VERSION ""

NS_ :

BS_:

BU_: TCM_Diesel ECM_Diesel BECMB_EPM TCM ECM Generic_BCM GWM _delete APIM BCM DCDC_VQM PAM TSTR PCM

BO_ 90 Gear_Shift_by_Wire_HS1: 8 Generic_BCM
 SG_ BrkSwtchPos_B_ActlGsm : 7|1@0+ (1,0) [0|1] "SED"  TCM_Diesel,TCM
 SG_ TrnValidGearRq_D_Stat : 25|2@0+ (1,0) [0|3] "SED"  TCM_Diesel,TCM
 SG_ TrnGearRqCnt_B_Actl : 26|1@0+ (1,0) [0|1] "unitless"  TCM_Diesel,TCM
 SG_ TrnGearButtn_U_Actl : 23|8@0+ (0.05,0) [0|12.7] "VOLT"  TCM_Diesel,TCM
 SG_ TrnGearButtn_B_ActlR2 : 8|1@0+ (1,0) [0|1] "SED"  TCM_Diesel,TCM
 SG_ TrnGearButtn_B_ActlR1 : 9|1@0+ (1,0) [0|1] "SED"  TCM_Diesel,TCM
 SG_ TrnGearButtn_B_ActlR0 : 10|1@0+ (1,0) [0|1] "SED"  TCM_Diesel,TCM
 SG_ TrnGearButtn_B_ActlP2 : 11|1@0+ (1,0) [0|1] "SED"  TCM_Diesel,TCM
 SG_ TrnGearButtn_B_ActlP1 : 12|1@0+ (1,0) [0|1] "SED"  TCM_Diesel,TCM
 SG_ TrnGearButtn_B_ActlP0 : 13|1@0+ (1,0) [0|1] "SED"  TCM_Diesel,TCM
 SG_ TrnGearButtn_B_ActlN2 : 14|1@0+ (1,0) [0|1] "SED"  TCM_Diesel,TCM
 SG_ TrnGearButtn_B_ActlN1 : 15|1@0+ (1,0) [0|1] "SED"  TCM_Diesel,TCM
 SG_ TrnGearButtn_B_ActlN0 : 0|1@0+ (1,0) [0|1] "SED"  TCM_Diesel,TCM
 SG_ TrnGearButtn_B_ActlM2 : 1|1@0+ (1,0) [0|1] "SED"  TCM_Diesel,TCM
 SG_ TrnGearButtn_B_ActlM1 : 2|1@0+ (1,0) [0|1] "SED"  TCM_Diesel,TCM
 SG_ TrnGearButtn_B_ActlM0 : 3|1@0+ (1,0) [0|1] "SED"  TCM_Diesel,TCM
 SG_ TrnGearButtn_B_ActlD2 : 4|1@0+ (1,0) [0|1] "SED"  TCM_Diesel,TCM
 SG_ TrnGearButtn_B_ActlD1 : 5|1@0+ (1,0) [0|1] "SED"  TCM_Diesel,TCM
 SG_ TrnGearButtn_B_ActlD0 : 6|1@0+ (1,0) [0|1] "SED"  TCM_Diesel,TCM
 SG_ TrnGear_No_Cs : 39|8@0+ (1,0) [0|255] "Unitless"  TCM_Diesel,TCM
 SG_ TrnGear_No_Cnt : 47|4@0+ (1,0) [0|15] "Unitless"  TCM_Diesel,TCM
 SG_ TrnBtsiOvrrd_B_Stat : 43|1@0+ (1,0) [0|1] "SED"  TCM_Diesel,TCM
 SG_ DrQltyDrv_D_StatGsm : 42|3@0+ (1,0) [0|7] "SED"  TCM_Diesel,TCM
 SG_ TrnGsmNtmState_D_Actl : 55|2@0+ (1,0) [0|3] "SED"  TCM_Diesel,TCM
 SG_ TrnGear_D_RqDrv : 31|5@0+ (1,0) [0|31] "SED"  TCM_Diesel,TCM,BCM

BO_ 902 BodyGatewayData_HS1: 8 GWM
 SG_ PrmtrAlrmWarnRq_No_Actl_UB : 40|1@0+ (1,0) [0|1] "SED"  BCM
 SG_ PrmtrAlrmTrgRq_No_Actl_UB : 41|1@0+ (1,0) [0|1] "SED"  BCM
 SG_ PrmtrAlrmWarnRq_No_Actl : 63|8@0+ (1,0) [0|255] "unitless"  BCM
 SG_ PrmtrAlrmTrgRq_No_Actl : 55|8@0+ (1,0) [0|255] "unitless"  BCM
 SG_ PrmtrAlrmWarn_B_Rq_UB : 42|1@0+ (1,0) [0|1] "SED"  BCM
 SG_ RollCode_No_ActlRsm_UB : 43|1@0+ (1,0) [0|1] "SED"  BCM
 SG_ PrmtrAlrmTrg_B_Rq_UB : 46|1@0+ (1,0) [0|1] "SED"  BCM
 SG_ PanicRq_No_ActlRsm_UB : 44|1@0+ (1,0) [0|1] "SED"  BCM
 SG_ Panic_D_RqRsm_UB : 0|1@0+ (1,0) [0|1] "SED"  BCM
 SG_ CellLockRq_No_ActlRsm_UB : 45|1@0+ (1,0) [0|1] "SED"  BCM
 SG_ RollCode_No_ActlRsm : 31|16@0+ (1,0) [0|65535] "unitless"  BCM
 SG_ PrmtrAlrmWarn_B_Rq : 47|1@0+ (1,0) [0|1] "SED"  BCM
 SG_ PrmtrAlrmTrg_B_Rq : 2|1@0+ (1,0) [0|1] "SED"  BCM
 SG_ PanicRq_No_ActlRsm : 23|8@0+ (1,0) [0|255] "unitless"  BCM
 SG_ Panic_D_RqRsm : 4|2@0+ (1,0) [0|3] "SED"  BCM
 SG_ CellLockRq_No_ActlRsm : 15|8@0+ (1,0) [0|255] "unitless"  BCM
 SG_ CellLock_D_RqRsm : 7|3@0+ (1,0) [0|7] "SED"  BCM
 SG_ CellLock_D_RqRsm_UB : 1|1@0+ (1,0) [0|1] "SED"  BCM

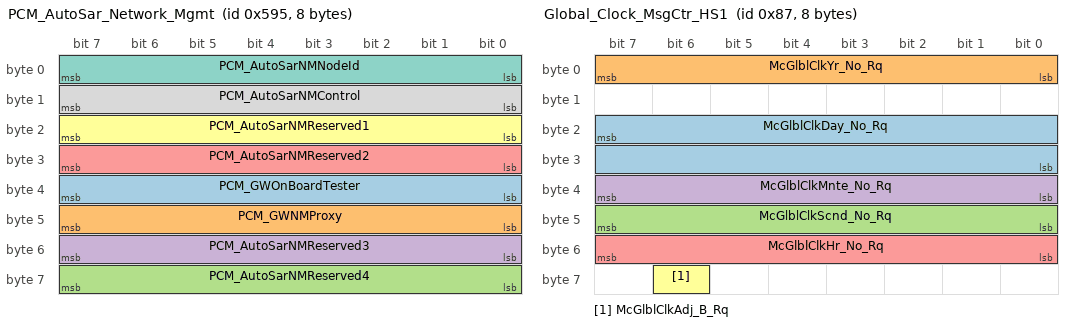
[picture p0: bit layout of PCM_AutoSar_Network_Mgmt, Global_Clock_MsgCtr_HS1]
BO_ 1429 PCM_AutoSar_Network_Mgmt: 8 PCM
 SG_ PCM_GWOnBoardTester : 39|8@0+ (1,0) [0|255] "unitless"  APIM,BCM,BECMB_EPM,GWM,TCM,TCM_Diesel
 SG_ PCM_GWNMProxy : 47|8@0+ (1,0) [0|255] "unitless"  APIM,BCM,BECMB_EPM,GWM,TCM,TCM_Diesel
 SG_ PCM_AutoSarNMReserved4 : 63|8@0+ (1,0) [0|255] "unitless"  APIM,BCM,BECMB_EPM,GWM,TCM,TCM_Diesel
 SG_ PCM_AutoSarNMReserved3 : 55|8@0+ (1,0) [0|255] "unitless"  APIM,BCM,BECMB_EPM,GWM,TCM,TCM_Diesel
 SG_ PCM_AutoSarNMReserved2 : 31|8@0+ (1,0) [0|255] "unitless"  APIM,BCM,BECMB_EPM,GWM,TCM,TCM_Diesel
 SG_ PCM_AutoSarNMReserved1 : 23|8@0+ (1,0) [0|255] "unitless"  APIM,BCM,BECMB_EPM,GWM,TCM,TCM_Diesel
 SG_ PCM_AutoSarNMNodeId : 7|8@0+ (1,0) [0|255] "unitless"  APIM,BCM,BECMB_EPM,GWM,TCM,TCM_Diesel
 SG_ PCM_AutoSarNMControl : 15|8@0+ (1,0) [0|255] "unitless"  APIM,BCM,BECMB_EPM,GWM,TCM,TCM_Diesel

BO_ 740 PHEV_Battery_Data1: 8 Generic_BCM
 SG_ PtWakeupActv2_B_Rq : 55|1@0+ (1,0) [0|1] "SED"  BCM

BO_ 748 BatteryCharge_Data1: 8 Generic_BCM
 SG_ PtWakeupActv3_B_Rq : 34|1@0+ (1,0) [0|1] "SED"  GWM,BCM

BO_ 389 PreCond_Hev_Data2: 8 Generic_BCM
 SG_ PreCondActv_B_Actl : 50|1@0+ (1,0) [0|1] "SED"  BCM,GWM

BO_ 135 Global_Clock_MsgCtr_HS1: 8 GWM
 SG_ McGlblClkDay_No_Rq : 23|16@0+ (1,0) [0|65535] "julian day"  BCM
 SG_ McGlblClkYr_No_Rq : 7|8@0+ (1,2000) [2000|2255] "year"  BCM
 SG_ McGlblClkScnd_No_Rq : 47|8@0+ (1,0) [0|255] "second"  BCM
 SG_ McGlblClkMnte_No_Rq : 39|8@0+ (1,0) [0|255] "minute"  BCM
 SG_ McGlblClkHr_No_Rq : 55|8@0+ (1,0) [0|255] "hour"  BCM
 SG_ McGlblClkAdj_B_Rq : 62|1@0+ (1,0) [0|1] "SED"  BCM

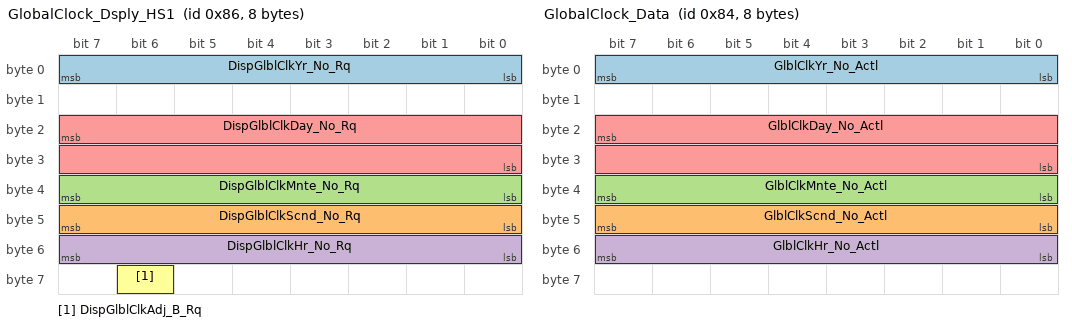
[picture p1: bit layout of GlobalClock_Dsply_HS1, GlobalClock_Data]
BO_ 134 GlobalClock_Dsply_HS1: 8 GWM
 SG_ DispGlblClkYr_No_Rq : 7|8@0+ (1,2000) [2000|2255] "year"  BCM
 SG_ DispGlblClkScnd_No_Rq : 47|8@0+ (1,0) [0|255] "second"  BCM
 SG_ DispGlblClkMnte_No_Rq : 39|8@0+ (1,0) [0|255] "minute"  BCM
 SG_ DispGlblClkHr_No_Rq : 55|8@0+ (1,0) [0|255] "hour"  BCM
 SG_ DispGlblClkDay_No_Rq : 23|16@0+ (1,0) [0|65535] "julian day"  BCM
 SG_ DispGlblClkAdj_B_Rq : 62|1@0+ (1,0) [0|1] "SED"  BCM

BO_ 132 GlobalClock_Data: 8 BCM
 SG_ GlblClkYr_No_Actl : 7|8@0+ (1,2000) [2000|2255] "year"  GWM
 SG_ GlblClkScnd_No_Actl : 47|8@0+ (1,0) [0|255] "second"  GWM
 SG_ GlblClkMnte_No_Actl : 39|8@0+ (1,0) [0|255] "minute"  GWM
 SG_ GlblClkHr_No_Actl : 55|8@0+ (1,0) [0|255] "hour"  GWM
 SG_ GlblClkDay_No_Actl : 23|16@0+ (1,0) [0|65535] "julian day"  GWM

BO_ 836 Climate_Fuel_Req_HS1: 8 GWM
 SG_ Foh_D_Stat : 19|3@0+ (1,0) [0|7] "SED"  BCM

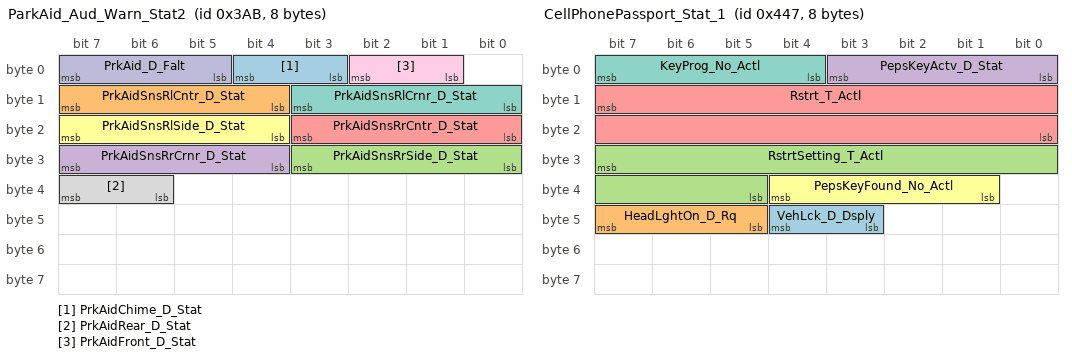
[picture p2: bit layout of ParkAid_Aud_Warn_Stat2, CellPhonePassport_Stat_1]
BO_ 939 ParkAid_Aud_Warn_Stat2: 8 PAM
 SG_ PrkAidChime_D_Stat : 4|2@0+ (1,0) [0|3] "SED"  GWM
 SG_ PrkAidSnsRlCntr_D_Stat : 15|4@0+ (1,0) [0|15] "SED"  BCM,GWM
 SG_ PrkAidSnsRrSide_D_Stat : 27|4@0+ (1,0) [0|15] "SED"  BCM,GWM
 SG_ PrkAidSnsRrCrnr_D_Stat : 31|4@0+ (1,0) [0|15] "SED"  BCM,GWM
 SG_ PrkAidSnsRrCntr_D_Stat : 19|4@0+ (1,0) [0|15] "SED"  BCM,GWM
 SG_ PrkAidSnsRlSide_D_Stat : 23|4@0+ (1,0) [0|15] "SED"  BCM,GWM
 SG_ PrkAidSnsRlCrnr_D_Stat : 11|4@0+ (1,0) [0|15] "SED"  BCM,GWM
 SG_ PrkAidRear_D_Stat : 39|2@0+ (1,0) [0|3] "SED"  GWM
 SG_ PrkAidFront_D_Stat : 2|2@0+ (1,0) [0|3] "SED"  GWM
 SG_ PrkAid_D_Falt : 7|3@0+ (1,0) [0|7] "SED"  BCM,GWM

BO_ 952 Tire_Pressure_Data_DRW: 8 BCM
 SG_ Tire_Press_IRR_Data : 23|16@0+ (1,0) [0|65533] "kilopascal"  GWM
 SG_ Tire_Press_ILR_Data : 7|16@0+ (1,0) [0|65533] "kilopascal"  GWM

BO_ 1095 CellPhonePassport_Stat_1: 8 BCM
 SG_ VehLck_D_Dsply : 44|2@0+ (1,0) [0|3] "SED"  GWM
 SG_ HeadLghtOn_D_Rq : 47|3@0+ (1,0) [0|7] "SED"  GWM
 SG_ RstrtSetting_T_Actl : 31|11@0+ (1,0) [0|2047] "second"  GWM
 SG_ PepsKeyActv_D_Stat : 3|4@0+ (1,0) [0|15] "SED"  GWM
 SG_ Rstrt_T_Actl : 15|16@0+ (1,0) [0|65535] "seconds"  GWM
 SG_ PepsKeyFound_No_Actl : 36|4@0+ (1,0) [0|15] "unitless"  GWM
 SG_ KeyProg_No_Actl : 7|4@0+ (1,0) [0|15] "unitless"  GWM

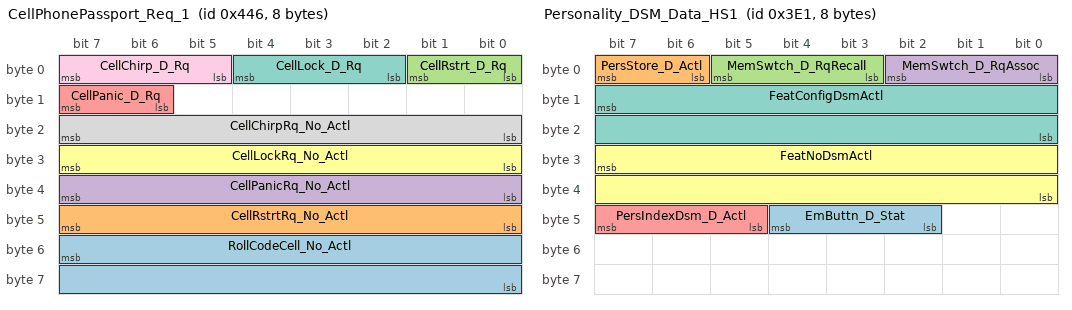
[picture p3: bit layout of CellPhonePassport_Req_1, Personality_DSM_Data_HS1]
BO_ 1094 CellPhonePassport_Req_1: 8 GWM
 SG_ RollCodeCell_No_Actl : 55|16@0+ (1,0) [0|65535] "unitless"  BCM
 SG_ CellRstrtRq_No_Actl : 47|8@0+ (1,0) [0|255] "unitless"  BCM
 SG_ CellRstrt_D_Rq : 1|2@0+ (1,0) [0|3] "SED"  BCM
 SG_ CellPanicRq_No_Actl : 39|8@0+ (1,0) [0|255] "unitless"  BCM
 SG_ CellPanic_D_Rq : 15|2@0+ (1,0) [0|3] "SED"  BCM
 SG_ CellLockRq_No_Actl : 31|8@0+ (1,0) [0|255] "unitless"  BCM
 SG_ CellLock_D_Rq : 4|3@0+ (1,0) [0|7] "SED"  BCM
 SG_ CellChirpRq_No_Actl : 23|8@0+ (1,0) [0|255] "unitless"  BCM
 SG_ CellChirp_D_Rq : 7|3@0+ (1,0) [0|7] "SED"  BCM

BO_ 320 LPwrSlideDr_Stat_HS1: 8 GWM
 SG_ PwSldDrIntSwL_B_Stat : 6|1@0+ (1,0) [0|1] "SED"  BCM
 SG_ LPwrSlideDr_Unlock_Rq : 7|1@0+ (1,0) [0|1] "SED"  BCM

BO_ 313 RPwrSlideDr_Stat_HS1: 8 GWM
 SG_ PwSldDrIntSwR_B_Stat : 6|1@0+ (1,0) [0|1] "SED"  BCM
 SG_ RPwrSlideDr_Unlock_Rq : 7|1@0+ (1,0) [0|1] "SED"  BCM

BO_ 993 Personality_DSM_Data_HS1: 8 GWM
 SG_ EmButtn_D_Stat : 44|3@0+ (1,0) [0|7] "SED" Vector__XXX
 SG_ PersStore_D_Actl : 7|2@0+ (1,0) [0|3] "SED" Vector__XXX
 SG_ MemSwtch_D_RqRecall : 5|3@0+ (1,0) [0|7] "SED"  BCM
 SG_ MemSwtch_D_RqAssoc : 2|3@0+ (1,0) [0|7] "SED"  BCM
 SG_ PersIndexDsm_D_Actl : 47|3@0+ (1,0) [0|7] "SED" Vector__XXX
 SG_ FeatNoDsmActl : 31|16@0+ (1,0) [0|65535] "Number" Vector__XXX
 SG_ FeatConfigDsmActl : 15|16@0+ (1,0) [0|65535] "Undefined" Vector__XXX

BO_ 131 Steering_Data_HS1: 8 GWM
 SG_ WiprFrontSwtch_D_Stat : 47|4@0+ (1,0) [0|15] "SED" Vector__XXX
 SG_ HeadLghtHiCtrl_D_RqAhb : 43|3@0+ (1,0) [0|7] "SED"  BCM
 SG_ HeadLghtHiOn_B_StatAhb : 34|1@0+ (1,0) [0|1] "SED" Vector__XXX
 SG_ AhbStat_B_Dsply : 33|1@0+ (1,0) [0|1] "SED" Vector__XXX
 SG_ HeadLghtHiFlash_D_Actl : 36|2@0+ (1,0) [0|3] "SED" Vector__XXX
 SG_ AccButtnGapIncPress : 11|1@0+ (1,0) [0|1] "SED" Vector__XXX
 SG_ AccButtnGapDecPress : 12|1@0+ (1,0) [0|1] "SED" Vector__XXX
 SG_ AslButtnOnOffPress : 9|1@0+ (1,0) [0|1] "SED"  ECM_Diesel,ECM,PCM
 SG_ AslButtnOnOffCnclPress : 10|1@0+ (1,0) [0|1] "SED"  ECM_Diesel,ECM,PCM
 SG_ CcButtnOnPress : 37|1@0+ (1,0) [0|1] "SED"  ECM_Diesel,ECM,PCM
 SG_ CcButtnOnOffPress : 38|1@0+ (1,0) [0|1] "SED"  ECM_Diesel,ECM,PCM
 SG_ CcButtnOnOffCnclPress : 39|1@0+ (1,0) [0|1] "SED"  ECM_Diesel,ECM,PCM
 SG_ CcButtnOffPress : 24|1@0+ (1,0) [0|1] "SED"  ECM_Diesel,ECM,PCM
 SG_ CcAsllButtnResPress : 25|1@0+ (1,0) [0|1] "SED"  ECM_Diesel,ECM,PCM
 SG_ CcAslButtnSetPress : 26|1@0+ (1,0) [0|1] "SED"  ECM_Diesel
 SG_ CcAslButtnSetIncPress : 27|1@0+ (1,0) [0|1] "SED"  ECM_Diesel,ECM,PCM
 SG_ CcAslButtnSetDecPress : 28|1@0+ (1,0) [0|1] "SED"  ECM_Diesel,ECM,PCM
 SG_ CcAslButtnResIncPress : 29|1@0+ (1,0) [0|1] "SED"  ECM_Diesel,ECM,PCM
 SG_ CcAslButtnResDecPress : 30|1@0+ (1,0) [0|1] "SED" Vector__XXX
 SG_ CcAslButtnOnPress : 31|1@0+ (1,0) [0|1] "SED"  ECM_Diesel,ECM,PCM
 SG_ CcAslButtnOnOffCncl : 16|1@0+ (1,0) [0|1] "SED" Vector__XXX
 SG_ CcAslButtnOffCnclPress : 17|1@0+ (1,0) [0|1] "SED" Vector__XXX
 SG_ CcAslButtnIndxIncPress : 18|1@0+ (1,0) [0|1] "SED"  ECM_Diesel,ECM,PCM
 SG_ CcAslButtnIndxDecPress : 19|1@0+ (1,0) [0|1] "SED"  ECM_Diesel,ECM,PCM
 SG_ CcAslButtnDeny_B_Actl : 20|1@0+ (1,0) [0|1] "SED"  ECM_Diesel,ECM,PCM
 SG_ CcAslButtnCnclResPress : 21|1@0+ (1,0) [0|1] "SED"  ECM_Diesel,ECM,PCM
 SG_ CcAslButtnCnclPress : 8|1@0+ (1,0) [0|1] "SED"  ECM_Diesel,ECM,PCM
 SG_ HeadLghtHiFlash_D_Stat : 7|2@0+ (1,0) [0|3] "SED"  BCM
 SG_ WiprFront_D_Stat : 3|4@0+ (1,0) [0|15] "SED"  ECM_Diesel,ECM,PCM,BCM
 SG_ TurnLghtSwtch_D_Stat : 5|2@0+ (1,0) [0|3] "SED"  BCM,PAM
 SG_ LghtAmb_D_Sns : 15|3@0+ (1,0) [0|7] "SED"  BCM
 SG_ LaSwtchPos_D_Stat : 23|2@0+ (1,0) [0|3] "SED" Vector__XXX

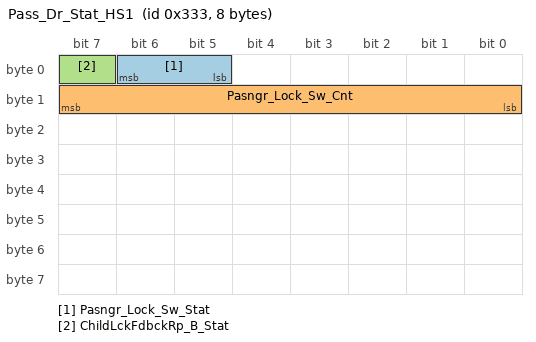
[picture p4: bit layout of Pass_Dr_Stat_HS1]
BO_ 819 Pass_Dr_Stat_HS1: 8 GWM
 SG_ Pasngr_Lock_Sw_Stat : 6|2@0+ (1,0) [0|3] "SED"  BCM
 SG_ Pasngr_Lock_Sw_Cnt : 15|8@0+ (1,0) [0|255] "Cnt"  BCM
 SG_ ChildLckFdbckRp_B_Stat : 7|1@0+ (1,0) [0|1] "SED"  BCM

BO_TX_BU_ 1429 : ECM_Diesel,ECM,PCM;
CM_ SG_ 90 BrkSwtchPos_B_ActlGsm "Signal not transmitted on vehicles that do not have shift by wire.";
CM_ SG_ 90 TrnValidGearRq_D_Stat "Signal not transmitted on vehicles that do not have shift by wire.";
CM_ SG_ 90 TrnGearRqCnt_B_Actl "Signal not transmitted on vehicles that do not have shift by wire.";
CM_ SG_ 90 TrnGearButtn_U_Actl "Signal not transmitted on vehicles that do not have shift by wire.";
CM_ SG_ 90 TrnGearButtn_B_ActlR2 "Signal not transmitted on vehicles that do not have shift by wire.";
CM_ SG_ 90 TrnGearButtn_B_ActlR1 "Signal not transmitted on vehicles that do not have shift by wire.";
CM_ SG_ 90 TrnGearButtn_B_ActlR0 "Signal not transmitted on vehicles that do not have shift by wire.";
CM_ SG_ 90 TrnGearButtn_B_ActlP2 "Signal not transmitted on vehicles that do not have shift by wire.";
CM_ SG_ 90 TrnGearButtn_B_ActlP1 "Signal not transmitted on vehicles that do not have shift by wire.";
CM_ SG_ 90 TrnGearButtn_B_ActlP0 "Signal not transmitted on vehicles that do not have shift by wire.";
CM_ SG_ 90 TrnGearButtn_B_ActlN2 "Signal not transmitted on vehicles that do not have shift by wire.";
CM_ SG_ 90 TrnGearButtn_B_ActlN1 "Signal not transmitted on vehicles that do not have shift by wire.";
CM_ SG_ 90 TrnGearButtn_B_ActlN0 "Signal not transmitted on vehicles that do not have shift by wire.";
CM_ SG_ 90 TrnGearButtn_B_ActlM2 "Signal not transmitted on vehicles that do not have shift by wire.";
CM_ SG_ 90 TrnGearButtn_B_ActlM1 "Signal not transmitted on vehicles that do not have shift by wire.";
CM_ SG_ 90 TrnGearButtn_B_ActlM0 "Signal not transmitted on vehicles that do not have shift by wire.";
CM_ SG_ 90 TrnGearButtn_B_ActlD2 "Signal not transmitted on vehicles that do not have shift by wire.";
CM_ SG_ 90 TrnGearButtn_B_ActlD1 "Signal not transmitted on vehicles that do not have shift by wire.";
CM_ SG_ 90 TrnGearButtn_B_ActlD0 "Signal not transmitted on vehicles that do not have shift by wire.";
CM_ SG_ 90 TrnGear_No_Cs "Signal not transmitted on vehicles that do not have shift by wire.";
CM_ SG_ 90 TrnGear_No_Cnt "Signal not transmitted on vehicles that do not have shift by wire.";
CM_ SG_ 90 TrnBtsiOvrrd_B_Stat "Signal not transmitted on vehicles that do not have shift by wire.";
CM_ SG_ 90 DrQltyDrv_D_StatGsm "Signal not transmitted on vehicles that do not have shift by wire.";
CM_ SG_ 90 TrnGsmNtmState_D_Actl "Signal not transmitted on vehicles that do not have shift by wire.";
CM_ SG_ 90 TrnGear_D_RqDrv "Signal not transmitted on vehicles that do not have shift by wire.";
CM_ SG_ 836 Foh_D_Stat "Signal not transmitted on vehicles that do not have the Fuel operated heater feature.";
CM_ SG_ 320 PwSldDrIntSwL_B_Stat "Signal not transmitted on vehicles without power sliding doors.";
CM_ SG_ 320 LPwrSlideDr_Unlock_Rq "Signal not transmitted on vehicles without power sliding doors.";
CM_ SG_ 313 PwSldDrIntSwR_B_Stat "Signal not transmitted on vehicles without power sliding doors.";
CM_ SG_ 313 RPwrSlideDr_Unlock_Rq "Signal not transmitted on vehicles without power sliding doors.";
BA_DEF_ SG_  "U_D568C_MY19_Gas_Rx" ENUM  "No","Yes";
BA_DEF_ SG_  "U_CD4_MY19_Diesel_Rx" ENUM  "No","Yes";
BA_DEF_ SG_  "U_CD4_MY19_Gas_Rx" ENUM  "No","Yes";
BA_DEF_ SG_  "U_CD4_MY19_Hev_Rx" ENUM  "No","Yes";
BA_DEF_ SG_  "U_CD4_MY19_Phev_Rx" ENUM  "No","Yes";
BA_DEF_ SG_  "U_V36X_MY19_Rx" ENUM  "No","Yes";
BA_DEF_ SG_  "U_D568C_MY19_Gas_Tx" ENUM  "No","Yes";
BA_DEF_ SG_  "U_CD4_MY19_Diesel_Tx" ENUM  "No","Yes";
BA_DEF_ SG_  "U_V36X_MY19_Tx" ENUM  "No","Yes";
BA_DEF_ SG_  "U_V36X_MY18_5_Gas_Rx" ENUM  "No","Yes";
BA_DEF_ SG_  "U_V36X_MY18_5_Hev_Rx" ENUM  "No","Yes";
BA_DEF_ SG_  "U_V36X_MY18_5_Gas_Tx" ENUM  "No","Yes";
BA_DEF_ SG_  "U_V36X_MY18_5_Hev_Tx" ENUM  "No","Yes";
BA_DEF_ SG_  "U_V36X_MY19_5_Diesel_Rx" ENUM  "No","Yes";
BA_DEF_ SG_  "U_V363E_N_MY19_5_20_Gas_Rx" ENUM  "No","Yes";
BA_DEF_ SG_  "U_V363E_N_MY19_5_20_Diesel_Rx" ENUM  "No","Yes";
BA_DEF_ SG_  "U_CD42_MY19_Diesel_Rx" ENUM  "No","Yes";
BA_DEF_ SG_  "U_V36X_MY19_5_Diesel_Tx" ENUM  "No","Yes";
BA_DEF_ SG_  "U_V363E_N_MY19_5_20_Gas_Tx" ENUM  "No","Yes";
BA_DEF_ SG_  "U_V363E_N_MY19_5_20_Diesel_Tx" ENUM  "No","Yes";
BA_DEF_ SG_  "U_CD42_MY19_Diesel_Tx" ENUM  "No","Yes";
BA_DEF_ SG_  "U_CD42_MY19_Gas_Tx" ENUM  "No","Yes";
BA_DEF_ SG_  "U_U502_MY17_Gas_Rx" ENUM  "No","Yes";
BA_DEF_ SG_  "U_CD4_MY18_Diesel_Rx" ENUM  "No","Yes";
BA_DEF_ SG_  "U_CD4_MY18_Gas_Rx" ENUM  "No","Yes";
BA_DEF_ SG_  "U_CD4_MY18_Hev_Rx" ENUM  "No","Yes";
BA_DEF_ SG_  "U_CD4_MY18_Phev_Rx" ENUM  "No","Yes";
BA_DEF_ SG_  "U_S550_MY18_Gas_Rx" ENUM  "No","Yes";
BA_DEF_ SG_  "U_V408_MY18_Gas_Rx" ENUM  "No","Yes";
BA_DEF_ SG_  "U_V408_MY18_Diesel_Rx" ENUM  "No","Yes";
BA_DEF_ SG_  "U_V36X_MY18_5_Diesel_Rx" ENUM  "No","Yes";
BA_DEF_ SG_  "U_P552_MY18_5_Gas_Rx" ENUM  "No","Yes";
BA_DEF_ SG_  "U_P552_MY18_5_Diesel_Rx" ENUM  "No","Yes";
BA_DEF_ SG_  "U_U502_MY17_Gas_Tx" ENUM  "No","Yes";
BA_DEF_ SG_  "U_CD4_MY18_Diesel_Tx" ENUM  "No","Yes";
BA_DEF_ SG_  "U_CD4_MY18_Gas_Tx" ENUM  "No","Yes";
BA_DEF_ SG_  "U_CD4_MY18_Hev_Tx" ENUM  "No","Yes";
BA_DEF_ SG_  "U_CD4_MY18_Phev_Tx" ENUM  "No","Yes";
BA_DEF_ SG_  "U_S550_MY18_Gas_Tx" ENUM  "No","Yes";
BA_DEF_ SG_  "U_V408_MY18_Gas_Tx" ENUM  "No","Yes";
BA_DEF_ SG_  "U_V408_MY18_Diesel_Tx" ENUM  "No","Yes";
BA_DEF_ SG_  "U_V36X_MY18_5_Diesel_Tx" ENUM  "No","Yes";
BA_DEF_ SG_  "U_P552_MY18_5_Gas_Tx" ENUM  "No","Yes";
BA_DEF_ SG_  "U_P552_MY18_5_Diesel_Tx" ENUM  "No","Yes";
BA_DEF_ SG_  "U_U55x_MY18_Gas_Rx" ENUM  "No","Yes";
BA_DEF_ SG_  "U_P552_MY18_Gas_Tx" ENUM  "No","Yes";
BA_DEF_ SG_  "U_U55x_MY18_Gas_Tx" ENUM  "No","Yes";
BA_DEF_ BO_  "FrameGatewayNetwork" STRING ;
BA_DEF_ SG_  "U_C489_MY17_Gas_Rx" ENUM  "No","Yes";
BA_DEF_ SG_  "U_CD43_MY17_Gas_Rx" ENUM  "No","Yes";
BA_DEF_ SG_  "U_CD43_MY17_Gas_Tx" ENUM  "No","Yes";
BA_DEF_ SG_  "U_P552_MY17_Gas_Tx" ENUM  "No","Yes";
BA_DEF_ SG_  "U_CD4_MY17_Diesel_Rx" ENUM  "No","Yes";
BA_DEF_ SG_  "U_CD4_MY17_Gas_Rx" ENUM  "No","Yes";
BA_DEF_ SG_  "U_CD4_MY17_Hev_Rx" ENUM  "No","Yes";
BA_DEF_ SG_  "U_C489_MY16_Gas_Rx" ENUM  "No","Yes";
BA_DEF_ SG_  "U_CD42_MY16_Diesel_Rx" ENUM  "No","Yes";
BA_DEF_ SG_  "U_CD42_MY16_Gas_Rx" ENUM  "No","Yes";
BA_DEF_ SG_  "U_CD42_MY15_Diesel_Rx" ENUM  "No","Yes";
BA_DEF_ SG_  "U_CD42_MY15_Gas_Rx" ENUM  "No","Yes";
BA_DEF_ SG_  "U_P558_MY17_Gas_Rx" ENUM  "No","Yes";
BA_DEF_ SG_  "U_P558_MY17_Diesel_Rx" ENUM  "No","Yes";
BA_DEF_ SG_  "U_P558_MY17_Gas_Tx" ENUM  "No","Yes";
BA_DEF_ SG_  "U_P558_MY17_Diesel_Tx" ENUM  "No","Yes";
BA_DEF_ SG_  "GenSigTimeoutTime_TCM" INT 0 100000;
BA_DEF_ BO_  "FrameGatewayMS1" HEX 0 1407;
BA_DEF_ BO_  "FrameGatewayHS3" HEX 0 1407;
BA_DEF_ BO_  "FrameGatewayHS2" HEX 0 1407;
BA_DEF_ BO_  "NetworkInitialization" ENUM  "No","Yes";
BA_DEF_ BO_  "FrameGatewayId" HEX 0 1407;
BA_DEF_ BO_  "GenMsgStartDelayTime" INT 0 10000;
BA_DEF_ BO_  "GenMsgCycleTime" INT 0 100000;
BA_DEF_ BO_  "GenMsgSendType" ENUM  "FixedPeriodic","Event","EnabledPeriodic","NotUsed","NotUsed","EventPeriodic","NotUsed","NotUsed","NoMsgSendType";
BA_DEF_ SG_  "U_CD4_MY14_Phev_Tx" ENUM  "No","Yes";
BA_DEF_ SG_  "U_CD4_MY14_Hev_Tx" ENUM  "No","Yes";
BA_DEF_ SG_  "U_CD4_MY14_Gas_Tx" ENUM  "No","Yes";
BA_DEF_ SG_  "U_CD4_MY14_Diesel_Tx" ENUM  "No","Yes";
BA_DEF_ SG_  "U_CD43_MY16_Gas_Tx" ENUM  "No","Yes";
BA_DEF_ SG_  "U_UP375_MY15_Diesel_Tx" ENUM  "No","Yes";
BA_DEF_ SG_  "U_UP375_MY15_Gas_Tx" ENUM  "No","Yes";
BA_DEF_ SG_  "U_U502_MY15_Gas_Tx" ENUM  "No","Yes";
BA_DEF_ SG_  "U_C489_MY14_Gas_Tx" ENUM  "No","Yes";
BA_DEF_ SG_  "U_S550_MY15_Gas_Tx" ENUM  "No","Yes";
BA_DEF_ SG_  "U_P552_MY15_Gas_Tx" ENUM  "No","Yes";
BA_DEF_ SG_  "U_CD42_MY14_Gas_Tx" ENUM  "No","Yes";
BA_DEF_ SG_  "U_CD42_MY14_Diesel_Tx" ENUM  "No","Yes";
BA_DEF_ SG_  "U_CD4_MY13_Phev_Tx" ENUM  "No","Yes";
BA_DEF_ SG_  "U_CD4_MY13_Hev_Tx" ENUM  "No","Yes";
BA_DEF_ SG_  "U_CD4_MY13_Gas_Tx" ENUM  "No","Yes";
BA_DEF_ SG_  "U_CD4_MY13_Diesel_Tx" ENUM  "No","Yes";
BA_DEF_ SG_  "U_CD4_MY14_Phev_Rx" ENUM  "No","Yes";
BA_DEF_ SG_  "U_CD4_MY14_Hev_Rx" ENUM  "No","Yes";
BA_DEF_ SG_  "U_CD4_MY14_Gas_Rx" ENUM  "No","Yes";
BA_DEF_ SG_  "U_CD4_MY14_Diesel_Rx" ENUM  "No","Yes";
BA_DEF_ SG_  "U_CD43_MY16_Gas_Rx" ENUM  "No","Yes";
BA_DEF_ SG_  "U_UP375_MY15_Diesel_Rx" ENUM  "No","Yes";
BA_DEF_ SG_  "U_UP375_MY15_Gas_Rx" ENUM  "No","Yes";
BA_DEF_ SG_  "U_U502_MY15_Gas_Rx" ENUM  "No","Yes";
BA_DEF_ SG_  "U_C489_MY14_Gas_Rx" ENUM  "No","Yes";
BA_DEF_ SG_  "U_S550_MY15_Gas_Rx" ENUM  "No","Yes";
BA_DEF_ SG_  "U_P552_MY15_Gas_Rx" ENUM  "No","Yes";
BA_DEF_ SG_  "U_CD42_MY14_Gas_Rx" ENUM  "No","Yes";
BA_DEF_ SG_  "U_CD42_MY14_Diesel_Rx" ENUM  "No","Yes";
BA_DEF_ SG_  "U_CD4_MY13_Phev_Rx" ENUM  "No","Yes";
BA_DEF_ SG_  "U_CD4_MY13_Hev_Rx" ENUM  "No","Yes";
BA_DEF_ SG_  "U_CD4_MY13_Gas_Rx" ENUM  "No","Yes";
BA_DEF_ SG_  "U_CD4_MY13_Diesel_Rx" ENUM  "No","Yes";
BA_DEF_ SG_  "ContentDependant" ENUM  "No","Yes";
BA_DEF_ SG_  "GenSigStartValue" INT 0 1000000000;
BA_DEF_ SG_  "CrossOver_InfoCAN" ENUM  "No","Yes";
BA_DEF_ SG_  "WakeupSignal" ENUM  "No","Yes";
BA_DEF_ SG_  "GenSigSendType" ENUM  "Cyclic","OnWrite","vector_leerstring","OnChange","vector_leerstring","IfActive","vector_leerstring","NoSigSendType";
BA_DEF_ BO_  "NmAsrMessage" ENUM  "No","Yes";
BA_DEF_ BO_  "GenMsgILSupport" ENUM  "No","Yes";
BA_DEF_DEF_  "U_D568C_MY19_Gas_Rx" "No";
BA_DEF_DEF_  "U_CD4_MY19_Diesel_Rx" "No";
BA_DEF_DEF_  "U_CD4_MY19_Gas_Rx" "No";
BA_DEF_DEF_  "U_CD4_MY19_Hev_Rx" "No";
BA_DEF_DEF_  "U_CD4_MY19_Phev_Rx" "No";
BA_DEF_DEF_  "U_V36X_MY19_Rx" "No";
BA_DEF_DEF_  "U_D568C_MY19_Gas_Tx" "No";
BA_DEF_DEF_  "U_CD4_MY19_Diesel_Tx" "No";
BA_DEF_DEF_  "U_V36X_MY19_Tx" "No";
BA_DEF_DEF_  "U_V36X_MY18_5_Gas_Rx" "No";
BA_DEF_DEF_  "U_V36X_MY18_5_Hev_Rx" "No";
BA_DEF_DEF_  "U_V36X_MY18_5_Gas_Tx" "No";
BA_DEF_DEF_  "U_V36X_MY18_5_Hev_Tx" "No";
BA_DEF_DEF_  "U_V36X_MY19_5_Diesel_Rx" "No";
BA_DEF_DEF_  "U_V363E_N_MY19_5_20_Gas_Rx" "No";
BA_DEF_DEF_  "U_V363E_N_MY19_5_20_Diesel_Rx" "No";
BA_DEF_DEF_  "U_CD42_MY19_Diesel_Rx" "No";
BA_DEF_DEF_  "U_V36X_MY19_5_Diesel_Tx" "No";
BA_DEF_DEF_  "U_V363E_N_MY19_5_20_Gas_Tx" "No";
BA_DEF_DEF_  "U_V363E_N_MY19_5_20_Diesel_Tx" "No";
BA_DEF_DEF_  "U_CD42_MY19_Diesel_Tx" "No";
BA_DEF_DEF_  "U_CD42_MY19_Gas_Tx" "No";
BA_DEF_DEF_  "U_U502_MY17_Gas_Rx" "No";
BA_DEF_DEF_  "U_CD4_MY18_Diesel_Rx" "No";
BA_DEF_DEF_  "U_CD4_MY18_Gas_Rx" "No";
BA_DEF_DEF_  "U_CD4_MY18_Hev_Rx" "No";
BA_DEF_DEF_  "U_CD4_MY18_Phev_Rx" "No";
BA_DEF_DEF_  "U_S550_MY18_Gas_Rx" "No";
BA_DEF_DEF_  "U_V408_MY18_Gas_Rx" "No";
BA_DEF_DEF_  "U_V408_MY18_Diesel_Rx" "No";
BA_DEF_DEF_  "U_V36X_MY18_5_Diesel_Rx" "No";
BA_DEF_DEF_  "U_P552_MY18_5_Gas_Rx" "No";
BA_DEF_DEF_  "U_P552_MY18_5_Diesel_Rx" "No";
BA_DEF_DEF_  "U_U502_MY17_Gas_Tx" "No";
BA_DEF_DEF_  "U_CD4_MY18_Diesel_Tx" "No";
BA_DEF_DEF_  "U_CD4_MY18_Gas_Tx" "No";
BA_DEF_DEF_  "U_CD4_MY18_Hev_Tx" "No";
BA_DEF_DEF_  "U_CD4_MY18_Phev_Tx" "No";
BA_DEF_DEF_  "U_S550_MY18_Gas_Tx" "No";
BA_DEF_DEF_  "U_V408_MY18_Gas_Tx" "No";
BA_DEF_DEF_  "U_V408_MY18_Diesel_Tx" "No";
BA_DEF_DEF_  "U_V36X_MY18_5_Diesel_Tx" "No";
BA_DEF_DEF_  "U_P552_MY18_5_Gas_Tx" "No";
BA_DEF_DEF_  "U_P552_MY18_5_Diesel_Tx" "No";
BA_DEF_DEF_  "U_U55x_MY18_Gas_Rx" "No";
BA_DEF_DEF_  "U_P552_MY18_Gas_Tx" "No";
BA_DEF_DEF_  "U_U55x_MY18_Gas_Tx" "No";
BA_DEF_DEF_  "FrameGatewayNetwork" "NONE";
BA_DEF_DEF_  "U_C489_MY17_Gas_Rx" "No";
BA_DEF_DEF_  "U_CD43_MY17_Gas_Rx" "No";
BA_DEF_DEF_  "U_CD43_MY17_Gas_Tx" "No";
BA_DEF_DEF_  "U_P552_MY17_Gas_Tx" "No";
BA_DEF_DEF_  "U_CD4_MY17_Diesel_Rx" "No";
BA_DEF_DEF_  "U_CD4_MY17_Gas_Rx" "No";
BA_DEF_DEF_  "U_CD4_MY17_Hev_Rx" "No";
BA_DEF_DEF_  "U_C489_MY16_Gas_Rx" "No";
BA_DEF_DEF_  "U_CD42_MY16_Diesel_Rx" "No";
BA_DEF_DEF_  "U_CD42_MY16_Gas_Rx" "No";
BA_DEF_DEF_  "U_CD42_MY15_Diesel_Rx" "No";
BA_DEF_DEF_  "U_CD42_MY15_Gas_Rx" "No";
BA_DEF_DEF_  "U_P558_MY17_Gas_Rx" "No";
BA_DEF_DEF_  "U_P558_MY17_Diesel_Rx" "No";
BA_DEF_DEF_  "U_P558_MY17_Gas_Tx" "No";
BA_DEF_DEF_  "U_P558_MY17_Diesel_Tx" "No";
BA_DEF_DEF_  "GenSigTimeoutTime_TCM" 5000;
BA_DEF_DEF_  "FrameGatewayMS1" 0;
BA_DEF_DEF_  "FrameGatewayHS3" 0;
BA_DEF_DEF_  "FrameGatewayHS2" 0;
BA_DEF_DEF_  "NetworkInitialization" "No";
BA_DEF_DEF_  "FrameGatewayId" 0;
BA_DEF_DEF_  "GenMsgStartDelayTime" 0;
BA_DEF_DEF_  "GenMsgCycleTime" 0;
BA_DEF_DEF_  "GenMsgSendType" "NoMsgSendType";
BA_DEF_DEF_  "U_CD4_MY14_Phev_Tx" "No";
BA_DEF_DEF_  "U_CD4_MY14_Hev_Tx" "No";
BA_DEF_DEF_  "U_CD4_MY14_Gas_Tx" "No";
BA_DEF_DEF_  "U_CD4_MY14_Diesel_Tx" "No";
BA_DEF_DEF_  "U_CD43_MY16_Gas_Tx" "No";
BA_DEF_DEF_  "U_UP375_MY15_Diesel_Tx" "No";
BA_DEF_DEF_  "U_UP375_MY15_Gas_Tx" "No";
BA_DEF_DEF_  "U_U502_MY15_Gas_Tx" "No";
BA_DEF_DEF_  "U_C489_MY14_Gas_Tx" "No";
BA_DEF_DEF_  "U_S550_MY15_Gas_Tx" "No";
BA_DEF_DEF_  "U_P552_MY15_Gas_Tx" "No";
BA_DEF_DEF_  "U_CD42_MY14_Gas_Tx" "No";
BA_DEF_DEF_  "U_CD42_MY14_Diesel_Tx" "No";
BA_DEF_DEF_  "U_CD4_MY13_Phev_Tx" "No";
BA_DEF_DEF_  "U_CD4_MY13_Hev_Tx" "No";
BA_DEF_DEF_  "U_CD4_MY13_Gas_Tx" "No";
BA_DEF_DEF_  "U_CD4_MY13_Diesel_Tx" "No";
BA_DEF_DEF_  "U_CD4_MY14_Phev_Rx" "No";
BA_DEF_DEF_  "U_CD4_MY14_Hev_Rx" "No";
BA_DEF_DEF_  "U_CD4_MY14_Gas_Rx" "No";
BA_DEF_DEF_  "U_CD4_MY14_Diesel_Rx" "No";
BA_DEF_DEF_  "U_CD43_MY16_Gas_Rx" "No";
BA_DEF_DEF_  "U_UP375_MY15_Diesel_Rx" "No";
BA_DEF_DEF_  "U_UP375_MY15_Gas_Rx" "No";
BA_DEF_DEF_  "U_U502_MY15_Gas_Rx" "No";
BA_DEF_DEF_  "U_C489_MY14_Gas_Rx" "No";
BA_DEF_DEF_  "U_S550_MY15_Gas_Rx" "No";
BA_DEF_DEF_  "U_P552_MY15_Gas_Rx" "No";
BA_DEF_DEF_  "U_CD42_MY14_Gas_Rx" "No";
BA_DEF_DEF_  "U_CD42_MY14_Diesel_Rx" "No";
BA_DEF_DEF_  "U_CD4_MY13_Phev_Rx" "No";
BA_DEF_DEF_  "U_CD4_MY13_Hev_Rx" "No";
BA_DEF_DEF_  "U_CD4_MY13_Gas_Rx" "No";
BA_DEF_DEF_  "U_CD4_MY13_Diesel_Rx" "No";
BA_DEF_DEF_  "ContentDependant" "No";
BA_DEF_DEF_  "GenSigStartValue" 0;
BA_DEF_DEF_  "CrossOver_InfoCAN" "No";
BA_DEF_DEF_  "WakeupSignal" "No";
BA_DEF_DEF_  "GenSigSendType" "NoSigSendType";
BA_DEF_DEF_  "NmAsrMessage" "No";
BA_DEF_DEF_  "GenMsgILSupport" "Yes";
BA_ "FrameGatewayHS2" BO_ 90 90;
BA_ "FrameGatewayId" BO_ 90 90;
BA_ "NetworkInitialization" BO_ 90 1;
BA_ "GenMsgSendType" BO_ 902 5;
BA_ "GenMsgCycleTime" BO_ 902 1000;
BA_ "GenMsgILSupport" BO_ 1429 0;
BA_ "NmAsrMessage" BO_ 1429 1;
BA_ "GenMsgSendType" BO_ 1429 0;
BA_ "GenMsgCycleTime" BO_ 1429 1000;
BA_ "FrameGatewayNetwork" BO_ 135 "HS3_CAN";
BA_ "GenMsgStartDelayTime" BO_ 135 100;
BA_ "FrameGatewayId" BO_ 135 135;
BA_ "FrameGatewayHS3" BO_ 135 135;
BA_ "FrameGatewayNetwork" BO_ 134 "HS3_CAN";
BA_ "GenMsgStartDelayTime" BO_ 134 100;
BA_ "FrameGatewayId" BO_ 134 134;
BA_ "FrameGatewayHS3" BO_ 134 134;
BA_ "GenMsgSendType" BO_ 132 1;
BA_ "FrameGatewayNetwork" BO_ 836 "MS1_CAN";
BA_ "GenMsgStartDelayTime" BO_ 836 100;
BA_ "FrameGatewayId" BO_ 836 836;
BA_ "FrameGatewayMS1" BO_ 836 836;
BA_ "GenMsgSendType" BO_ 939 5;
BA_ "GenMsgCycleTime" BO_ 939 200;
BA_ "GenMsgSendType" BO_ 952 0;
BA_ "GenMsgCycleTime" BO_ 952 500;
BA_ "GenMsgSendType" BO_ 1095 5;
BA_ "GenMsgCycleTime" BO_ 1095 1000;
BA_ "NetworkInitialization" BO_ 1095 1;
BA_ "FrameGatewayNetwork" BO_ 1094 "HS3_CAN";
BA_ "FrameGatewayId" BO_ 1094 1094;
BA_ "FrameGatewayHS3" BO_ 1094 1094;
BA_ "FrameGatewayNetwork" BO_ 320 "MS1_CAN";
BA_ "FrameGatewayId" BO_ 320 320;
BA_ "FrameGatewayMS1" BO_ 320 320;
BA_ "FrameGatewayNetwork" BO_ 313 "MS1_CAN";
BA_ "FrameGatewayId" BO_ 313 313;
BA_ "FrameGatewayMS1" BO_ 313 313;
BA_ "NetworkInitialization" BO_ 993 1;
BA_ "FrameGatewayNetwork" BO_ 993 "MS1_CAN";
BA_ "FrameGatewayId" BO_ 993 993;
BA_ "FrameGatewayMS1" BO_ 993 993;
BA_ "FrameGatewayNetwork" BO_ 131 "HS2_CAN";
BA_ "GenMsgStartDelayTime" BO_ 131 100;
BA_ "FrameGatewayId" BO_ 131 131;
BA_ "FrameGatewayHS2" BO_ 131 131;
BA_ "NetworkInitialization" BO_ 131 1;
BA_ "FrameGatewayNetwork" BO_ 819 "MS1_CAN";
BA_ "GenMsgStartDelayTime" BO_ 819 100;
BA_ "FrameGatewayId" BO_ 819 819;
BA_ "FrameGatewayMS1" BO_ 819 819;
BA_ "U_CD42_MY19_Diesel_Rx" SG_ 90 BrkSwtchPos_B_ActlGsm 1;
BA_ "U_CD4_MY18_Gas_Rx" SG_ 90 BrkSwtchPos_B_ActlGsm 1;
BA_ "U_U55x_MY18_Gas_Rx" SG_ 90 BrkSwtchPos_B_ActlGsm 1;
BA_ "U_CD43_MY17_Gas_Rx" SG_ 90 BrkSwtchPos_B_ActlGsm 1;
BA_ "U_CD42_MY16_Gas_Rx" SG_ 90 BrkSwtchPos_B_ActlGsm 1;
BA_ "U_C489_MY17_Gas_Rx" SG_ 90 BrkSwtchPos_B_ActlGsm 1;
BA_ "U_CD4_MY17_Hev_Rx" SG_ 90 BrkSwtchPos_B_ActlGsm 1;
BA_ "U_CD4_MY17_Gas_Rx" SG_ 90 BrkSwtchPos_B_ActlGsm 1;
BA_ "U_CD4_MY14_Hev_Rx" SG_ 90 BrkSwtchPos_B_ActlGsm 1;
BA_ "U_CD4_MY14_Gas_Rx" SG_ 90 BrkSwtchPos_B_ActlGsm 1;
BA_ "U_CD43_MY16_Gas_Rx" SG_ 90 BrkSwtchPos_B_ActlGsm 1;
BA_ "U_CD4_MY13_Hev_Rx" SG_ 90 BrkSwtchPos_B_ActlGsm 1;
BA_ "ContentDependant" SG_ 90 BrkSwtchPos_B_ActlGsm 1;
BA_ "U_CD42_MY19_Diesel_Rx" SG_ 90 TrnValidGearRq_D_Stat 1;
BA_ "U_CD4_MY18_Gas_Rx" SG_ 90 TrnValidGearRq_D_Stat 1;
BA_ "U_U55x_MY18_Gas_Rx" SG_ 90 TrnValidGearRq_D_Stat 1;
BA_ "U_CD43_MY17_Gas_Rx" SG_ 90 TrnValidGearRq_D_Stat 1;
BA_ "U_CD42_MY16_Gas_Rx" SG_ 90 TrnValidGearRq_D_Stat 1;
BA_ "U_C489_MY17_Gas_Rx" SG_ 90 TrnValidGearRq_D_Stat 1;
BA_ "U_CD4_MY17_Hev_Rx" SG_ 90 TrnValidGearRq_D_Stat 1;
BA_ "U_CD4_MY17_Gas_Rx" SG_ 90 TrnValidGearRq_D_Stat 1;
BA_ "U_CD4_MY14_Hev_Rx" SG_ 90 TrnValidGearRq_D_Stat 1;
BA_ "U_CD4_MY14_Gas_Rx" SG_ 90 TrnValidGearRq_D_Stat 1;
BA_ "U_CD43_MY16_Gas_Rx" SG_ 90 TrnValidGearRq_D_Stat 1;
BA_ "U_CD4_MY13_Hev_Rx" SG_ 90 TrnValidGearRq_D_Stat 1;
BA_ "ContentDependant" SG_ 90 TrnValidGearRq_D_Stat 1;
BA_ "U_CD42_MY19_Diesel_Rx" SG_ 90 TrnGearRqCnt_B_Actl 1;
BA_ "U_CD4_MY18_Gas_Rx" SG_ 90 TrnGearRqCnt_B_Actl 1;
BA_ "U_U55x_MY18_Gas_Rx" SG_ 90 TrnGearRqCnt_B_Actl 1;
BA_ "U_CD43_MY17_Gas_Rx" SG_ 90 TrnGearRqCnt_B_Actl 1;
BA_ "U_CD42_MY16_Gas_Rx" SG_ 90 TrnGearRqCnt_B_Actl 1;
BA_ "U_C489_MY17_Gas_Rx" SG_ 90 TrnGearRqCnt_B_Actl 1;
BA_ "U_CD4_MY17_Hev_Rx" SG_ 90 TrnGearRqCnt_B_Actl 1;
BA_ "U_CD4_MY17_Gas_Rx" SG_ 90 TrnGearRqCnt_B_Actl 1;
BA_ "U_CD4_MY14_Hev_Rx" SG_ 90 TrnGearRqCnt_B_Actl 1;
BA_ "U_CD4_MY14_Gas_Rx" SG_ 90 TrnGearRqCnt_B_Actl 1;
BA_ "U_CD43_MY16_Gas_Rx" SG_ 90 TrnGearRqCnt_B_Actl 1;
BA_ "U_CD4_MY13_Hev_Rx" SG_ 90 TrnGearRqCnt_B_Actl 1;
BA_ "ContentDependant" SG_ 90 TrnGearRqCnt_B_Actl 1;
BA_ "U_CD42_MY19_Diesel_Rx" SG_ 90 TrnGearButtn_U_Actl 1;
BA_ "U_U55x_MY18_Gas_Rx" SG_ 90 TrnGearButtn_U_Actl 1;
BA_ "ContentDependant" SG_ 90 TrnGearButtn_U_Actl 1;
BA_ "WakeupSignal" SG_ 90 TrnGearButtn_U_Actl 1;
BA_ "U_CD42_MY19_Diesel_Rx" SG_ 90 TrnGearButtn_B_ActlR2 1;
BA_ "U_CD4_MY18_Gas_Rx" SG_ 90 TrnGearButtn_B_ActlR2 1;
BA_ "U_U55x_MY18_Gas_Rx" SG_ 90 TrnGearButtn_B_ActlR2 1;
BA_ "U_CD43_MY17_Gas_Rx" SG_ 90 TrnGearButtn_B_ActlR2 1;
BA_ "U_CD42_MY16_Gas_Rx" SG_ 90 TrnGearButtn_B_ActlR2 1;
BA_ "U_C489_MY17_Gas_Rx" SG_ 90 TrnGearButtn_B_ActlR2 1;
BA_ "U_CD4_MY17_Hev_Rx" SG_ 90 TrnGearButtn_B_ActlR2 1;
BA_ "U_CD4_MY17_Gas_Rx" SG_ 90 TrnGearButtn_B_ActlR2 1;
BA_ "U_CD4_MY14_Hev_Rx" SG_ 90 TrnGearButtn_B_ActlR2 1;
BA_ "U_CD4_MY14_Gas_Rx" SG_ 90 TrnGearButtn_B_ActlR2 1;
BA_ "U_CD43_MY16_Gas_Rx" SG_ 90 TrnGearButtn_B_ActlR2 1;
BA_ "U_CD4_MY13_Hev_Rx" SG_ 90 TrnGearButtn_B_ActlR2 1;
BA_ "ContentDependant" SG_ 90 TrnGearButtn_B_ActlR2 1;
BA_ "WakeupSignal" SG_ 90 TrnGearButtn_B_ActlR2 1;
BA_ "U_CD42_MY19_Diesel_Rx" SG_ 90 TrnGearButtn_B_ActlR1 1;
BA_ "U_CD4_MY18_Gas_Rx" SG_ 90 TrnGearButtn_B_ActlR1 1;
BA_ "U_U55x_MY18_Gas_Rx" SG_ 90 TrnGearButtn_B_ActlR1 1;
BA_ "U_CD43_MY17_Gas_Rx" SG_ 90 TrnGearButtn_B_ActlR1 1;
BA_ "U_CD42_MY16_Gas_Rx" SG_ 90 TrnGearButtn_B_ActlR1 1;
BA_ "U_C489_MY17_Gas_Rx" SG_ 90 TrnGearButtn_B_ActlR1 1;
BA_ "U_CD4_MY17_Hev_Rx" SG_ 90 TrnGearButtn_B_ActlR1 1;
BA_ "U_CD4_MY17_Gas_Rx" SG_ 90 TrnGearButtn_B_ActlR1 1;
BA_ "U_CD4_MY14_Hev_Rx" SG_ 90 TrnGearButtn_B_ActlR1 1;
BA_ "U_CD4_MY14_Gas_Rx" SG_ 90 TrnGearButtn_B_ActlR1 1;
BA_ "U_CD43_MY16_Gas_Rx" SG_ 90 TrnGearButtn_B_ActlR1 1;
BA_ "U_CD4_MY13_Hev_Rx" SG_ 90 TrnGearButtn_B_ActlR1 1;
BA_ "ContentDependant" SG_ 90 TrnGearButtn_B_ActlR1 1;
BA_ "WakeupSignal" SG_ 90 TrnGearButtn_B_ActlR1 1;
BA_ "U_CD42_MY19_Diesel_Rx" SG_ 90 TrnGearButtn_B_ActlR0 1;
BA_ "U_CD4_MY18_Gas_Rx" SG_ 90 TrnGearButtn_B_ActlR0 1;
BA_ "U_U55x_MY18_Gas_Rx" SG_ 90 TrnGearButtn_B_ActlR0 1;
BA_ "U_CD43_MY17_Gas_Rx" SG_ 90 TrnGearButtn_B_ActlR0 1;
BA_ "U_CD42_MY16_Gas_Rx" SG_ 90 TrnGearButtn_B_ActlR0 1;
BA_ "U_C489_MY17_Gas_Rx" SG_ 90 TrnGearButtn_B_ActlR0 1;
BA_ "U_CD4_MY17_Hev_Rx" SG_ 90 TrnGearButtn_B_ActlR0 1;
BA_ "U_CD4_MY17_Gas_Rx" SG_ 90 TrnGearButtn_B_ActlR0 1;
BA_ "U_CD4_MY14_Hev_Rx" SG_ 90 TrnGearButtn_B_ActlR0 1;
BA_ "U_CD4_MY14_Gas_Rx" SG_ 90 TrnGearButtn_B_ActlR0 1;
BA_ "U_CD43_MY16_Gas_Rx" SG_ 90 TrnGearButtn_B_ActlR0 1;
BA_ "U_CD4_MY13_Hev_Rx" SG_ 90 TrnGearButtn_B_ActlR0 1;
BA_ "ContentDependant" SG_ 90 TrnGearButtn_B_ActlR0 1;
BA_ "WakeupSignal" SG_ 90 TrnGearButtn_B_ActlR0 1;
BA_ "U_CD42_MY19_Diesel_Rx" SG_ 90 TrnGearButtn_B_ActlP2 1;
BA_ "U_CD4_MY18_Gas_Rx" SG_ 90 TrnGearButtn_B_ActlP2 1;
BA_ "U_U55x_MY18_Gas_Rx" SG_ 90 TrnGearButtn_B_ActlP2 1;
BA_ "U_CD43_MY17_Gas_Rx" SG_ 90 TrnGearButtn_B_ActlP2 1;
BA_ "U_CD42_MY16_Gas_Rx" SG_ 90 TrnGearButtn_B_ActlP2 1;
BA_ "U_C489_MY17_Gas_Rx" SG_ 90 TrnGearButtn_B_ActlP2 1;
BA_ "U_CD4_MY17_Hev_Rx" SG_ 90 TrnGearButtn_B_ActlP2 1;
BA_ "U_CD4_MY17_Gas_Rx" SG_ 90 TrnGearButtn_B_ActlP2 1;
BA_ "U_CD4_MY14_Hev_Rx" SG_ 90 TrnGearButtn_B_ActlP2 1;
BA_ "U_CD4_MY14_Gas_Rx" SG_ 90 TrnGearButtn_B_ActlP2 1;
BA_ "U_CD43_MY16_Gas_Rx" SG_ 90 TrnGearButtn_B_ActlP2 1;
BA_ "U_CD4_MY13_Hev_Rx" SG_ 90 TrnGearButtn_B_ActlP2 1;
BA_ "ContentDependant" SG_ 90 TrnGearButtn_B_ActlP2 1;
BA_ "WakeupSignal" SG_ 90 TrnGearButtn_B_ActlP2 1;
BA_ "U_CD42_MY19_Diesel_Rx" SG_ 90 TrnGearButtn_B_ActlP1 1;
BA_ "U_CD4_MY18_Gas_Rx" SG_ 90 TrnGearButtn_B_ActlP1 1;
BA_ "U_U55x_MY18_Gas_Rx" SG_ 90 TrnGearButtn_B_ActlP1 1;
BA_ "U_CD43_MY17_Gas_Rx" SG_ 90 TrnGearButtn_B_ActlP1 1;
BA_ "U_CD42_MY16_Gas_Rx" SG_ 90 TrnGearButtn_B_ActlP1 1;
BA_ "U_C489_MY17_Gas_Rx" SG_ 90 TrnGearButtn_B_ActlP1 1;
BA_ "U_CD4_MY17_Hev_Rx" SG_ 90 TrnGearButtn_B_ActlP1 1;
BA_ "U_CD4_MY17_Gas_Rx" SG_ 90 TrnGearButtn_B_ActlP1 1;
BA_ "U_CD4_MY14_Hev_Rx" SG_ 90 TrnGearButtn_B_ActlP1 1;
BA_ "U_CD4_MY14_Gas_Rx" SG_ 90 TrnGearButtn_B_ActlP1 1;
BA_ "U_CD43_MY16_Gas_Rx" SG_ 90 TrnGearButtn_B_ActlP1 1;
BA_ "U_CD4_MY13_Hev_Rx" SG_ 90 TrnGearButtn_B_ActlP1 1;
BA_ "ContentDependant" SG_ 90 TrnGearButtn_B_ActlP1 1;
BA_ "WakeupSignal" SG_ 90 TrnGearButtn_B_ActlP1 1;
BA_ "U_CD42_MY19_Diesel_Rx" SG_ 90 TrnGearButtn_B_ActlP0 1;
BA_ "U_CD4_MY18_Gas_Rx" SG_ 90 TrnGearButtn_B_ActlP0 1;
BA_ "U_U55x_MY18_Gas_Rx" SG_ 90 TrnGearButtn_B_ActlP0 1;
BA_ "U_CD43_MY17_Gas_Rx" SG_ 90 TrnGearButtn_B_ActlP0 1;
BA_ "U_CD42_MY16_Gas_Rx" SG_ 90 TrnGearButtn_B_ActlP0 1;
BA_ "U_C489_MY17_Gas_Rx" SG_ 90 TrnGearButtn_B_ActlP0 1;
BA_ "U_CD4_MY17_Hev_Rx" SG_ 90 TrnGearButtn_B_ActlP0 1;
BA_ "U_CD4_MY17_Gas_Rx" SG_ 90 TrnGearButtn_B_ActlP0 1;
BA_ "U_CD4_MY14_Hev_Rx" SG_ 90 TrnGearButtn_B_ActlP0 1;
BA_ "U_CD4_MY14_Gas_Rx" SG_ 90 TrnGearButtn_B_ActlP0 1;
BA_ "U_CD43_MY16_Gas_Rx" SG_ 90 TrnGearButtn_B_ActlP0 1;
BA_ "U_CD4_MY13_Hev_Rx" SG_ 90 TrnGearButtn_B_ActlP0 1;
BA_ "ContentDependant" SG_ 90 TrnGearButtn_B_ActlP0 1;
BA_ "WakeupSignal" SG_ 90 TrnGearButtn_B_ActlP0 1;
BA_ "U_CD42_MY19_Diesel_Rx" SG_ 90 TrnGearButtn_B_ActlN2 1;
BA_ "U_CD4_MY18_Gas_Rx" SG_ 90 TrnGearButtn_B_ActlN2 1;
BA_ "U_U55x_MY18_Gas_Rx" SG_ 90 TrnGearButtn_B_ActlN2 1;
BA_ "U_CD43_MY17_Gas_Rx" SG_ 90 TrnGearButtn_B_ActlN2 1;
BA_ "U_CD42_MY16_Gas_Rx" SG_ 90 TrnGearButtn_B_ActlN2 1;
BA_ "U_C489_MY17_Gas_Rx" SG_ 90 TrnGearButtn_B_ActlN2 1;
BA_ "U_CD4_MY17_Hev_Rx" SG_ 90 TrnGearButtn_B_ActlN2 1;
BA_ "U_CD4_MY17_Gas_Rx" SG_ 90 TrnGearButtn_B_ActlN2 1;
BA_ "U_CD4_MY14_Hev_Rx" SG_ 90 TrnGearButtn_B_ActlN2 1;
BA_ "U_CD4_MY14_Gas_Rx" SG_ 90 TrnGearButtn_B_ActlN2 1;
BA_ "U_CD43_MY16_Gas_Rx" SG_ 90 TrnGearButtn_B_ActlN2 1;
BA_ "U_CD4_MY13_Hev_Rx" SG_ 90 TrnGearButtn_B_ActlN2 1;
BA_ "ContentDependant" SG_ 90 TrnGearButtn_B_ActlN2 1;
BA_ "WakeupSignal" SG_ 90 TrnGearButtn_B_ActlN2 1;
BA_ "U_CD42_MY19_Diesel_Rx" SG_ 90 TrnGearButtn_B_ActlN1 1;
BA_ "U_CD4_MY18_Gas_Rx" SG_ 90 TrnGearButtn_B_ActlN1 1;
BA_ "U_U55x_MY18_Gas_Rx" SG_ 90 TrnGearButtn_B_ActlN1 1;
BA_ "U_CD43_MY17_Gas_Rx" SG_ 90 TrnGearButtn_B_ActlN1 1;
BA_ "U_CD42_MY16_Gas_Rx" SG_ 90 TrnGearButtn_B_ActlN1 1;
BA_ "U_C489_MY17_Gas_Rx" SG_ 90 TrnGearButtn_B_ActlN1 1;
BA_ "U_CD4_MY17_Hev_Rx" SG_ 90 TrnGearButtn_B_ActlN1 1;
BA_ "U_CD4_MY17_Gas_Rx" SG_ 90 TrnGearButtn_B_ActlN1 1;
BA_ "U_CD4_MY14_Hev_Rx" SG_ 90 TrnGearButtn_B_ActlN1 1;
BA_ "U_CD4_MY14_Gas_Rx" SG_ 90 TrnGearButtn_B_ActlN1 1;
BA_ "U_CD43_MY16_Gas_Rx" SG_ 90 TrnGearButtn_B_ActlN1 1;
BA_ "U_CD4_MY13_Hev_Rx" SG_ 90 TrnGearButtn_B_ActlN1 1;
BA_ "ContentDependant" SG_ 90 TrnGearButtn_B_ActlN1 1;
BA_ "WakeupSignal" SG_ 90 TrnGearButtn_B_ActlN1 1;
BA_ "U_CD42_MY19_Diesel_Rx" SG_ 90 TrnGearButtn_B_ActlN0 1;
BA_ "U_CD4_MY18_Gas_Rx" SG_ 90 TrnGearButtn_B_ActlN0 1;
BA_ "U_U55x_MY18_Gas_Rx" SG_ 90 TrnGearButtn_B_ActlN0 1;
BA_ "U_CD43_MY17_Gas_Rx" SG_ 90 TrnGearButtn_B_ActlN0 1;
BA_ "U_CD42_MY16_Gas_Rx" SG_ 90 TrnGearButtn_B_ActlN0 1;
BA_ "U_C489_MY17_Gas_Rx" SG_ 90 TrnGearButtn_B_ActlN0 1;
BA_ "U_CD4_MY17_Hev_Rx" SG_ 90 TrnGearButtn_B_ActlN0 1;
BA_ "U_CD4_MY17_Gas_Rx" SG_ 90 TrnGearButtn_B_ActlN0 1;
BA_ "U_CD4_MY14_Hev_Rx" SG_ 90 TrnGearButtn_B_ActlN0 1;
BA_ "U_CD4_MY14_Gas_Rx" SG_ 90 TrnGearButtn_B_ActlN0 1;
BA_ "U_CD43_MY16_Gas_Rx" SG_ 90 TrnGearButtn_B_ActlN0 1;
BA_ "U_CD4_MY13_Hev_Rx" SG_ 90 TrnGearButtn_B_ActlN0 1;
BA_ "ContentDependant" SG_ 90 TrnGearButtn_B_ActlN0 1;
BA_ "WakeupSignal" SG_ 90 TrnGearButtn_B_ActlN0 1;
BA_ "U_CD42_MY19_Diesel_Rx" SG_ 90 TrnGearButtn_B_ActlM2 1;
BA_ "U_CD4_MY18_Gas_Rx" SG_ 90 TrnGearButtn_B_ActlM2 1;
BA_ "U_U55x_MY18_Gas_Rx" SG_ 90 TrnGearButtn_B_ActlM2 1;
BA_ "U_CD43_MY17_Gas_Rx" SG_ 90 TrnGearButtn_B_ActlM2 1;
BA_ "U_CD42_MY16_Gas_Rx" SG_ 90 TrnGearButtn_B_ActlM2 1;
BA_ "U_C489_MY17_Gas_Rx" SG_ 90 TrnGearButtn_B_ActlM2 1;
BA_ "U_CD4_MY17_Hev_Rx" SG_ 90 TrnGearButtn_B_ActlM2 1;
BA_ "U_CD4_MY17_Gas_Rx" SG_ 90 TrnGearButtn_B_ActlM2 1;
BA_ "U_CD4_MY14_Hev_Rx" SG_ 90 TrnGearButtn_B_ActlM2 1;
BA_ "U_CD4_MY14_Gas_Rx" SG_ 90 TrnGearButtn_B_ActlM2 1;
BA_ "U_CD43_MY16_Gas_Rx" SG_ 90 TrnGearButtn_B_ActlM2 1;
BA_ "U_CD4_MY13_Hev_Rx" SG_ 90 TrnGearButtn_B_ActlM2 1;
BA_ "ContentDependant" SG_ 90 TrnGearButtn_B_ActlM2 1;
BA_ "WakeupSignal" SG_ 90 TrnGearButtn_B_ActlM2 1;
BA_ "U_CD42_MY19_Diesel_Rx" SG_ 90 TrnGearButtn_B_ActlM1 1;
BA_ "U_CD4_MY18_Gas_Rx" SG_ 90 TrnGearButtn_B_ActlM1 1;
BA_ "U_U55x_MY18_Gas_Rx" SG_ 90 TrnGearButtn_B_ActlM1 1;
BA_ "U_CD43_MY17_Gas_Rx" SG_ 90 TrnGearButtn_B_ActlM1 1;
BA_ "U_CD42_MY16_Gas_Rx" SG_ 90 TrnGearButtn_B_ActlM1 1;
BA_ "U_C489_MY17_Gas_Rx" SG_ 90 TrnGearButtn_B_ActlM1 1;
BA_ "U_CD4_MY17_Hev_Rx" SG_ 90 TrnGearButtn_B_ActlM1 1;
BA_ "U_CD4_MY17_Gas_Rx" SG_ 90 TrnGearButtn_B_ActlM1 1;
BA_ "U_CD4_MY14_Hev_Rx" SG_ 90 TrnGearButtn_B_ActlM1 1;
BA_ "U_CD4_MY14_Gas_Rx" SG_ 90 TrnGearButtn_B_ActlM1 1;
BA_ "U_CD43_MY16_Gas_Rx" SG_ 90 TrnGearButtn_B_ActlM1 1;
BA_ "U_CD4_MY13_Hev_Rx" SG_ 90 TrnGearButtn_B_ActlM1 1;
BA_ "ContentDependant" SG_ 90 TrnGearButtn_B_ActlM1 1;
BA_ "WakeupSignal" SG_ 90 TrnGearButtn_B_ActlM1 1;
BA_ "U_CD42_MY19_Diesel_Rx" SG_ 90 TrnGearButtn_B_ActlM0 1;
BA_ "U_CD4_MY18_Gas_Rx" SG_ 90 TrnGearButtn_B_ActlM0 1;
BA_ "U_U55x_MY18_Gas_Rx" SG_ 90 TrnGearButtn_B_ActlM0 1;
BA_ "U_CD43_MY17_Gas_Rx" SG_ 90 TrnGearButtn_B_ActlM0 1;
BA_ "U_CD42_MY16_Gas_Rx" SG_ 90 TrnGearButtn_B_ActlM0 1;
BA_ "U_C489_MY17_Gas_Rx" SG_ 90 TrnGearButtn_B_ActlM0 1;
BA_ "U_CD4_MY17_Hev_Rx" SG_ 90 TrnGearButtn_B_ActlM0 1;
BA_ "U_CD4_MY17_Gas_Rx" SG_ 90 TrnGearButtn_B_ActlM0 1;
BA_ "U_CD4_MY14_Hev_Rx" SG_ 90 TrnGearButtn_B_ActlM0 1;
BA_ "U_CD4_MY14_Gas_Rx" SG_ 90 TrnGearButtn_B_ActlM0 1;
BA_ "U_CD43_MY16_Gas_Rx" SG_ 90 TrnGearButtn_B_ActlM0 1;
BA_ "U_CD4_MY13_Hev_Rx" SG_ 90 TrnGearButtn_B_ActlM0 1;
BA_ "ContentDependant" SG_ 90 TrnGearButtn_B_ActlM0 1;
BA_ "WakeupSignal" SG_ 90 TrnGearButtn_B_ActlM0 1;
BA_ "U_CD42_MY19_Diesel_Rx" SG_ 90 TrnGearButtn_B_ActlD2 1;
BA_ "U_CD4_MY18_Gas_Rx" SG_ 90 TrnGearButtn_B_ActlD2 1;
BA_ "U_U55x_MY18_Gas_Rx" SG_ 90 TrnGearButtn_B_ActlD2 1;
BA_ "U_CD43_MY17_Gas_Rx" SG_ 90 TrnGearButtn_B_ActlD2 1;
BA_ "U_CD42_MY16_Gas_Rx" SG_ 90 TrnGearButtn_B_ActlD2 1;
BA_ "U_C489_MY17_Gas_Rx" SG_ 90 TrnGearButtn_B_ActlD2 1;
BA_ "U_CD4_MY17_Hev_Rx" SG_ 90 TrnGearButtn_B_ActlD2 1;
BA_ "U_CD4_MY17_Gas_Rx" SG_ 90 TrnGearButtn_B_ActlD2 1;
BA_ "U_CD4_MY14_Hev_Rx" SG_ 90 TrnGearButtn_B_ActlD2 1;
BA_ "U_CD4_MY14_Gas_Rx" SG_ 90 TrnGearButtn_B_ActlD2 1;
BA_ "U_CD43_MY16_Gas_Rx" SG_ 90 TrnGearButtn_B_ActlD2 1;
BA_ "U_CD4_MY13_Hev_Rx" SG_ 90 TrnGearButtn_B_ActlD2 1;
BA_ "ContentDependant" SG_ 90 TrnGearButtn_B_ActlD2 1;
BA_ "WakeupSignal" SG_ 90 TrnGearButtn_B_ActlD2 1;
BA_ "U_CD42_MY19_Diesel_Rx" SG_ 90 TrnGearButtn_B_ActlD1 1;
BA_ "U_CD4_MY18_Gas_Rx" SG_ 90 TrnGearButtn_B_ActlD1 1;
BA_ "U_U55x_MY18_Gas_Rx" SG_ 90 TrnGearButtn_B_ActlD1 1;
BA_ "U_CD43_MY17_Gas_Rx" SG_ 90 TrnGearButtn_B_ActlD1 1;
BA_ "U_CD42_MY16_Gas_Rx" SG_ 90 TrnGearButtn_B_ActlD1 1;
BA_ "U_C489_MY17_Gas_Rx" SG_ 90 TrnGearButtn_B_ActlD1 1;
BA_ "U_CD4_MY17_Hev_Rx" SG_ 90 TrnGearButtn_B_ActlD1 1;
BA_ "U_CD4_MY17_Gas_Rx" SG_ 90 TrnGearButtn_B_ActlD1 1;
BA_ "U_CD4_MY14_Hev_Rx" SG_ 90 TrnGearButtn_B_ActlD1 1;
BA_ "U_CD4_MY14_Gas_Rx" SG_ 90 TrnGearButtn_B_ActlD1 1;
BA_ "U_CD43_MY16_Gas_Rx" SG_ 90 TrnGearButtn_B_ActlD1 1;
BA_ "U_CD4_MY13_Hev_Rx" SG_ 90 TrnGearButtn_B_ActlD1 1;
BA_ "ContentDependant" SG_ 90 TrnGearButtn_B_ActlD1 1;
BA_ "WakeupSignal" SG_ 90 TrnGearButtn_B_ActlD1 1;
BA_ "U_CD42_MY19_Diesel_Rx" SG_ 90 TrnGearButtn_B_ActlD0 1;
BA_ "U_CD4_MY18_Gas_Rx" SG_ 90 TrnGearButtn_B_ActlD0 1;
BA_ "U_U55x_MY18_Gas_Rx" SG_ 90 TrnGearButtn_B_ActlD0 1;
BA_ "U_CD43_MY17_Gas_Rx" SG_ 90 TrnGearButtn_B_ActlD0 1;
BA_ "U_CD42_MY16_Gas_Rx" SG_ 90 TrnGearButtn_B_ActlD0 1;
BA_ "U_C489_MY17_Gas_Rx" SG_ 90 TrnGearButtn_B_ActlD0 1;
BA_ "U_CD4_MY17_Hev_Rx" SG_ 90 TrnGearButtn_B_ActlD0 1;
BA_ "U_CD4_MY17_Gas_Rx" SG_ 90 TrnGearButtn_B_ActlD0 1;
BA_ "U_CD4_MY14_Hev_Rx" SG_ 90 TrnGearButtn_B_ActlD0 1;
BA_ "U_CD4_MY14_Gas_Rx" SG_ 90 TrnGearButtn_B_ActlD0 1;
BA_ "U_CD43_MY16_Gas_Rx" SG_ 90 TrnGearButtn_B_ActlD0 1;
BA_ "U_CD4_MY13_Hev_Rx" SG_ 90 TrnGearButtn_B_ActlD0 1;
BA_ "ContentDependant" SG_ 90 TrnGearButtn_B_ActlD0 1;
BA_ "WakeupSignal" SG_ 90 TrnGearButtn_B_ActlD0 1;
BA_ "U_CD42_MY19_Diesel_Rx" SG_ 90 TrnGear_No_Cs 1;
BA_ "U_CD4_MY18_Gas_Rx" SG_ 90 TrnGear_No_Cs 1;
BA_ "U_U55x_MY18_Gas_Rx" SG_ 90 TrnGear_No_Cs 1;
BA_ "U_CD43_MY17_Gas_Rx" SG_ 90 TrnGear_No_Cs 1;
BA_ "U_CD42_MY16_Gas_Rx" SG_ 90 TrnGear_No_Cs 1;
BA_ "U_C489_MY17_Gas_Rx" SG_ 90 TrnGear_No_Cs 1;
BA_ "U_CD4_MY17_Hev_Rx" SG_ 90 TrnGear_No_Cs 1;
BA_ "U_CD4_MY17_Gas_Rx" SG_ 90 TrnGear_No_Cs 1;
BA_ "U_CD4_MY14_Hev_Rx" SG_ 90 TrnGear_No_Cs 1;
BA_ "U_CD4_MY14_Gas_Rx" SG_ 90 TrnGear_No_Cs 1;
BA_ "U_CD43_MY16_Gas_Rx" SG_ 90 TrnGear_No_Cs 1;
BA_ "U_CD4_MY13_Hev_Rx" SG_ 90 TrnGear_No_Cs 1;
BA_ "ContentDependant" SG_ 90 TrnGear_No_Cs 1;
BA_ "WakeupSignal" SG_ 90 TrnGear_No_Cs 1;
BA_ "U_CD42_MY19_Diesel_Rx" SG_ 90 TrnGear_No_Cnt 1;
BA_ "U_CD4_MY18_Gas_Rx" SG_ 90 TrnGear_No_Cnt 1;
BA_ "U_U55x_MY18_Gas_Rx" SG_ 90 TrnGear_No_Cnt 1;
BA_ "U_CD43_MY17_Gas_Rx" SG_ 90 TrnGear_No_Cnt 1;
BA_ "U_CD42_MY16_Gas_Rx" SG_ 90 TrnGear_No_Cnt 1;
BA_ "U_C489_MY17_Gas_Rx" SG_ 90 TrnGear_No_Cnt 1;
BA_ "U_CD4_MY17_Hev_Rx" SG_ 90 TrnGear_No_Cnt 1;
BA_ "U_CD4_MY17_Gas_Rx" SG_ 90 TrnGear_No_Cnt 1;
BA_ "U_CD4_MY14_Hev_Rx" SG_ 90 TrnGear_No_Cnt 1;
BA_ "U_CD4_MY14_Gas_Rx" SG_ 90 TrnGear_No_Cnt 1;
BA_ "U_CD43_MY16_Gas_Rx" SG_ 90 TrnGear_No_Cnt 1;
BA_ "U_CD4_MY13_Hev_Rx" SG_ 90 TrnGear_No_Cnt 1;
BA_ "ContentDependant" SG_ 90 TrnGear_No_Cnt 1;
BA_ "U_CD42_MY19_Diesel_Rx" SG_ 90 TrnBtsiOvrrd_B_Stat 1;
BA_ "U_CD4_MY18_Gas_Rx" SG_ 90 TrnBtsiOvrrd_B_Stat 1;
BA_ "U_U55x_MY18_Gas_Rx" SG_ 90 TrnBtsiOvrrd_B_Stat 1;
BA_ "U_CD43_MY17_Gas_Rx" SG_ 90 TrnBtsiOvrrd_B_Stat 1;
BA_ "U_CD42_MY16_Gas_Rx" SG_ 90 TrnBtsiOvrrd_B_Stat 1;
BA_ "U_CD42_MY16_Diesel_Rx" SG_ 90 TrnBtsiOvrrd_B_Stat 1;
BA_ "U_C489_MY17_Gas_Rx" SG_ 90 TrnBtsiOvrrd_B_Stat 1;
BA_ "U_CD4_MY17_Hev_Rx" SG_ 90 TrnBtsiOvrrd_B_Stat 1;
BA_ "U_CD4_MY17_Gas_Rx" SG_ 90 TrnBtsiOvrrd_B_Stat 1;
BA_ "U_CD4_MY17_Diesel_Rx" SG_ 90 TrnBtsiOvrrd_B_Stat 1;
BA_ "U_CD4_MY14_Hev_Rx" SG_ 90 TrnBtsiOvrrd_B_Stat 1;
BA_ "U_CD4_MY14_Gas_Rx" SG_ 90 TrnBtsiOvrrd_B_Stat 1;
BA_ "U_CD4_MY14_Diesel_Rx" SG_ 90 TrnBtsiOvrrd_B_Stat 1;
BA_ "U_CD43_MY16_Gas_Rx" SG_ 90 TrnBtsiOvrrd_B_Stat 1;
BA_ "U_CD42_MY15_Diesel_Rx" SG_ 90 TrnBtsiOvrrd_B_Stat 1;
BA_ "U_CD4_MY13_Diesel_Rx" SG_ 90 TrnBtsiOvrrd_B_Stat 1;
BA_ "ContentDependant" SG_ 90 TrnBtsiOvrrd_B_Stat 1;
BA_ "U_CD42_MY19_Diesel_Rx" SG_ 90 DrQltyDrv_D_StatGsm 1;
BA_ "U_CD4_MY18_Gas_Rx" SG_ 90 DrQltyDrv_D_StatGsm 1;
BA_ "U_U55x_MY18_Gas_Rx" SG_ 90 DrQltyDrv_D_StatGsm 1;
BA_ "U_CD43_MY17_Gas_Rx" SG_ 90 DrQltyDrv_D_StatGsm 1;
BA_ "U_CD42_MY16_Gas_Rx" SG_ 90 DrQltyDrv_D_StatGsm 1;
BA_ "U_C489_MY17_Gas_Rx" SG_ 90 DrQltyDrv_D_StatGsm 1;
BA_ "U_CD4_MY17_Hev_Rx" SG_ 90 DrQltyDrv_D_StatGsm 1;
BA_ "U_CD4_MY17_Gas_Rx" SG_ 90 DrQltyDrv_D_StatGsm 1;
BA_ "U_CD4_MY14_Hev_Rx" SG_ 90 DrQltyDrv_D_StatGsm 1;
BA_ "U_CD4_MY14_Gas_Rx" SG_ 90 DrQltyDrv_D_StatGsm 1;
BA_ "U_CD43_MY16_Gas_Rx" SG_ 90 DrQltyDrv_D_StatGsm 1;
BA_ "ContentDependant" SG_ 90 DrQltyDrv_D_StatGsm 1;
BA_ "U_CD42_MY16_Gas_Rx" SG_ 90 TrnGsmNtmState_D_Actl 1;
BA_ "U_C489_MY16_Gas_Rx" SG_ 90 TrnGsmNtmState_D_Actl 1;
BA_ "U_CD4_MY17_Hev_Rx" SG_ 90 TrnGsmNtmState_D_Actl 1;
BA_ "U_CD4_MY17_Gas_Rx" SG_ 90 TrnGsmNtmState_D_Actl 1;
BA_ "U_CD4_MY14_Hev_Rx" SG_ 90 TrnGsmNtmState_D_Actl 1;
BA_ "U_CD4_MY14_Gas_Rx" SG_ 90 TrnGsmNtmState_D_Actl 1;
BA_ "U_CD43_MY16_Gas_Rx" SG_ 90 TrnGsmNtmState_D_Actl 1;
BA_ "U_C489_MY14_Gas_Rx" SG_ 90 TrnGsmNtmState_D_Actl 1;
BA_ "U_CD42_MY15_Gas_Rx" SG_ 90 TrnGsmNtmState_D_Actl 1;
BA_ "U_CD4_MY13_Hev_Rx" SG_ 90 TrnGsmNtmState_D_Actl 1;
BA_ "U_CD4_MY13_Gas_Rx" SG_ 90 TrnGsmNtmState_D_Actl 1;
BA_ "ContentDependant" SG_ 90 TrnGsmNtmState_D_Actl 1;
BA_ "CrossOver_InfoCAN" SG_ 90 TrnGsmNtmState_D_Actl 1;
BA_ "GenSigTimeoutTime_TCM" SG_ 90 TrnGsmNtmState_D_Actl 300;
BA_ "U_CD4_MY14_Phev_Rx" SG_ 90 TrnGear_D_RqDrv 1;
BA_ "U_CD4_MY14_Hev_Rx" SG_ 90 TrnGear_D_RqDrv 1;
BA_ "U_CD4_MY14_Gas_Rx" SG_ 90 TrnGear_D_RqDrv 1;
BA_ "U_CD4_MY14_Diesel_Rx" SG_ 90 TrnGear_D_RqDrv 1;
BA_ "U_CD43_MY16_Gas_Rx" SG_ 90 TrnGear_D_RqDrv 1;
BA_ "U_C489_MY14_Gas_Rx" SG_ 90 TrnGear_D_RqDrv 1;
BA_ "U_S550_MY15_Gas_Rx" SG_ 90 TrnGear_D_RqDrv 1;
BA_ "U_P552_MY15_Gas_Rx" SG_ 90 TrnGear_D_RqDrv 1;
BA_ "ContentDependant" SG_ 90 TrnGear_D_RqDrv 1;
BA_ "GenSigTimeoutTime_TCM" SG_ 90 TrnGear_D_RqDrv 300;
BA_ "U_CD42_MY14_Diesel_Rx" SG_ 902 PrmtrAlrmWarnRq_No_Actl_UB 1;
BA_ "U_CD42_MY14_Gas_Rx" SG_ 902 PrmtrAlrmWarnRq_No_Actl_UB 1;
BA_ "U_P552_MY15_Gas_Rx" SG_ 902 PrmtrAlrmWarnRq_No_Actl_UB 1;
BA_ "U_S550_MY15_Gas_Rx" SG_ 902 PrmtrAlrmWarnRq_No_Actl_UB 1;
BA_ "U_C489_MY14_Gas_Rx" SG_ 902 PrmtrAlrmWarnRq_No_Actl_UB 1;
BA_ "U_U502_MY15_Gas_Rx" SG_ 902 PrmtrAlrmWarnRq_No_Actl_UB 1;
BA_ "U_UP375_MY15_Gas_Rx" SG_ 902 PrmtrAlrmWarnRq_No_Actl_UB 1;
BA_ "U_UP375_MY15_Diesel_Rx" SG_ 902 PrmtrAlrmWarnRq_No_Actl_UB 1;
BA_ "U_CD43_MY16_Gas_Rx" SG_ 902 PrmtrAlrmWarnRq_No_Actl_UB 1;
BA_ "U_CD4_MY14_Diesel_Rx" SG_ 902 PrmtrAlrmWarnRq_No_Actl_UB 1;
BA_ "U_CD4_MY14_Gas_Rx" SG_ 902 PrmtrAlrmWarnRq_No_Actl_UB 1;
BA_ "U_CD4_MY14_Hev_Rx" SG_ 902 PrmtrAlrmWarnRq_No_Actl_UB 1;
BA_ "U_CD4_MY14_Phev_Rx" SG_ 902 PrmtrAlrmWarnRq_No_Actl_UB 1;
BA_ "U_CD42_MY14_Diesel_Rx" SG_ 902 PrmtrAlrmTrgRq_No_Actl_UB 1;
BA_ "U_CD42_MY14_Gas_Rx" SG_ 902 PrmtrAlrmTrgRq_No_Actl_UB 1;
BA_ "U_P552_MY15_Gas_Rx" SG_ 902 PrmtrAlrmTrgRq_No_Actl_UB 1;
BA_ "U_S550_MY15_Gas_Rx" SG_ 902 PrmtrAlrmTrgRq_No_Actl_UB 1;
BA_ "U_C489_MY14_Gas_Rx" SG_ 902 PrmtrAlrmTrgRq_No_Actl_UB 1;
BA_ "U_U502_MY15_Gas_Rx" SG_ 902 PrmtrAlrmTrgRq_No_Actl_UB 1;
BA_ "U_UP375_MY15_Gas_Rx" SG_ 902 PrmtrAlrmTrgRq_No_Actl_UB 1;
BA_ "U_UP375_MY15_Diesel_Rx" SG_ 902 PrmtrAlrmTrgRq_No_Actl_UB 1;
BA_ "U_CD43_MY16_Gas_Rx" SG_ 902 PrmtrAlrmTrgRq_No_Actl_UB 1;
BA_ "U_CD4_MY14_Diesel_Rx" SG_ 902 PrmtrAlrmTrgRq_No_Actl_UB 1;
BA_ "U_CD4_MY14_Gas_Rx" SG_ 902 PrmtrAlrmTrgRq_No_Actl_UB 1;
BA_ "U_CD4_MY14_Hev_Rx" SG_ 902 PrmtrAlrmTrgRq_No_Actl_UB 1;
BA_ "U_CD4_MY14_Phev_Rx" SG_ 902 PrmtrAlrmTrgRq_No_Actl_UB 1;
BA_ "WakeupSignal" SG_ 902 PrmtrAlrmWarnRq_No_Actl 1;
BA_ "GenSigSendType" SG_ 902 PrmtrAlrmWarnRq_No_Actl 3;
BA_ "U_CD42_MY14_Diesel_Rx" SG_ 902 PrmtrAlrmWarnRq_No_Actl 1;
BA_ "U_CD42_MY14_Gas_Rx" SG_ 902 PrmtrAlrmWarnRq_No_Actl 1;
BA_ "U_P552_MY15_Gas_Rx" SG_ 902 PrmtrAlrmWarnRq_No_Actl 1;
BA_ "U_S550_MY15_Gas_Rx" SG_ 902 PrmtrAlrmWarnRq_No_Actl 1;
BA_ "U_C489_MY14_Gas_Rx" SG_ 902 PrmtrAlrmWarnRq_No_Actl 1;
BA_ "U_U502_MY15_Gas_Rx" SG_ 902 PrmtrAlrmWarnRq_No_Actl 1;
BA_ "U_UP375_MY15_Gas_Rx" SG_ 902 PrmtrAlrmWarnRq_No_Actl 1;
BA_ "U_UP375_MY15_Diesel_Rx" SG_ 902 PrmtrAlrmWarnRq_No_Actl 1;
BA_ "U_CD43_MY16_Gas_Rx" SG_ 902 PrmtrAlrmWarnRq_No_Actl 1;
BA_ "U_CD4_MY14_Diesel_Rx" SG_ 902 PrmtrAlrmWarnRq_No_Actl 1;
BA_ "U_CD4_MY14_Gas_Rx" SG_ 902 PrmtrAlrmWarnRq_No_Actl 1;
BA_ "U_CD4_MY14_Hev_Rx" SG_ 902 PrmtrAlrmWarnRq_No_Actl 1;
BA_ "U_CD4_MY14_Phev_Rx" SG_ 902 PrmtrAlrmWarnRq_No_Actl 1;
BA_ "WakeupSignal" SG_ 902 PrmtrAlrmTrgRq_No_Actl 1;
BA_ "GenSigSendType" SG_ 902 PrmtrAlrmTrgRq_No_Actl 3;
BA_ "U_CD42_MY14_Diesel_Rx" SG_ 902 PrmtrAlrmTrgRq_No_Actl 1;
BA_ "U_CD42_MY14_Gas_Rx" SG_ 902 PrmtrAlrmTrgRq_No_Actl 1;
BA_ "U_P552_MY15_Gas_Rx" SG_ 902 PrmtrAlrmTrgRq_No_Actl 1;
BA_ "U_S550_MY15_Gas_Rx" SG_ 902 PrmtrAlrmTrgRq_No_Actl 1;
BA_ "U_C489_MY14_Gas_Rx" SG_ 902 PrmtrAlrmTrgRq_No_Actl 1;
BA_ "U_U502_MY15_Gas_Rx" SG_ 902 PrmtrAlrmTrgRq_No_Actl 1;
BA_ "U_UP375_MY15_Gas_Rx" SG_ 902 PrmtrAlrmTrgRq_No_Actl 1;
BA_ "U_UP375_MY15_Diesel_Rx" SG_ 902 PrmtrAlrmTrgRq_No_Actl 1;
BA_ "U_CD43_MY16_Gas_Rx" SG_ 902 PrmtrAlrmTrgRq_No_Actl 1;
BA_ "U_CD4_MY14_Diesel_Rx" SG_ 902 PrmtrAlrmTrgRq_No_Actl 1;
BA_ "U_CD4_MY14_Gas_Rx" SG_ 902 PrmtrAlrmTrgRq_No_Actl 1;
BA_ "U_CD4_MY14_Hev_Rx" SG_ 902 PrmtrAlrmTrgRq_No_Actl 1;
BA_ "U_CD4_MY14_Phev_Rx" SG_ 902 PrmtrAlrmTrgRq_No_Actl 1;
BA_ "U_CD4_MY13_Diesel_Rx" SG_ 902 PrmtrAlrmWarn_B_Rq_UB 1;
BA_ "U_CD4_MY13_Gas_Rx" SG_ 902 PrmtrAlrmWarn_B_Rq_UB 1;
BA_ "U_CD4_MY13_Hev_Rx" SG_ 902 PrmtrAlrmWarn_B_Rq_UB 1;
BA_ "U_CD4_MY13_Phev_Rx" SG_ 902 PrmtrAlrmWarn_B_Rq_UB 1;
BA_ "U_CD42_MY14_Diesel_Rx" SG_ 902 PrmtrAlrmWarn_B_Rq_UB 1;
BA_ "U_CD42_MY14_Gas_Rx" SG_ 902 PrmtrAlrmWarn_B_Rq_UB 1;
BA_ "U_P552_MY15_Gas_Rx" SG_ 902 PrmtrAlrmWarn_B_Rq_UB 1;
BA_ "U_S550_MY15_Gas_Rx" SG_ 902 PrmtrAlrmWarn_B_Rq_UB 1;
BA_ "U_C489_MY14_Gas_Rx" SG_ 902 PrmtrAlrmWarn_B_Rq_UB 1;
BA_ "U_U502_MY15_Gas_Rx" SG_ 902 PrmtrAlrmWarn_B_Rq_UB 1;
BA_ "U_UP375_MY15_Gas_Rx" SG_ 902 PrmtrAlrmWarn_B_Rq_UB 1;
BA_ "U_UP375_MY15_Diesel_Rx" SG_ 902 PrmtrAlrmWarn_B_Rq_UB 1;
BA_ "U_CD43_MY16_Gas_Rx" SG_ 902 PrmtrAlrmWarn_B_Rq_UB 1;
BA_ "U_CD4_MY14_Diesel_Rx" SG_ 902 PrmtrAlrmWarn_B_Rq_UB 1;
BA_ "U_CD4_MY14_Gas_Rx" SG_ 902 PrmtrAlrmWarn_B_Rq_UB 1;
BA_ "U_CD4_MY14_Hev_Rx" SG_ 902 PrmtrAlrmWarn_B_Rq_UB 1;
BA_ "U_CD4_MY14_Phev_Rx" SG_ 902 PrmtrAlrmWarn_B_Rq_UB 1;
BA_ "U_CD4_MY13_Diesel_Rx" SG_ 902 RollCode_No_ActlRsm_UB 1;
BA_ "U_CD4_MY13_Gas_Rx" SG_ 902 RollCode_No_ActlRsm_UB 1;
BA_ "U_CD4_MY13_Hev_Rx" SG_ 902 RollCode_No_ActlRsm_UB 1;
BA_ "U_CD4_MY13_Phev_Rx" SG_ 902 RollCode_No_ActlRsm_UB 1;
BA_ "U_CD42_MY14_Diesel_Rx" SG_ 902 RollCode_No_ActlRsm_UB 1;
BA_ "U_CD42_MY14_Gas_Rx" SG_ 902 RollCode_No_ActlRsm_UB 1;
BA_ "U_P552_MY15_Gas_Rx" SG_ 902 RollCode_No_ActlRsm_UB 1;
BA_ "U_S550_MY15_Gas_Rx" SG_ 902 RollCode_No_ActlRsm_UB 1;
BA_ "U_C489_MY14_Gas_Rx" SG_ 902 RollCode_No_ActlRsm_UB 1;
BA_ "U_U502_MY15_Gas_Rx" SG_ 902 RollCode_No_ActlRsm_UB 1;
BA_ "U_UP375_MY15_Gas_Rx" SG_ 902 RollCode_No_ActlRsm_UB 1;
BA_ "U_UP375_MY15_Diesel_Rx" SG_ 902 RollCode_No_ActlRsm_UB 1;
BA_ "U_CD43_MY16_Gas_Rx" SG_ 902 RollCode_No_ActlRsm_UB 1;
BA_ "U_CD4_MY14_Diesel_Rx" SG_ 902 RollCode_No_ActlRsm_UB 1;
BA_ "U_CD4_MY14_Gas_Rx" SG_ 902 RollCode_No_ActlRsm_UB 1;
BA_ "U_CD4_MY14_Hev_Rx" SG_ 902 RollCode_No_ActlRsm_UB 1;
BA_ "U_CD4_MY14_Phev_Rx" SG_ 902 RollCode_No_ActlRsm_UB 1;
BA_ "U_CD4_MY13_Diesel_Rx" SG_ 902 PrmtrAlrmTrg_B_Rq_UB 1;
BA_ "U_CD4_MY13_Gas_Rx" SG_ 902 PrmtrAlrmTrg_B_Rq_UB 1;
BA_ "U_CD4_MY13_Hev_Rx" SG_ 902 PrmtrAlrmTrg_B_Rq_UB 1;
BA_ "U_CD4_MY13_Phev_Rx" SG_ 902 PrmtrAlrmTrg_B_Rq_UB 1;
BA_ "U_CD42_MY14_Diesel_Rx" SG_ 902 PrmtrAlrmTrg_B_Rq_UB 1;
BA_ "U_CD42_MY14_Gas_Rx" SG_ 902 PrmtrAlrmTrg_B_Rq_UB 1;
BA_ "U_P552_MY15_Gas_Rx" SG_ 902 PrmtrAlrmTrg_B_Rq_UB 1;
BA_ "U_S550_MY15_Gas_Rx" SG_ 902 PrmtrAlrmTrg_B_Rq_UB 1;
BA_ "U_C489_MY14_Gas_Rx" SG_ 902 PrmtrAlrmTrg_B_Rq_UB 1;
BA_ "U_U502_MY15_Gas_Rx" SG_ 902 PrmtrAlrmTrg_B_Rq_UB 1;
BA_ "U_UP375_MY15_Gas_Rx" SG_ 902 PrmtrAlrmTrg_B_Rq_UB 1;
BA_ "U_UP375_MY15_Diesel_Rx" SG_ 902 PrmtrAlrmTrg_B_Rq_UB 1;
BA_ "U_CD43_MY16_Gas_Rx" SG_ 902 PrmtrAlrmTrg_B_Rq_UB 1;
BA_ "U_CD4_MY14_Diesel_Rx" SG_ 902 PrmtrAlrmTrg_B_Rq_UB 1;
BA_ "U_CD4_MY14_Gas_Rx" SG_ 902 PrmtrAlrmTrg_B_Rq_UB 1;
BA_ "U_CD4_MY14_Hev_Rx" SG_ 902 PrmtrAlrmTrg_B_Rq_UB 1;
BA_ "U_CD4_MY14_Phev_Rx" SG_ 902 PrmtrAlrmTrg_B_Rq_UB 1;
BA_ "U_CD4_MY13_Diesel_Rx" SG_ 902 PanicRq_No_ActlRsm_UB 1;
BA_ "U_CD4_MY13_Gas_Rx" SG_ 902 PanicRq_No_ActlRsm_UB 1;
BA_ "U_CD4_MY13_Hev_Rx" SG_ 902 PanicRq_No_ActlRsm_UB 1;
BA_ "U_CD4_MY13_Phev_Rx" SG_ 902 PanicRq_No_ActlRsm_UB 1;
BA_ "U_CD42_MY14_Diesel_Rx" SG_ 902 PanicRq_No_ActlRsm_UB 1;
BA_ "U_CD42_MY14_Gas_Rx" SG_ 902 PanicRq_No_ActlRsm_UB 1;
BA_ "U_P552_MY15_Gas_Rx" SG_ 902 PanicRq_No_ActlRsm_UB 1;
BA_ "U_S550_MY15_Gas_Rx" SG_ 902 PanicRq_No_ActlRsm_UB 1;
BA_ "U_C489_MY14_Gas_Rx" SG_ 902 PanicRq_No_ActlRsm_UB 1;
BA_ "U_U502_MY15_Gas_Rx" SG_ 902 PanicRq_No_ActlRsm_UB 1;
BA_ "U_UP375_MY15_Gas_Rx" SG_ 902 PanicRq_No_ActlRsm_UB 1;
BA_ "U_UP375_MY15_Diesel_Rx" SG_ 902 PanicRq_No_ActlRsm_UB 1;
BA_ "U_CD43_MY16_Gas_Rx" SG_ 902 PanicRq_No_ActlRsm_UB 1;
BA_ "U_CD4_MY14_Diesel_Rx" SG_ 902 PanicRq_No_ActlRsm_UB 1;
BA_ "U_CD4_MY14_Gas_Rx" SG_ 902 PanicRq_No_ActlRsm_UB 1;
BA_ "U_CD4_MY14_Hev_Rx" SG_ 902 PanicRq_No_ActlRsm_UB 1;
BA_ "U_CD4_MY14_Phev_Rx" SG_ 902 PanicRq_No_ActlRsm_UB 1;
BA_ "U_CD4_MY13_Diesel_Rx" SG_ 902 Panic_D_RqRsm_UB 1;
BA_ "U_CD4_MY13_Gas_Rx" SG_ 902 Panic_D_RqRsm_UB 1;
BA_ "U_CD4_MY13_Hev_Rx" SG_ 902 Panic_D_RqRsm_UB 1;
BA_ "U_CD4_MY13_Phev_Rx" SG_ 902 Panic_D_RqRsm_UB 1;
BA_ "U_CD42_MY14_Diesel_Rx" SG_ 902 Panic_D_RqRsm_UB 1;
BA_ "U_CD42_MY14_Gas_Rx" SG_ 902 Panic_D_RqRsm_UB 1;
BA_ "U_P552_MY15_Gas_Rx" SG_ 902 Panic_D_RqRsm_UB 1;
BA_ "U_S550_MY15_Gas_Rx" SG_ 902 Panic_D_RqRsm_UB 1;
BA_ "U_C489_MY14_Gas_Rx" SG_ 902 Panic_D_RqRsm_UB 1;
BA_ "U_U502_MY15_Gas_Rx" SG_ 902 Panic_D_RqRsm_UB 1;
BA_ "U_UP375_MY15_Gas_Rx" SG_ 902 Panic_D_RqRsm_UB 1;
BA_ "U_UP375_MY15_Diesel_Rx" SG_ 902 Panic_D_RqRsm_UB 1;
BA_ "U_CD43_MY16_Gas_Rx" SG_ 902 Panic_D_RqRsm_UB 1;
BA_ "U_CD4_MY14_Diesel_Rx" SG_ 902 Panic_D_RqRsm_UB 1;
BA_ "U_CD4_MY14_Gas_Rx" SG_ 902 Panic_D_RqRsm_UB 1;
BA_ "U_CD4_MY14_Hev_Rx" SG_ 902 Panic_D_RqRsm_UB 1;
BA_ "U_CD4_MY14_Phev_Rx" SG_ 902 Panic_D_RqRsm_UB 1;
BA_ "U_CD4_MY13_Diesel_Rx" SG_ 902 CellLockRq_No_ActlRsm_UB 1;
BA_ "U_CD4_MY13_Gas_Rx" SG_ 902 CellLockRq_No_ActlRsm_UB 1;
BA_ "U_CD4_MY13_Hev_Rx" SG_ 902 CellLockRq_No_ActlRsm_UB 1;
BA_ "U_CD4_MY13_Phev_Rx" SG_ 902 CellLockRq_No_ActlRsm_UB 1;
BA_ "U_CD42_MY14_Diesel_Rx" SG_ 902 CellLockRq_No_ActlRsm_UB 1;
BA_ "U_CD42_MY14_Gas_Rx" SG_ 902 CellLockRq_No_ActlRsm_UB 1;
BA_ "U_P552_MY15_Gas_Rx" SG_ 902 CellLockRq_No_ActlRsm_UB 1;
BA_ "U_S550_MY15_Gas_Rx" SG_ 902 CellLockRq_No_ActlRsm_UB 1;
BA_ "U_C489_MY14_Gas_Rx" SG_ 902 CellLockRq_No_ActlRsm_UB 1;
BA_ "U_U502_MY15_Gas_Rx" SG_ 902 CellLockRq_No_ActlRsm_UB 1;
BA_ "U_UP375_MY15_Gas_Rx" SG_ 902 CellLockRq_No_ActlRsm_UB 1;
BA_ "U_UP375_MY15_Diesel_Rx" SG_ 902 CellLockRq_No_ActlRsm_UB 1;
BA_ "U_CD43_MY16_Gas_Rx" SG_ 902 CellLockRq_No_ActlRsm_UB 1;
BA_ "U_CD4_MY14_Diesel_Rx" SG_ 902 CellLockRq_No_ActlRsm_UB 1;
BA_ "U_CD4_MY14_Gas_Rx" SG_ 902 CellLockRq_No_ActlRsm_UB 1;
BA_ "U_CD4_MY14_Hev_Rx" SG_ 902 CellLockRq_No_ActlRsm_UB 1;
BA_ "U_CD4_MY14_Phev_Rx" SG_ 902 CellLockRq_No_ActlRsm_UB 1;
BA_ "WakeupSignal" SG_ 902 RollCode_No_ActlRsm 1;
BA_ "GenSigSendType" SG_ 902 RollCode_No_ActlRsm 3;
BA_ "U_CD4_MY13_Diesel_Rx" SG_ 902 RollCode_No_ActlRsm 1;
BA_ "U_CD4_MY13_Gas_Rx" SG_ 902 RollCode_No_ActlRsm 1;
BA_ "U_CD4_MY13_Hev_Rx" SG_ 902 RollCode_No_ActlRsm 1;
BA_ "U_CD4_MY13_Phev_Rx" SG_ 902 RollCode_No_ActlRsm 1;
BA_ "U_CD42_MY14_Diesel_Rx" SG_ 902 RollCode_No_ActlRsm 1;
BA_ "U_CD42_MY14_Gas_Rx" SG_ 902 RollCode_No_ActlRsm 1;
BA_ "U_P552_MY15_Gas_Rx" SG_ 902 RollCode_No_ActlRsm 1;
BA_ "U_S550_MY15_Gas_Rx" SG_ 902 RollCode_No_ActlRsm 1;
BA_ "U_C489_MY14_Gas_Rx" SG_ 902 RollCode_No_ActlRsm 1;
BA_ "U_U502_MY15_Gas_Rx" SG_ 902 RollCode_No_ActlRsm 1;
BA_ "U_UP375_MY15_Gas_Rx" SG_ 902 RollCode_No_ActlRsm 1;
BA_ "U_UP375_MY15_Diesel_Rx" SG_ 902 RollCode_No_ActlRsm 1;
BA_ "U_CD43_MY16_Gas_Rx" SG_ 902 RollCode_No_ActlRsm 1;
BA_ "U_CD4_MY14_Diesel_Rx" SG_ 902 RollCode_No_ActlRsm 1;
BA_ "U_CD4_MY14_Gas_Rx" SG_ 902 RollCode_No_ActlRsm 1;
BA_ "U_CD4_MY14_Hev_Rx" SG_ 902 RollCode_No_ActlRsm 1;
BA_ "U_CD4_MY14_Phev_Rx" SG_ 902 RollCode_No_ActlRsm 1;
BA_ "WakeupSignal" SG_ 902 PrmtrAlrmWarn_B_Rq 1;
BA_ "GenSigSendType" SG_ 902 PrmtrAlrmWarn_B_Rq 3;
BA_ "U_CD4_MY13_Diesel_Rx" SG_ 902 PrmtrAlrmWarn_B_Rq 1;
BA_ "U_CD4_MY13_Gas_Rx" SG_ 902 PrmtrAlrmWarn_B_Rq 1;
BA_ "U_CD4_MY13_Hev_Rx" SG_ 902 PrmtrAlrmWarn_B_Rq 1;
BA_ "U_CD4_MY13_Phev_Rx" SG_ 902 PrmtrAlrmWarn_B_Rq 1;
BA_ "U_CD42_MY14_Diesel_Rx" SG_ 902 PrmtrAlrmWarn_B_Rq 1;
BA_ "U_CD42_MY14_Gas_Rx" SG_ 902 PrmtrAlrmWarn_B_Rq 1;
BA_ "U_P552_MY15_Gas_Rx" SG_ 902 PrmtrAlrmWarn_B_Rq 1;
BA_ "U_S550_MY15_Gas_Rx" SG_ 902 PrmtrAlrmWarn_B_Rq 1;
BA_ "U_C489_MY14_Gas_Rx" SG_ 902 PrmtrAlrmWarn_B_Rq 1;
BA_ "U_U502_MY15_Gas_Rx" SG_ 902 PrmtrAlrmWarn_B_Rq 1;
BA_ "U_UP375_MY15_Gas_Rx" SG_ 902 PrmtrAlrmWarn_B_Rq 1;
BA_ "U_UP375_MY15_Diesel_Rx" SG_ 902 PrmtrAlrmWarn_B_Rq 1;
BA_ "U_CD43_MY16_Gas_Rx" SG_ 902 PrmtrAlrmWarn_B_Rq 1;
BA_ "U_CD4_MY14_Diesel_Rx" SG_ 902 PrmtrAlrmWarn_B_Rq 1;
BA_ "U_CD4_MY14_Gas_Rx" SG_ 902 PrmtrAlrmWarn_B_Rq 1;
BA_ "U_CD4_MY14_Hev_Rx" SG_ 902 PrmtrAlrmWarn_B_Rq 1;
BA_ "U_CD4_MY14_Phev_Rx" SG_ 902 PrmtrAlrmWarn_B_Rq 1;
BA_ "WakeupSignal" SG_ 902 PrmtrAlrmTrg_B_Rq 1;
BA_ "GenSigSendType" SG_ 902 PrmtrAlrmTrg_B_Rq 3;
BA_ "U_CD4_MY13_Diesel_Rx" SG_ 902 PrmtrAlrmTrg_B_Rq 1;
BA_ "U_CD4_MY13_Gas_Rx" SG_ 902 PrmtrAlrmTrg_B_Rq 1;
BA_ "U_CD4_MY13_Hev_Rx" SG_ 902 PrmtrAlrmTrg_B_Rq 1;
BA_ "U_CD4_MY13_Phev_Rx" SG_ 902 PrmtrAlrmTrg_B_Rq 1;
BA_ "U_CD42_MY14_Diesel_Rx" SG_ 902 PrmtrAlrmTrg_B_Rq 1;
BA_ "U_CD42_MY14_Gas_Rx" SG_ 902 PrmtrAlrmTrg_B_Rq 1;
BA_ "U_P552_MY15_Gas_Rx" SG_ 902 PrmtrAlrmTrg_B_Rq 1;
BA_ "U_S550_MY15_Gas_Rx" SG_ 902 PrmtrAlrmTrg_B_Rq 1;
BA_ "U_C489_MY14_Gas_Rx" SG_ 902 PrmtrAlrmTrg_B_Rq 1;
BA_ "U_U502_MY15_Gas_Rx" SG_ 902 PrmtrAlrmTrg_B_Rq 1;
BA_ "U_UP375_MY15_Gas_Rx" SG_ 902 PrmtrAlrmTrg_B_Rq 1;
BA_ "U_UP375_MY15_Diesel_Rx" SG_ 902 PrmtrAlrmTrg_B_Rq 1;
BA_ "U_CD43_MY16_Gas_Rx" SG_ 902 PrmtrAlrmTrg_B_Rq 1;
BA_ "U_CD4_MY14_Diesel_Rx" SG_ 902 PrmtrAlrmTrg_B_Rq 1;
BA_ "U_CD4_MY14_Gas_Rx" SG_ 902 PrmtrAlrmTrg_B_Rq 1;
BA_ "U_CD4_MY14_Hev_Rx" SG_ 902 PrmtrAlrmTrg_B_Rq 1;
BA_ "U_CD4_MY14_Phev_Rx" SG_ 902 PrmtrAlrmTrg_B_Rq 1;
BA_ "WakeupSignal" SG_ 902 PanicRq_No_ActlRsm 1;
BA_ "GenSigSendType" SG_ 902 PanicRq_No_ActlRsm 3;
BA_ "U_CD4_MY13_Diesel_Rx" SG_ 902 PanicRq_No_ActlRsm 1;
BA_ "U_CD4_MY13_Gas_Rx" SG_ 902 PanicRq_No_ActlRsm 1;
BA_ "U_CD4_MY13_Hev_Rx" SG_ 902 PanicRq_No_ActlRsm 1;
BA_ "U_CD4_MY13_Phev_Rx" SG_ 902 PanicRq_No_ActlRsm 1;
BA_ "U_CD42_MY14_Diesel_Rx" SG_ 902 PanicRq_No_ActlRsm 1;
BA_ "U_CD42_MY14_Gas_Rx" SG_ 902 PanicRq_No_ActlRsm 1;
BA_ "U_P552_MY15_Gas_Rx" SG_ 902 PanicRq_No_ActlRsm 1;
BA_ "U_S550_MY15_Gas_Rx" SG_ 902 PanicRq_No_ActlRsm 1;
BA_ "U_C489_MY14_Gas_Rx" SG_ 902 PanicRq_No_ActlRsm 1;
BA_ "U_U502_MY15_Gas_Rx" SG_ 902 PanicRq_No_ActlRsm 1;
BA_ "U_UP375_MY15_Gas_Rx" SG_ 902 PanicRq_No_ActlRsm 1;
BA_ "U_UP375_MY15_Diesel_Rx" SG_ 902 PanicRq_No_ActlRsm 1;
BA_ "U_CD43_MY16_Gas_Rx" SG_ 902 PanicRq_No_ActlRsm 1;
BA_ "U_CD4_MY14_Diesel_Rx" SG_ 902 PanicRq_No_ActlRsm 1;
BA_ "U_CD4_MY14_Gas_Rx" SG_ 902 PanicRq_No_ActlRsm 1;
BA_ "U_CD4_MY14_Hev_Rx" SG_ 902 PanicRq_No_ActlRsm 1;
BA_ "U_CD4_MY14_Phev_Rx" SG_ 902 PanicRq_No_ActlRsm 1;
BA_ "WakeupSignal" SG_ 902 Panic_D_RqRsm 1;
BA_ "GenSigSendType" SG_ 902 Panic_D_RqRsm 3;
BA_ "U_CD4_MY13_Diesel_Rx" SG_ 902 Panic_D_RqRsm 1;
BA_ "U_CD4_MY13_Gas_Rx" SG_ 902 Panic_D_RqRsm 1;
BA_ "U_CD4_MY13_Hev_Rx" SG_ 902 Panic_D_RqRsm 1;
BA_ "U_CD4_MY13_Phev_Rx" SG_ 902 Panic_D_RqRsm 1;
BA_ "U_CD42_MY14_Diesel_Rx" SG_ 902 Panic_D_RqRsm 1;
BA_ "U_CD42_MY14_Gas_Rx" SG_ 902 Panic_D_RqRsm 1;
BA_ "U_P552_MY15_Gas_Rx" SG_ 902 Panic_D_RqRsm 1;
BA_ "U_S550_MY15_Gas_Rx" SG_ 902 Panic_D_RqRsm 1;
BA_ "U_C489_MY14_Gas_Rx" SG_ 902 Panic_D_RqRsm 1;
BA_ "U_U502_MY15_Gas_Rx" SG_ 902 Panic_D_RqRsm 1;
BA_ "U_UP375_MY15_Gas_Rx" SG_ 902 Panic_D_RqRsm 1;
BA_ "U_UP375_MY15_Diesel_Rx" SG_ 902 Panic_D_RqRsm 1;
BA_ "U_CD43_MY16_Gas_Rx" SG_ 902 Panic_D_RqRsm 1;
BA_ "U_CD4_MY14_Diesel_Rx" SG_ 902 Panic_D_RqRsm 1;
BA_ "U_CD4_MY14_Gas_Rx" SG_ 902 Panic_D_RqRsm 1;
BA_ "U_CD4_MY14_Hev_Rx" SG_ 902 Panic_D_RqRsm 1;
BA_ "U_CD4_MY14_Phev_Rx" SG_ 902 Panic_D_RqRsm 1;
BA_ "WakeupSignal" SG_ 902 CellLockRq_No_ActlRsm 1;
BA_ "GenSigSendType" SG_ 902 CellLockRq_No_ActlRsm 3;
BA_ "U_CD4_MY13_Diesel_Rx" SG_ 902 CellLockRq_No_ActlRsm 1;
BA_ "U_CD4_MY13_Gas_Rx" SG_ 902 CellLockRq_No_ActlRsm 1;
BA_ "U_CD4_MY13_Hev_Rx" SG_ 902 CellLockRq_No_ActlRsm 1;
BA_ "U_CD4_MY13_Phev_Rx" SG_ 902 CellLockRq_No_ActlRsm 1;
BA_ "U_CD42_MY14_Diesel_Rx" SG_ 902 CellLockRq_No_ActlRsm 1;
BA_ "U_CD42_MY14_Gas_Rx" SG_ 902 CellLockRq_No_ActlRsm 1;
BA_ "U_P552_MY15_Gas_Rx" SG_ 902 CellLockRq_No_ActlRsm 1;
BA_ "U_S550_MY15_Gas_Rx" SG_ 902 CellLockRq_No_ActlRsm 1;
BA_ "U_C489_MY14_Gas_Rx" SG_ 902 CellLockRq_No_ActlRsm 1;
BA_ "U_U502_MY15_Gas_Rx" SG_ 902 CellLockRq_No_ActlRsm 1;
BA_ "U_UP375_MY15_Gas_Rx" SG_ 902 CellLockRq_No_ActlRsm 1;
BA_ "U_UP375_MY15_Diesel_Rx" SG_ 902 CellLockRq_No_ActlRsm 1;
BA_ "U_CD43_MY16_Gas_Rx" SG_ 902 CellLockRq_No_ActlRsm 1;
BA_ "U_CD4_MY14_Diesel_Rx" SG_ 902 CellLockRq_No_ActlRsm 1;
BA_ "U_CD4_MY14_Gas_Rx" SG_ 902 CellLockRq_No_ActlRsm 1;
BA_ "U_CD4_MY14_Hev_Rx" SG_ 902 CellLockRq_No_ActlRsm 1;
BA_ "U_CD4_MY14_Phev_Rx" SG_ 902 CellLockRq_No_ActlRsm 1;
BA_ "WakeupSignal" SG_ 902 CellLock_D_RqRsm 1;
BA_ "GenSigSendType" SG_ 902 CellLock_D_RqRsm 3;
BA_ "U_CD4_MY13_Diesel_Rx" SG_ 902 CellLock_D_RqRsm 1;
BA_ "U_CD4_MY13_Gas_Rx" SG_ 902 CellLock_D_RqRsm 1;
BA_ "U_CD4_MY13_Hev_Rx" SG_ 902 CellLock_D_RqRsm 1;
BA_ "U_CD4_MY13_Phev_Rx" SG_ 902 CellLock_D_RqRsm 1;
BA_ "U_CD42_MY14_Diesel_Rx" SG_ 902 CellLock_D_RqRsm 1;
BA_ "U_CD42_MY14_Gas_Rx" SG_ 902 CellLock_D_RqRsm 1;
BA_ "U_P552_MY15_Gas_Rx" SG_ 902 CellLock_D_RqRsm 1;
BA_ "U_S550_MY15_Gas_Rx" SG_ 902 CellLock_D_RqRsm 1;
BA_ "U_C489_MY14_Gas_Rx" SG_ 902 CellLock_D_RqRsm 1;
BA_ "U_U502_MY15_Gas_Rx" SG_ 902 CellLock_D_RqRsm 1;
BA_ "U_UP375_MY15_Gas_Rx" SG_ 902 CellLock_D_RqRsm 1;
BA_ "U_UP375_MY15_Diesel_Rx" SG_ 902 CellLock_D_RqRsm 1;
BA_ "U_CD43_MY16_Gas_Rx" SG_ 902 CellLock_D_RqRsm 1;
BA_ "U_CD4_MY14_Diesel_Rx" SG_ 902 CellLock_D_RqRsm 1;
BA_ "U_CD4_MY14_Gas_Rx" SG_ 902 CellLock_D_RqRsm 1;
BA_ "U_CD4_MY14_Hev_Rx" SG_ 902 CellLock_D_RqRsm 1;
BA_ "U_CD4_MY14_Phev_Rx" SG_ 902 CellLock_D_RqRsm 1;
BA_ "U_CD4_MY13_Diesel_Rx" SG_ 902 CellLock_D_RqRsm_UB 1;
BA_ "U_CD4_MY13_Gas_Rx" SG_ 902 CellLock_D_RqRsm_UB 1;
BA_ "U_CD4_MY13_Hev_Rx" SG_ 902 CellLock_D_RqRsm_UB 1;
BA_ "U_CD4_MY13_Phev_Rx" SG_ 902 CellLock_D_RqRsm_UB 1;
BA_ "U_CD42_MY14_Diesel_Rx" SG_ 902 CellLock_D_RqRsm_UB 1;
BA_ "U_CD42_MY14_Gas_Rx" SG_ 902 CellLock_D_RqRsm_UB 1;
BA_ "U_P552_MY15_Gas_Rx" SG_ 902 CellLock_D_RqRsm_UB 1;
BA_ "U_S550_MY15_Gas_Rx" SG_ 902 CellLock_D_RqRsm_UB 1;
BA_ "U_C489_MY14_Gas_Rx" SG_ 902 CellLock_D_RqRsm_UB 1;
BA_ "U_U502_MY15_Gas_Rx" SG_ 902 CellLock_D_RqRsm_UB 1;
BA_ "U_UP375_MY15_Gas_Rx" SG_ 902 CellLock_D_RqRsm_UB 1;
BA_ "U_UP375_MY15_Diesel_Rx" SG_ 902 CellLock_D_RqRsm_UB 1;
BA_ "U_CD43_MY16_Gas_Rx" SG_ 902 CellLock_D_RqRsm_UB 1;
BA_ "U_CD4_MY14_Diesel_Rx" SG_ 902 CellLock_D_RqRsm_UB 1;
BA_ "U_CD4_MY14_Gas_Rx" SG_ 902 CellLock_D_RqRsm_UB 1;
BA_ "U_CD4_MY14_Hev_Rx" SG_ 902 CellLock_D_RqRsm_UB 1;
BA_ "U_CD4_MY14_Phev_Rx" SG_ 902 CellLock_D_RqRsm_UB 1;
BA_ "U_CD42_MY19_Gas_Tx" SG_ 1429 PCM_GWOnBoardTester 1;
BA_ "U_CD42_MY19_Diesel_Tx" SG_ 1429 PCM_GWOnBoardTester 1;
BA_ "U_V363E_N_MY19_5_20_Diesel_Tx" SG_ 1429 PCM_GWOnBoardTester 1;
BA_ "U_V363E_N_MY19_5_20_Gas_Tx" SG_ 1429 PCM_GWOnBoardTester 1;
BA_ "U_P552_MY18_5_Diesel_Tx" SG_ 1429 PCM_GWOnBoardTester 1;
BA_ "U_P552_MY18_5_Gas_Tx" SG_ 1429 PCM_GWOnBoardTester 1;
BA_ "U_V36X_MY19_Tx" SG_ 1429 PCM_GWOnBoardTester 1;
BA_ "U_V408_MY18_Diesel_Tx" SG_ 1429 PCM_GWOnBoardTester 1;
BA_ "U_V408_MY18_Gas_Tx" SG_ 1429 PCM_GWOnBoardTester 1;
BA_ "U_S550_MY18_Gas_Tx" SG_ 1429 PCM_GWOnBoardTester 1;
BA_ "U_CD4_MY19_Diesel_Tx" SG_ 1429 PCM_GWOnBoardTester 1;
BA_ "U_U55x_MY18_Gas_Tx" SG_ 1429 PCM_GWOnBoardTester 1;
BA_ "U_P552_MY18_Gas_Tx" SG_ 1429 PCM_GWOnBoardTester 1;
BA_ "U_P552_MY17_Gas_Tx" SG_ 1429 PCM_GWOnBoardTester 1;
BA_ "U_D568C_MY19_Gas_Tx" SG_ 1429 PCM_GWOnBoardTester 1;
BA_ "U_CD42_MY19_Diesel_Rx" SG_ 1429 PCM_GWOnBoardTester 1;
BA_ "U_V363E_N_MY19_5_20_Diesel_Rx" SG_ 1429 PCM_GWOnBoardTester 1;
BA_ "U_V363E_N_MY19_5_20_Gas_Rx" SG_ 1429 PCM_GWOnBoardTester 1;
BA_ "U_P552_MY18_5_Diesel_Rx" SG_ 1429 PCM_GWOnBoardTester 1;
BA_ "U_P552_MY18_5_Gas_Rx" SG_ 1429 PCM_GWOnBoardTester 1;
BA_ "U_V36X_MY19_Rx" SG_ 1429 PCM_GWOnBoardTester 1;
BA_ "U_V408_MY18_Diesel_Rx" SG_ 1429 PCM_GWOnBoardTester 1;
BA_ "U_V408_MY18_Gas_Rx" SG_ 1429 PCM_GWOnBoardTester 1;
BA_ "U_S550_MY18_Gas_Rx" SG_ 1429 PCM_GWOnBoardTester 1;
BA_ "U_CD4_MY19_Phev_Rx" SG_ 1429 PCM_GWOnBoardTester 1;
BA_ "U_CD4_MY19_Hev_Rx" SG_ 1429 PCM_GWOnBoardTester 1;
BA_ "U_CD4_MY19_Gas_Rx" SG_ 1429 PCM_GWOnBoardTester 1;
BA_ "U_CD4_MY19_Diesel_Rx" SG_ 1429 PCM_GWOnBoardTester 1;
BA_ "U_U55x_MY18_Gas_Rx" SG_ 1429 PCM_GWOnBoardTester 1;
BA_ "U_CD43_MY17_Gas_Rx" SG_ 1429 PCM_GWOnBoardTester 1;
BA_ "U_CD4_MY17_Diesel_Rx" SG_ 1429 PCM_GWOnBoardTester 1;
BA_ "U_D568C_MY19_Gas_Rx" SG_ 1429 PCM_GWOnBoardTester 1;
BA_ "ContentDependant" SG_ 1429 PCM_GWOnBoardTester 1;
BA_ "GenSigStartValue" SG_ 1429 PCM_GWOnBoardTester 255;
BA_ "U_CD42_MY19_Gas_Tx" SG_ 1429 PCM_GWNMProxy 1;
BA_ "U_CD42_MY19_Diesel_Tx" SG_ 1429 PCM_GWNMProxy 1;
BA_ "U_V363E_N_MY19_5_20_Diesel_Tx" SG_ 1429 PCM_GWNMProxy 1;
BA_ "U_V363E_N_MY19_5_20_Gas_Tx" SG_ 1429 PCM_GWNMProxy 1;
BA_ "U_P552_MY18_5_Diesel_Tx" SG_ 1429 PCM_GWNMProxy 1;
BA_ "U_P552_MY18_5_Gas_Tx" SG_ 1429 PCM_GWNMProxy 1;
BA_ "U_V36X_MY19_Tx" SG_ 1429 PCM_GWNMProxy 1;
BA_ "U_V408_MY18_Diesel_Tx" SG_ 1429 PCM_GWNMProxy 1;
BA_ "U_V408_MY18_Gas_Tx" SG_ 1429 PCM_GWNMProxy 1;
BA_ "U_S550_MY18_Gas_Tx" SG_ 1429 PCM_GWNMProxy 1;
BA_ "U_CD4_MY19_Diesel_Tx" SG_ 1429 PCM_GWNMProxy 1;
BA_ "U_U55x_MY18_Gas_Tx" SG_ 1429 PCM_GWNMProxy 1;
BA_ "U_P552_MY18_Gas_Tx" SG_ 1429 PCM_GWNMProxy 1;
BA_ "U_P552_MY17_Gas_Tx" SG_ 1429 PCM_GWNMProxy 1;
BA_ "U_D568C_MY19_Gas_Tx" SG_ 1429 PCM_GWNMProxy 1;
BA_ "U_CD42_MY19_Diesel_Rx" SG_ 1429 PCM_GWNMProxy 1;
BA_ "U_V363E_N_MY19_5_20_Diesel_Rx" SG_ 1429 PCM_GWNMProxy 1;
BA_ "U_V363E_N_MY19_5_20_Gas_Rx" SG_ 1429 PCM_GWNMProxy 1;
BA_ "U_P552_MY18_5_Diesel_Rx" SG_ 1429 PCM_GWNMProxy 1;
BA_ "U_P552_MY18_5_Gas_Rx" SG_ 1429 PCM_GWNMProxy 1;
BA_ "U_V36X_MY19_Rx" SG_ 1429 PCM_GWNMProxy 1;
BA_ "U_V408_MY18_Diesel_Rx" SG_ 1429 PCM_GWNMProxy 1;
BA_ "U_V408_MY18_Gas_Rx" SG_ 1429 PCM_GWNMProxy 1;
BA_ "U_S550_MY18_Gas_Rx" SG_ 1429 PCM_GWNMProxy 1;
BA_ "U_CD4_MY19_Phev_Rx" SG_ 1429 PCM_GWNMProxy 1;
BA_ "U_CD4_MY19_Hev_Rx" SG_ 1429 PCM_GWNMProxy 1;
BA_ "U_CD4_MY19_Gas_Rx" SG_ 1429 PCM_GWNMProxy 1;
BA_ "U_CD4_MY19_Diesel_Rx" SG_ 1429 PCM_GWNMProxy 1;
BA_ "U_U55x_MY18_Gas_Rx" SG_ 1429 PCM_GWNMProxy 1;
BA_ "U_CD43_MY17_Gas_Rx" SG_ 1429 PCM_GWNMProxy 1;
BA_ "U_CD4_MY17_Diesel_Rx" SG_ 1429 PCM_GWNMProxy 1;
BA_ "U_D568C_MY19_Gas_Rx" SG_ 1429 PCM_GWNMProxy 1;
BA_ "ContentDependant" SG_ 1429 PCM_GWNMProxy 1;
BA_ "GenSigStartValue" SG_ 1429 PCM_GWNMProxy 255;
BA_ "U_CD42_MY19_Gas_Tx" SG_ 1429 PCM_AutoSarNMReserved4 1;
BA_ "U_CD42_MY19_Diesel_Tx" SG_ 1429 PCM_AutoSarNMReserved4 1;
BA_ "U_V363E_N_MY19_5_20_Diesel_Tx" SG_ 1429 PCM_AutoSarNMReserved4 1;
BA_ "U_V363E_N_MY19_5_20_Gas_Tx" SG_ 1429 PCM_AutoSarNMReserved4 1;
BA_ "U_P552_MY18_5_Diesel_Tx" SG_ 1429 PCM_AutoSarNMReserved4 1;
BA_ "U_P552_MY18_5_Gas_Tx" SG_ 1429 PCM_AutoSarNMReserved4 1;
BA_ "U_V36X_MY19_Tx" SG_ 1429 PCM_AutoSarNMReserved4 1;
BA_ "U_V408_MY18_Diesel_Tx" SG_ 1429 PCM_AutoSarNMReserved4 1;
BA_ "U_V408_MY18_Gas_Tx" SG_ 1429 PCM_AutoSarNMReserved4 1;
BA_ "U_S550_MY18_Gas_Tx" SG_ 1429 PCM_AutoSarNMReserved4 1;
BA_ "U_CD4_MY19_Diesel_Tx" SG_ 1429 PCM_AutoSarNMReserved4 1;
BA_ "U_U55x_MY18_Gas_Tx" SG_ 1429 PCM_AutoSarNMReserved4 1;
BA_ "U_P552_MY18_Gas_Tx" SG_ 1429 PCM_AutoSarNMReserved4 1;
BA_ "U_P552_MY17_Gas_Tx" SG_ 1429 PCM_AutoSarNMReserved4 1;
BA_ "U_D568C_MY19_Gas_Tx" SG_ 1429 PCM_AutoSarNMReserved4 1;
BA_ "U_CD42_MY19_Diesel_Rx" SG_ 1429 PCM_AutoSarNMReserved4 1;
BA_ "U_V363E_N_MY19_5_20_Diesel_Rx" SG_ 1429 PCM_AutoSarNMReserved4 1;
BA_ "U_V363E_N_MY19_5_20_Gas_Rx" SG_ 1429 PCM_AutoSarNMReserved4 1;
BA_ "U_P552_MY18_5_Diesel_Rx" SG_ 1429 PCM_AutoSarNMReserved4 1;
BA_ "U_P552_MY18_5_Gas_Rx" SG_ 1429 PCM_AutoSarNMReserved4 1;
BA_ "U_V36X_MY19_Rx" SG_ 1429 PCM_AutoSarNMReserved4 1;
BA_ "U_V408_MY18_Diesel_Rx" SG_ 1429 PCM_AutoSarNMReserved4 1;
BA_ "U_V408_MY18_Gas_Rx" SG_ 1429 PCM_AutoSarNMReserved4 1;
BA_ "U_S550_MY18_Gas_Rx" SG_ 1429 PCM_AutoSarNMReserved4 1;
BA_ "U_CD4_MY19_Phev_Rx" SG_ 1429 PCM_AutoSarNMReserved4 1;
BA_ "U_CD4_MY19_Hev_Rx" SG_ 1429 PCM_AutoSarNMReserved4 1;
BA_ "U_CD4_MY19_Gas_Rx" SG_ 1429 PCM_AutoSarNMReserved4 1;
BA_ "U_CD4_MY19_Diesel_Rx" SG_ 1429 PCM_AutoSarNMReserved4 1;
BA_ "U_U55x_MY18_Gas_Rx" SG_ 1429 PCM_AutoSarNMReserved4 1;
BA_ "U_CD43_MY17_Gas_Rx" SG_ 1429 PCM_AutoSarNMReserved4 1;
BA_ "U_CD4_MY17_Diesel_Rx" SG_ 1429 PCM_AutoSarNMReserved4 1;
BA_ "U_D568C_MY19_Gas_Rx" SG_ 1429 PCM_AutoSarNMReserved4 1;
BA_ "ContentDependant" SG_ 1429 PCM_AutoSarNMReserved4 1;
BA_ "GenSigStartValue" SG_ 1429 PCM_AutoSarNMReserved4 255;
BA_ "U_CD42_MY19_Gas_Tx" SG_ 1429 PCM_AutoSarNMReserved3 1;
BA_ "U_CD42_MY19_Diesel_Tx" SG_ 1429 PCM_AutoSarNMReserved3 1;
BA_ "U_V363E_N_MY19_5_20_Diesel_Tx" SG_ 1429 PCM_AutoSarNMReserved3 1;
BA_ "U_V363E_N_MY19_5_20_Gas_Tx" SG_ 1429 PCM_AutoSarNMReserved3 1;
BA_ "U_P552_MY18_5_Diesel_Tx" SG_ 1429 PCM_AutoSarNMReserved3 1;
BA_ "U_P552_MY18_5_Gas_Tx" SG_ 1429 PCM_AutoSarNMReserved3 1;
BA_ "U_V36X_MY19_Tx" SG_ 1429 PCM_AutoSarNMReserved3 1;
BA_ "U_V408_MY18_Diesel_Tx" SG_ 1429 PCM_AutoSarNMReserved3 1;
BA_ "U_V408_MY18_Gas_Tx" SG_ 1429 PCM_AutoSarNMReserved3 1;
BA_ "U_S550_MY18_Gas_Tx" SG_ 1429 PCM_AutoSarNMReserved3 1;
BA_ "U_CD4_MY19_Diesel_Tx" SG_ 1429 PCM_AutoSarNMReserved3 1;
BA_ "U_U55x_MY18_Gas_Tx" SG_ 1429 PCM_AutoSarNMReserved3 1;
BA_ "U_P552_MY18_Gas_Tx" SG_ 1429 PCM_AutoSarNMReserved3 1;
BA_ "U_P552_MY17_Gas_Tx" SG_ 1429 PCM_AutoSarNMReserved3 1;
BA_ "U_D568C_MY19_Gas_Tx" SG_ 1429 PCM_AutoSarNMReserved3 1;
BA_ "U_CD42_MY19_Diesel_Rx" SG_ 1429 PCM_AutoSarNMReserved3 1;
BA_ "U_V363E_N_MY19_5_20_Diesel_Rx" SG_ 1429 PCM_AutoSarNMReserved3 1;
BA_ "U_V363E_N_MY19_5_20_Gas_Rx" SG_ 1429 PCM_AutoSarNMReserved3 1;
BA_ "U_P552_MY18_5_Diesel_Rx" SG_ 1429 PCM_AutoSarNMReserved3 1;
BA_ "U_P552_MY18_5_Gas_Rx" SG_ 1429 PCM_AutoSarNMReserved3 1;
BA_ "U_V36X_MY19_Rx" SG_ 1429 PCM_AutoSarNMReserved3 1;
BA_ "U_V408_MY18_Diesel_Rx" SG_ 1429 PCM_AutoSarNMReserved3 1;
BA_ "U_V408_MY18_Gas_Rx" SG_ 1429 PCM_AutoSarNMReserved3 1;
BA_ "U_S550_MY18_Gas_Rx" SG_ 1429 PCM_AutoSarNMReserved3 1;
BA_ "U_CD4_MY19_Phev_Rx" SG_ 1429 PCM_AutoSarNMReserved3 1;
BA_ "U_CD4_MY19_Hev_Rx" SG_ 1429 PCM_AutoSarNMReserved3 1;
BA_ "U_CD4_MY19_Gas_Rx" SG_ 1429 PCM_AutoSarNMReserved3 1;
BA_ "U_CD4_MY19_Diesel_Rx" SG_ 1429 PCM_AutoSarNMReserved3 1;
BA_ "U_U55x_MY18_Gas_Rx" SG_ 1429 PCM_AutoSarNMReserved3 1;
BA_ "U_CD43_MY17_Gas_Rx" SG_ 1429 PCM_AutoSarNMReserved3 1;
BA_ "U_CD4_MY17_Diesel_Rx" SG_ 1429 PCM_AutoSarNMReserved3 1;
BA_ "U_D568C_MY19_Gas_Rx" SG_ 1429 PCM_AutoSarNMReserved3 1;
BA_ "ContentDependant" SG_ 1429 PCM_AutoSarNMReserved3 1;
BA_ "GenSigStartValue" SG_ 1429 PCM_AutoSarNMReserved3 255;
BA_ "U_CD42_MY19_Gas_Tx" SG_ 1429 PCM_AutoSarNMReserved2 1;
BA_ "U_CD42_MY19_Diesel_Tx" SG_ 1429 PCM_AutoSarNMReserved2 1;
BA_ "U_V363E_N_MY19_5_20_Diesel_Tx" SG_ 1429 PCM_AutoSarNMReserved2 1;
BA_ "U_V363E_N_MY19_5_20_Gas_Tx" SG_ 1429 PCM_AutoSarNMReserved2 1;
BA_ "U_P552_MY18_5_Diesel_Tx" SG_ 1429 PCM_AutoSarNMReserved2 1;
BA_ "U_P552_MY18_5_Gas_Tx" SG_ 1429 PCM_AutoSarNMReserved2 1;
BA_ "U_V36X_MY19_Tx" SG_ 1429 PCM_AutoSarNMReserved2 1;
BA_ "U_V408_MY18_Diesel_Tx" SG_ 1429 PCM_AutoSarNMReserved2 1;
BA_ "U_V408_MY18_Gas_Tx" SG_ 1429 PCM_AutoSarNMReserved2 1;
BA_ "U_S550_MY18_Gas_Tx" SG_ 1429 PCM_AutoSarNMReserved2 1;
BA_ "U_CD4_MY19_Diesel_Tx" SG_ 1429 PCM_AutoSarNMReserved2 1;
BA_ "U_U55x_MY18_Gas_Tx" SG_ 1429 PCM_AutoSarNMReserved2 1;
BA_ "U_P552_MY18_Gas_Tx" SG_ 1429 PCM_AutoSarNMReserved2 1;
BA_ "U_P552_MY17_Gas_Tx" SG_ 1429 PCM_AutoSarNMReserved2 1;
BA_ "U_D568C_MY19_Gas_Tx" SG_ 1429 PCM_AutoSarNMReserved2 1;
BA_ "U_CD42_MY19_Diesel_Rx" SG_ 1429 PCM_AutoSarNMReserved2 1;
BA_ "U_V363E_N_MY19_5_20_Diesel_Rx" SG_ 1429 PCM_AutoSarNMReserved2 1;
BA_ "U_V363E_N_MY19_5_20_Gas_Rx" SG_ 1429 PCM_AutoSarNMReserved2 1;
BA_ "U_P552_MY18_5_Diesel_Rx" SG_ 1429 PCM_AutoSarNMReserved2 1;
BA_ "U_P552_MY18_5_Gas_Rx" SG_ 1429 PCM_AutoSarNMReserved2 1;
BA_ "U_V36X_MY19_Rx" SG_ 1429 PCM_AutoSarNMReserved2 1;
BA_ "U_V408_MY18_Diesel_Rx" SG_ 1429 PCM_AutoSarNMReserved2 1;
BA_ "U_V408_MY18_Gas_Rx" SG_ 1429 PCM_AutoSarNMReserved2 1;
BA_ "U_S550_MY18_Gas_Rx" SG_ 1429 PCM_AutoSarNMReserved2 1;
BA_ "U_CD4_MY19_Phev_Rx" SG_ 1429 PCM_AutoSarNMReserved2 1;
BA_ "U_CD4_MY19_Hev_Rx" SG_ 1429 PCM_AutoSarNMReserved2 1;
BA_ "U_CD4_MY19_Gas_Rx" SG_ 1429 PCM_AutoSarNMReserved2 1;
BA_ "U_CD4_MY19_Diesel_Rx" SG_ 1429 PCM_AutoSarNMReserved2 1;
BA_ "U_U55x_MY18_Gas_Rx" SG_ 1429 PCM_AutoSarNMReserved2 1;
BA_ "U_CD43_MY17_Gas_Rx" SG_ 1429 PCM_AutoSarNMReserved2 1;
BA_ "U_CD4_MY17_Diesel_Rx" SG_ 1429 PCM_AutoSarNMReserved2 1;
BA_ "U_D568C_MY19_Gas_Rx" SG_ 1429 PCM_AutoSarNMReserved2 1;
BA_ "ContentDependant" SG_ 1429 PCM_AutoSarNMReserved2 1;
BA_ "GenSigStartValue" SG_ 1429 PCM_AutoSarNMReserved2 255;
BA_ "U_CD42_MY19_Gas_Tx" SG_ 1429 PCM_AutoSarNMReserved1 1;
BA_ "U_CD42_MY19_Diesel_Tx" SG_ 1429 PCM_AutoSarNMReserved1 1;
BA_ "U_V363E_N_MY19_5_20_Diesel_Tx" SG_ 1429 PCM_AutoSarNMReserved1 1;
BA_ "U_V363E_N_MY19_5_20_Gas_Tx" SG_ 1429 PCM_AutoSarNMReserved1 1;
BA_ "U_P552_MY18_5_Diesel_Tx" SG_ 1429 PCM_AutoSarNMReserved1 1;
BA_ "U_P552_MY18_5_Gas_Tx" SG_ 1429 PCM_AutoSarNMReserved1 1;
BA_ "U_V36X_MY19_Tx" SG_ 1429 PCM_AutoSarNMReserved1 1;
BA_ "U_V408_MY18_Diesel_Tx" SG_ 1429 PCM_AutoSarNMReserved1 1;
BA_ "U_V408_MY18_Gas_Tx" SG_ 1429 PCM_AutoSarNMReserved1 1;
BA_ "U_S550_MY18_Gas_Tx" SG_ 1429 PCM_AutoSarNMReserved1 1;
BA_ "U_CD4_MY19_Diesel_Tx" SG_ 1429 PCM_AutoSarNMReserved1 1;
BA_ "U_U55x_MY18_Gas_Tx" SG_ 1429 PCM_AutoSarNMReserved1 1;
BA_ "U_P552_MY18_Gas_Tx" SG_ 1429 PCM_AutoSarNMReserved1 1;
BA_ "U_P552_MY17_Gas_Tx" SG_ 1429 PCM_AutoSarNMReserved1 1;
BA_ "U_D568C_MY19_Gas_Tx" SG_ 1429 PCM_AutoSarNMReserved1 1;
BA_ "U_CD42_MY19_Diesel_Rx" SG_ 1429 PCM_AutoSarNMReserved1 1;
BA_ "U_V363E_N_MY19_5_20_Diesel_Rx" SG_ 1429 PCM_AutoSarNMReserved1 1;
BA_ "U_V363E_N_MY19_5_20_Gas_Rx" SG_ 1429 PCM_AutoSarNMReserved1 1;
BA_ "U_P552_MY18_5_Diesel_Rx" SG_ 1429 PCM_AutoSarNMReserved1 1;
BA_ "U_P552_MY18_5_Gas_Rx" SG_ 1429 PCM_AutoSarNMReserved1 1;
BA_ "U_V36X_MY19_Rx" SG_ 1429 PCM_AutoSarNMReserved1 1;
BA_ "U_V408_MY18_Diesel_Rx" SG_ 1429 PCM_AutoSarNMReserved1 1;
BA_ "U_V408_MY18_Gas_Rx" SG_ 1429 PCM_AutoSarNMReserved1 1;
BA_ "U_S550_MY18_Gas_Rx" SG_ 1429 PCM_AutoSarNMReserved1 1;
BA_ "U_CD4_MY19_Phev_Rx" SG_ 1429 PCM_AutoSarNMReserved1 1;
BA_ "U_CD4_MY19_Hev_Rx" SG_ 1429 PCM_AutoSarNMReserved1 1;
BA_ "U_CD4_MY19_Gas_Rx" SG_ 1429 PCM_AutoSarNMReserved1 1;
BA_ "U_CD4_MY19_Diesel_Rx" SG_ 1429 PCM_AutoSarNMReserved1 1;
BA_ "U_U55x_MY18_Gas_Rx" SG_ 1429 PCM_AutoSarNMReserved1 1;
BA_ "U_CD43_MY17_Gas_Rx" SG_ 1429 PCM_AutoSarNMReserved1 1;
BA_ "U_CD4_MY17_Diesel_Rx" SG_ 1429 PCM_AutoSarNMReserved1 1;
BA_ "U_D568C_MY19_Gas_Rx" SG_ 1429 PCM_AutoSarNMReserved1 1;
BA_ "ContentDependant" SG_ 1429 PCM_AutoSarNMReserved1 1;
BA_ "GenSigStartValue" SG_ 1429 PCM_AutoSarNMReserved1 255;
BA_ "U_CD42_MY19_Gas_Tx" SG_ 1429 PCM_AutoSarNMNodeId 1;
BA_ "U_CD42_MY19_Diesel_Tx" SG_ 1429 PCM_AutoSarNMNodeId 1;
BA_ "U_V363E_N_MY19_5_20_Diesel_Tx" SG_ 1429 PCM_AutoSarNMNodeId 1;
BA_ "U_V363E_N_MY19_5_20_Gas_Tx" SG_ 1429 PCM_AutoSarNMNodeId 1;
BA_ "U_P552_MY18_5_Diesel_Tx" SG_ 1429 PCM_AutoSarNMNodeId 1;
BA_ "U_P552_MY18_5_Gas_Tx" SG_ 1429 PCM_AutoSarNMNodeId 1;
BA_ "U_V36X_MY19_Tx" SG_ 1429 PCM_AutoSarNMNodeId 1;
BA_ "U_V408_MY18_Diesel_Tx" SG_ 1429 PCM_AutoSarNMNodeId 1;
BA_ "U_V408_MY18_Gas_Tx" SG_ 1429 PCM_AutoSarNMNodeId 1;
BA_ "U_S550_MY18_Gas_Tx" SG_ 1429 PCM_AutoSarNMNodeId 1;
BA_ "U_CD4_MY19_Diesel_Tx" SG_ 1429 PCM_AutoSarNMNodeId 1;
BA_ "U_U55x_MY18_Gas_Tx" SG_ 1429 PCM_AutoSarNMNodeId 1;
BA_ "U_P552_MY18_Gas_Tx" SG_ 1429 PCM_AutoSarNMNodeId 1;
BA_ "U_P552_MY17_Gas_Tx" SG_ 1429 PCM_AutoSarNMNodeId 1;
BA_ "U_D568C_MY19_Gas_Tx" SG_ 1429 PCM_AutoSarNMNodeId 1;
BA_ "U_CD42_MY19_Diesel_Rx" SG_ 1429 PCM_AutoSarNMNodeId 1;
BA_ "U_V363E_N_MY19_5_20_Diesel_Rx" SG_ 1429 PCM_AutoSarNMNodeId 1;
BA_ "U_V363E_N_MY19_5_20_Gas_Rx" SG_ 1429 PCM_AutoSarNMNodeId 1;
BA_ "U_P552_MY18_5_Diesel_Rx" SG_ 1429 PCM_AutoSarNMNodeId 1;
BA_ "U_P552_MY18_5_Gas_Rx" SG_ 1429 PCM_AutoSarNMNodeId 1;
BA_ "U_V36X_MY19_Rx" SG_ 1429 PCM_AutoSarNMNodeId 1;
BA_ "U_V408_MY18_Diesel_Rx" SG_ 1429 PCM_AutoSarNMNodeId 1;
BA_ "U_V408_MY18_Gas_Rx" SG_ 1429 PCM_AutoSarNMNodeId 1;
BA_ "U_S550_MY18_Gas_Rx" SG_ 1429 PCM_AutoSarNMNodeId 1;
BA_ "U_CD4_MY19_Phev_Rx" SG_ 1429 PCM_AutoSarNMNodeId 1;
BA_ "U_CD4_MY19_Hev_Rx" SG_ 1429 PCM_AutoSarNMNodeId 1;
BA_ "U_CD4_MY19_Gas_Rx" SG_ 1429 PCM_AutoSarNMNodeId 1;
BA_ "U_CD4_MY19_Diesel_Rx" SG_ 1429 PCM_AutoSarNMNodeId 1;
BA_ "U_U55x_MY18_Gas_Rx" SG_ 1429 PCM_AutoSarNMNodeId 1;
BA_ "U_CD43_MY17_Gas_Rx" SG_ 1429 PCM_AutoSarNMNodeId 1;
BA_ "U_CD4_MY17_Diesel_Rx" SG_ 1429 PCM_AutoSarNMNodeId 1;
BA_ "U_D568C_MY19_Gas_Rx" SG_ 1429 PCM_AutoSarNMNodeId 1;
BA_ "ContentDependant" SG_ 1429 PCM_AutoSarNMNodeId 1;
BA_ "GenSigStartValue" SG_ 1429 PCM_AutoSarNMNodeId 95;
BA_ "U_CD42_MY19_Gas_Tx" SG_ 1429 PCM_AutoSarNMControl 1;
BA_ "U_CD42_MY19_Diesel_Tx" SG_ 1429 PCM_AutoSarNMControl 1;
BA_ "U_V363E_N_MY19_5_20_Diesel_Tx" SG_ 1429 PCM_AutoSarNMControl 1;
BA_ "U_V363E_N_MY19_5_20_Gas_Tx" SG_ 1429 PCM_AutoSarNMControl 1;
BA_ "U_P552_MY18_5_Diesel_Tx" SG_ 1429 PCM_AutoSarNMControl 1;
BA_ "U_P552_MY18_5_Gas_Tx" SG_ 1429 PCM_AutoSarNMControl 1;
BA_ "U_V36X_MY19_Tx" SG_ 1429 PCM_AutoSarNMControl 1;
BA_ "U_V408_MY18_Diesel_Tx" SG_ 1429 PCM_AutoSarNMControl 1;
BA_ "U_V408_MY18_Gas_Tx" SG_ 1429 PCM_AutoSarNMControl 1;
BA_ "U_S550_MY18_Gas_Tx" SG_ 1429 PCM_AutoSarNMControl 1;
BA_ "U_CD4_MY19_Diesel_Tx" SG_ 1429 PCM_AutoSarNMControl 1;
BA_ "U_U55x_MY18_Gas_Tx" SG_ 1429 PCM_AutoSarNMControl 1;
BA_ "U_P552_MY18_Gas_Tx" SG_ 1429 PCM_AutoSarNMControl 1;
BA_ "U_P552_MY17_Gas_Tx" SG_ 1429 PCM_AutoSarNMControl 1;
BA_ "U_D568C_MY19_Gas_Tx" SG_ 1429 PCM_AutoSarNMControl 1;
BA_ "U_CD42_MY19_Diesel_Rx" SG_ 1429 PCM_AutoSarNMControl 1;
BA_ "U_V363E_N_MY19_5_20_Diesel_Rx" SG_ 1429 PCM_AutoSarNMControl 1;
BA_ "U_V363E_N_MY19_5_20_Gas_Rx" SG_ 1429 PCM_AutoSarNMControl 1;
BA_ "U_P552_MY18_5_Diesel_Rx" SG_ 1429 PCM_AutoSarNMControl 1;
BA_ "U_P552_MY18_5_Gas_Rx" SG_ 1429 PCM_AutoSarNMControl 1;
BA_ "U_V36X_MY19_Rx" SG_ 1429 PCM_AutoSarNMControl 1;
BA_ "U_V408_MY18_Diesel_Rx" SG_ 1429 PCM_AutoSarNMControl 1;
BA_ "U_V408_MY18_Gas_Rx" SG_ 1429 PCM_AutoSarNMControl 1;
BA_ "U_S550_MY18_Gas_Rx" SG_ 1429 PCM_AutoSarNMControl 1;
BA_ "U_CD4_MY19_Phev_Rx" SG_ 1429 PCM_AutoSarNMControl 1;
BA_ "U_CD4_MY19_Hev_Rx" SG_ 1429 PCM_AutoSarNMControl 1;
BA_ "U_CD4_MY19_Gas_Rx" SG_ 1429 PCM_AutoSarNMControl 1;
BA_ "U_CD4_MY19_Diesel_Rx" SG_ 1429 PCM_AutoSarNMControl 1;
BA_ "U_U55x_MY18_Gas_Rx" SG_ 1429 PCM_AutoSarNMControl 1;
BA_ "U_CD43_MY17_Gas_Rx" SG_ 1429 PCM_AutoSarNMControl 1;
BA_ "U_CD4_MY17_Diesel_Rx" SG_ 1429 PCM_AutoSarNMControl 1;
BA_ "U_D568C_MY19_Gas_Rx" SG_ 1429 PCM_AutoSarNMControl 1;
BA_ "ContentDependant" SG_ 1429 PCM_AutoSarNMControl 1;
BA_ "WakeupSignal" SG_ 740 PtWakeupActv2_B_Rq 1;
BA_ "U_CD4_MY13_Diesel_Rx" SG_ 740 PtWakeupActv2_B_Rq 1;
BA_ "U_CD4_MY13_Gas_Rx" SG_ 740 PtWakeupActv2_B_Rq 1;
BA_ "U_CD4_MY13_Hev_Rx" SG_ 740 PtWakeupActv2_B_Rq 1;
BA_ "U_CD4_MY13_Phev_Rx" SG_ 740 PtWakeupActv2_B_Rq 1;
BA_ "U_CD42_MY14_Diesel_Rx" SG_ 740 PtWakeupActv2_B_Rq 1;
BA_ "U_CD42_MY14_Gas_Rx" SG_ 740 PtWakeupActv2_B_Rq 1;
BA_ "U_P552_MY15_Gas_Rx" SG_ 740 PtWakeupActv2_B_Rq 1;
BA_ "U_S550_MY15_Gas_Rx" SG_ 740 PtWakeupActv2_B_Rq 1;
BA_ "U_C489_MY14_Gas_Rx" SG_ 740 PtWakeupActv2_B_Rq 1;
BA_ "U_U502_MY15_Gas_Rx" SG_ 740 PtWakeupActv2_B_Rq 1;
BA_ "U_UP375_MY15_Gas_Rx" SG_ 740 PtWakeupActv2_B_Rq 1;
BA_ "U_UP375_MY15_Diesel_Rx" SG_ 740 PtWakeupActv2_B_Rq 1;
BA_ "U_CD43_MY16_Gas_Rx" SG_ 740 PtWakeupActv2_B_Rq 1;
BA_ "U_CD4_MY14_Diesel_Rx" SG_ 740 PtWakeupActv2_B_Rq 1;
BA_ "U_CD4_MY14_Gas_Rx" SG_ 740 PtWakeupActv2_B_Rq 1;
BA_ "U_CD4_MY14_Hev_Rx" SG_ 740 PtWakeupActv2_B_Rq 1;
BA_ "U_CD4_MY14_Phev_Rx" SG_ 740 PtWakeupActv2_B_Rq 1;
BA_ "WakeupSignal" SG_ 748 PtWakeupActv3_B_Rq 1;
BA_ "U_CD4_MY13_Phev_Rx" SG_ 748 PtWakeupActv3_B_Rq 1;
BA_ "U_U502_MY15_Gas_Rx" SG_ 748 PtWakeupActv3_B_Rq 1;
BA_ "U_UP375_MY15_Gas_Rx" SG_ 748 PtWakeupActv3_B_Rq 1;
BA_ "U_UP375_MY15_Diesel_Rx" SG_ 748 PtWakeupActv3_B_Rq 1;
BA_ "U_CD43_MY16_Gas_Rx" SG_ 748 PtWakeupActv3_B_Rq 1;
BA_ "U_CD4_MY14_Diesel_Rx" SG_ 748 PtWakeupActv3_B_Rq 1;
BA_ "U_CD4_MY14_Gas_Rx" SG_ 748 PtWakeupActv3_B_Rq 1;
BA_ "U_CD4_MY14_Hev_Rx" SG_ 748 PtWakeupActv3_B_Rq 1;
BA_ "U_CD4_MY14_Phev_Rx" SG_ 748 PtWakeupActv3_B_Rq 1;
BA_ "U_CD4_MY13_Diesel_Rx" SG_ 389 PreCondActv_B_Actl 1;
BA_ "U_CD4_MY13_Gas_Rx" SG_ 389 PreCondActv_B_Actl 1;
BA_ "U_CD4_MY13_Hev_Rx" SG_ 389 PreCondActv_B_Actl 1;
BA_ "U_CD4_MY13_Phev_Rx" SG_ 389 PreCondActv_B_Actl 1;
BA_ "U_CD42_MY14_Diesel_Rx" SG_ 389 PreCondActv_B_Actl 1;
BA_ "U_CD42_MY14_Gas_Rx" SG_ 389 PreCondActv_B_Actl 1;
BA_ "U_P552_MY15_Gas_Rx" SG_ 389 PreCondActv_B_Actl 1;
BA_ "U_S550_MY15_Gas_Rx" SG_ 389 PreCondActv_B_Actl 1;
BA_ "U_C489_MY14_Gas_Rx" SG_ 389 PreCondActv_B_Actl 1;
BA_ "U_U502_MY15_Gas_Rx" SG_ 389 PreCondActv_B_Actl 1;
BA_ "U_UP375_MY15_Gas_Rx" SG_ 389 PreCondActv_B_Actl 1;
BA_ "U_UP375_MY15_Diesel_Rx" SG_ 389 PreCondActv_B_Actl 1;
BA_ "U_CD43_MY16_Gas_Rx" SG_ 389 PreCondActv_B_Actl 1;
BA_ "U_CD4_MY14_Diesel_Rx" SG_ 389 PreCondActv_B_Actl 1;
BA_ "U_CD4_MY14_Gas_Rx" SG_ 389 PreCondActv_B_Actl 1;
BA_ "U_CD4_MY14_Hev_Rx" SG_ 389 PreCondActv_B_Actl 1;
BA_ "U_CD4_MY14_Phev_Rx" SG_ 389 PreCondActv_B_Actl 1;
BA_ "WakeupSignal" SG_ 135 McGlblClkDay_No_Rq 1;
BA_ "CrossOver_InfoCAN" SG_ 135 McGlblClkDay_No_Rq 1;
BA_ "U_CD4_MY13_Diesel_Rx" SG_ 135 McGlblClkDay_No_Rq 1;
BA_ "U_CD4_MY13_Gas_Rx" SG_ 135 McGlblClkDay_No_Rq 1;
BA_ "U_CD4_MY13_Hev_Rx" SG_ 135 McGlblClkDay_No_Rq 1;
BA_ "U_CD4_MY13_Phev_Rx" SG_ 135 McGlblClkDay_No_Rq 1;
BA_ "U_CD42_MY14_Diesel_Rx" SG_ 135 McGlblClkDay_No_Rq 1;
BA_ "U_CD42_MY14_Gas_Rx" SG_ 135 McGlblClkDay_No_Rq 1;
BA_ "U_P552_MY15_Gas_Rx" SG_ 135 McGlblClkDay_No_Rq 1;
BA_ "U_S550_MY15_Gas_Rx" SG_ 135 McGlblClkDay_No_Rq 1;
BA_ "U_C489_MY14_Gas_Rx" SG_ 135 McGlblClkDay_No_Rq 1;
BA_ "U_U502_MY15_Gas_Rx" SG_ 135 McGlblClkDay_No_Rq 1;
BA_ "U_UP375_MY15_Gas_Rx" SG_ 135 McGlblClkDay_No_Rq 1;
BA_ "U_UP375_MY15_Diesel_Rx" SG_ 135 McGlblClkDay_No_Rq 1;
BA_ "U_CD43_MY16_Gas_Rx" SG_ 135 McGlblClkDay_No_Rq 1;
BA_ "U_CD4_MY14_Diesel_Rx" SG_ 135 McGlblClkDay_No_Rq 1;
BA_ "U_CD4_MY14_Gas_Rx" SG_ 135 McGlblClkDay_No_Rq 1;
BA_ "U_CD4_MY14_Hev_Rx" SG_ 135 McGlblClkDay_No_Rq 1;
BA_ "U_CD4_MY14_Phev_Rx" SG_ 135 McGlblClkDay_No_Rq 1;
BA_ "WakeupSignal" SG_ 135 McGlblClkYr_No_Rq 1;
BA_ "CrossOver_InfoCAN" SG_ 135 McGlblClkYr_No_Rq 1;
BA_ "U_CD4_MY13_Diesel_Rx" SG_ 135 McGlblClkYr_No_Rq 1;
BA_ "U_CD4_MY13_Gas_Rx" SG_ 135 McGlblClkYr_No_Rq 1;
BA_ "U_CD4_MY13_Hev_Rx" SG_ 135 McGlblClkYr_No_Rq 1;
BA_ "U_CD4_MY13_Phev_Rx" SG_ 135 McGlblClkYr_No_Rq 1;
BA_ "U_CD42_MY14_Diesel_Rx" SG_ 135 McGlblClkYr_No_Rq 1;
BA_ "U_CD42_MY14_Gas_Rx" SG_ 135 McGlblClkYr_No_Rq 1;
BA_ "U_P552_MY15_Gas_Rx" SG_ 135 McGlblClkYr_No_Rq 1;
BA_ "U_S550_MY15_Gas_Rx" SG_ 135 McGlblClkYr_No_Rq 1;
BA_ "U_C489_MY14_Gas_Rx" SG_ 135 McGlblClkYr_No_Rq 1;
BA_ "U_U502_MY15_Gas_Rx" SG_ 135 McGlblClkYr_No_Rq 1;
BA_ "U_UP375_MY15_Gas_Rx" SG_ 135 McGlblClkYr_No_Rq 1;
BA_ "U_UP375_MY15_Diesel_Rx" SG_ 135 McGlblClkYr_No_Rq 1;
BA_ "U_CD43_MY16_Gas_Rx" SG_ 135 McGlblClkYr_No_Rq 1;
BA_ "U_CD4_MY14_Diesel_Rx" SG_ 135 McGlblClkYr_No_Rq 1;
BA_ "U_CD4_MY14_Gas_Rx" SG_ 135 McGlblClkYr_No_Rq 1;
BA_ "U_CD4_MY14_Hev_Rx" SG_ 135 McGlblClkYr_No_Rq 1;
BA_ "U_CD4_MY14_Phev_Rx" SG_ 135 McGlblClkYr_No_Rq 1;
BA_ "WakeupSignal" SG_ 135 McGlblClkScnd_No_Rq 1;
BA_ "CrossOver_InfoCAN" SG_ 135 McGlblClkScnd_No_Rq 1;
BA_ "U_CD4_MY13_Diesel_Rx" SG_ 135 McGlblClkScnd_No_Rq 1;
BA_ "U_CD4_MY13_Gas_Rx" SG_ 135 McGlblClkScnd_No_Rq 1;
BA_ "U_CD4_MY13_Hev_Rx" SG_ 135 McGlblClkScnd_No_Rq 1;
BA_ "U_CD4_MY13_Phev_Rx" SG_ 135 McGlblClkScnd_No_Rq 1;
BA_ "U_CD42_MY14_Diesel_Rx" SG_ 135 McGlblClkScnd_No_Rq 1;
BA_ "U_CD42_MY14_Gas_Rx" SG_ 135 McGlblClkScnd_No_Rq 1;
BA_ "U_P552_MY15_Gas_Rx" SG_ 135 McGlblClkScnd_No_Rq 1;
BA_ "U_S550_MY15_Gas_Rx" SG_ 135 McGlblClkScnd_No_Rq 1;
BA_ "U_C489_MY14_Gas_Rx" SG_ 135 McGlblClkScnd_No_Rq 1;
BA_ "U_U502_MY15_Gas_Rx" SG_ 135 McGlblClkScnd_No_Rq 1;
BA_ "U_UP375_MY15_Gas_Rx" SG_ 135 McGlblClkScnd_No_Rq 1;
BA_ "U_UP375_MY15_Diesel_Rx" SG_ 135 McGlblClkScnd_No_Rq 1;
BA_ "U_CD43_MY16_Gas_Rx" SG_ 135 McGlblClkScnd_No_Rq 1;
BA_ "U_CD4_MY14_Diesel_Rx" SG_ 135 McGlblClkScnd_No_Rq 1;
BA_ "U_CD4_MY14_Gas_Rx" SG_ 135 McGlblClkScnd_No_Rq 1;
BA_ "U_CD4_MY14_Hev_Rx" SG_ 135 McGlblClkScnd_No_Rq 1;
BA_ "U_CD4_MY14_Phev_Rx" SG_ 135 McGlblClkScnd_No_Rq 1;
BA_ "WakeupSignal" SG_ 135 McGlblClkMnte_No_Rq 1;
BA_ "CrossOver_InfoCAN" SG_ 135 McGlblClkMnte_No_Rq 1;
BA_ "U_CD4_MY13_Diesel_Rx" SG_ 135 McGlblClkMnte_No_Rq 1;
BA_ "U_CD4_MY13_Gas_Rx" SG_ 135 McGlblClkMnte_No_Rq 1;
BA_ "U_CD4_MY13_Hev_Rx" SG_ 135 McGlblClkMnte_No_Rq 1;
BA_ "U_CD4_MY13_Phev_Rx" SG_ 135 McGlblClkMnte_No_Rq 1;
BA_ "U_CD42_MY14_Diesel_Rx" SG_ 135 McGlblClkMnte_No_Rq 1;
BA_ "U_CD42_MY14_Gas_Rx" SG_ 135 McGlblClkMnte_No_Rq 1;
BA_ "U_P552_MY15_Gas_Rx" SG_ 135 McGlblClkMnte_No_Rq 1;
BA_ "U_S550_MY15_Gas_Rx" SG_ 135 McGlblClkMnte_No_Rq 1;
BA_ "U_C489_MY14_Gas_Rx" SG_ 135 McGlblClkMnte_No_Rq 1;
BA_ "U_U502_MY15_Gas_Rx" SG_ 135 McGlblClkMnte_No_Rq 1;
BA_ "U_UP375_MY15_Gas_Rx" SG_ 135 McGlblClkMnte_No_Rq 1;
BA_ "U_UP375_MY15_Diesel_Rx" SG_ 135 McGlblClkMnte_No_Rq 1;
BA_ "U_CD43_MY16_Gas_Rx" SG_ 135 McGlblClkMnte_No_Rq 1;
BA_ "U_CD4_MY14_Diesel_Rx" SG_ 135 McGlblClkMnte_No_Rq 1;
BA_ "U_CD4_MY14_Gas_Rx" SG_ 135 McGlblClkMnte_No_Rq 1;
BA_ "U_CD4_MY14_Hev_Rx" SG_ 135 McGlblClkMnte_No_Rq 1;
BA_ "U_CD4_MY14_Phev_Rx" SG_ 135 McGlblClkMnte_No_Rq 1;
BA_ "WakeupSignal" SG_ 135 McGlblClkHr_No_Rq 1;
BA_ "CrossOver_InfoCAN" SG_ 135 McGlblClkHr_No_Rq 1;
BA_ "U_CD4_MY13_Diesel_Rx" SG_ 135 McGlblClkHr_No_Rq 1;
BA_ "U_CD4_MY13_Gas_Rx" SG_ 135 McGlblClkHr_No_Rq 1;
BA_ "U_CD4_MY13_Hev_Rx" SG_ 135 McGlblClkHr_No_Rq 1;
BA_ "U_CD4_MY13_Phev_Rx" SG_ 135 McGlblClkHr_No_Rq 1;
BA_ "U_CD42_MY14_Diesel_Rx" SG_ 135 McGlblClkHr_No_Rq 1;
BA_ "U_CD42_MY14_Gas_Rx" SG_ 135 McGlblClkHr_No_Rq 1;
BA_ "U_P552_MY15_Gas_Rx" SG_ 135 McGlblClkHr_No_Rq 1;
BA_ "U_S550_MY15_Gas_Rx" SG_ 135 McGlblClkHr_No_Rq 1;
BA_ "U_C489_MY14_Gas_Rx" SG_ 135 McGlblClkHr_No_Rq 1;
BA_ "U_U502_MY15_Gas_Rx" SG_ 135 McGlblClkHr_No_Rq 1;
BA_ "U_UP375_MY15_Gas_Rx" SG_ 135 McGlblClkHr_No_Rq 1;
BA_ "U_UP375_MY15_Diesel_Rx" SG_ 135 McGlblClkHr_No_Rq 1;
BA_ "U_CD43_MY16_Gas_Rx" SG_ 135 McGlblClkHr_No_Rq 1;
BA_ "U_CD4_MY14_Diesel_Rx" SG_ 135 McGlblClkHr_No_Rq 1;
BA_ "U_CD4_MY14_Gas_Rx" SG_ 135 McGlblClkHr_No_Rq 1;
BA_ "U_CD4_MY14_Hev_Rx" SG_ 135 McGlblClkHr_No_Rq 1;
BA_ "U_CD4_MY14_Phev_Rx" SG_ 135 McGlblClkHr_No_Rq 1;
BA_ "WakeupSignal" SG_ 135 McGlblClkAdj_B_Rq 1;
BA_ "CrossOver_InfoCAN" SG_ 135 McGlblClkAdj_B_Rq 1;
BA_ "U_CD4_MY13_Diesel_Rx" SG_ 135 McGlblClkAdj_B_Rq 1;
BA_ "U_CD4_MY13_Gas_Rx" SG_ 135 McGlblClkAdj_B_Rq 1;
BA_ "U_CD4_MY13_Hev_Rx" SG_ 135 McGlblClkAdj_B_Rq 1;
BA_ "U_CD4_MY13_Phev_Rx" SG_ 135 McGlblClkAdj_B_Rq 1;
BA_ "U_CD42_MY14_Diesel_Rx" SG_ 135 McGlblClkAdj_B_Rq 1;
BA_ "U_CD42_MY14_Gas_Rx" SG_ 135 McGlblClkAdj_B_Rq 1;
BA_ "U_P552_MY15_Gas_Rx" SG_ 135 McGlblClkAdj_B_Rq 1;
BA_ "U_S550_MY15_Gas_Rx" SG_ 135 McGlblClkAdj_B_Rq 1;
BA_ "U_C489_MY14_Gas_Rx" SG_ 135 McGlblClkAdj_B_Rq 1;
BA_ "U_U502_MY15_Gas_Rx" SG_ 135 McGlblClkAdj_B_Rq 1;
BA_ "U_UP375_MY15_Gas_Rx" SG_ 135 McGlblClkAdj_B_Rq 1;
BA_ "U_UP375_MY15_Diesel_Rx" SG_ 135 McGlblClkAdj_B_Rq 1;
BA_ "U_CD43_MY16_Gas_Rx" SG_ 135 McGlblClkAdj_B_Rq 1;
BA_ "U_CD4_MY14_Diesel_Rx" SG_ 135 McGlblClkAdj_B_Rq 1;
BA_ "U_CD4_MY14_Gas_Rx" SG_ 135 McGlblClkAdj_B_Rq 1;
BA_ "U_CD4_MY14_Hev_Rx" SG_ 135 McGlblClkAdj_B_Rq 1;
BA_ "U_CD4_MY14_Phev_Rx" SG_ 135 McGlblClkAdj_B_Rq 1;
BA_ "WakeupSignal" SG_ 134 DispGlblClkYr_No_Rq 1;
BA_ "CrossOver_InfoCAN" SG_ 134 DispGlblClkYr_No_Rq 1;
BA_ "U_CD4_MY13_Diesel_Rx" SG_ 134 DispGlblClkYr_No_Rq 1;
BA_ "U_CD4_MY13_Gas_Rx" SG_ 134 DispGlblClkYr_No_Rq 1;
BA_ "U_CD4_MY13_Hev_Rx" SG_ 134 DispGlblClkYr_No_Rq 1;
BA_ "U_CD4_MY13_Phev_Rx" SG_ 134 DispGlblClkYr_No_Rq 1;
BA_ "U_CD42_MY14_Diesel_Rx" SG_ 134 DispGlblClkYr_No_Rq 1;
BA_ "U_CD42_MY14_Gas_Rx" SG_ 134 DispGlblClkYr_No_Rq 1;
BA_ "U_P552_MY15_Gas_Rx" SG_ 134 DispGlblClkYr_No_Rq 1;
BA_ "U_S550_MY15_Gas_Rx" SG_ 134 DispGlblClkYr_No_Rq 1;
BA_ "U_C489_MY14_Gas_Rx" SG_ 134 DispGlblClkYr_No_Rq 1;
BA_ "U_U502_MY15_Gas_Rx" SG_ 134 DispGlblClkYr_No_Rq 1;
BA_ "U_UP375_MY15_Gas_Rx" SG_ 134 DispGlblClkYr_No_Rq 1;
BA_ "U_UP375_MY15_Diesel_Rx" SG_ 134 DispGlblClkYr_No_Rq 1;
BA_ "U_CD43_MY16_Gas_Rx" SG_ 134 DispGlblClkYr_No_Rq 1;
BA_ "U_CD4_MY14_Diesel_Rx" SG_ 134 DispGlblClkYr_No_Rq 1;
BA_ "U_CD4_MY14_Gas_Rx" SG_ 134 DispGlblClkYr_No_Rq 1;
BA_ "U_CD4_MY14_Hev_Rx" SG_ 134 DispGlblClkYr_No_Rq 1;
BA_ "U_CD4_MY14_Phev_Rx" SG_ 134 DispGlblClkYr_No_Rq 1;
BA_ "WakeupSignal" SG_ 134 DispGlblClkScnd_No_Rq 1;
BA_ "CrossOver_InfoCAN" SG_ 134 DispGlblClkScnd_No_Rq 1;
BA_ "U_CD4_MY13_Diesel_Rx" SG_ 134 DispGlblClkScnd_No_Rq 1;
BA_ "U_CD4_MY13_Gas_Rx" SG_ 134 DispGlblClkScnd_No_Rq 1;
BA_ "U_CD4_MY13_Hev_Rx" SG_ 134 DispGlblClkScnd_No_Rq 1;
BA_ "U_CD4_MY13_Phev_Rx" SG_ 134 DispGlblClkScnd_No_Rq 1;
BA_ "U_CD42_MY14_Diesel_Rx" SG_ 134 DispGlblClkScnd_No_Rq 1;
BA_ "U_CD42_MY14_Gas_Rx" SG_ 134 DispGlblClkScnd_No_Rq 1;
BA_ "U_P552_MY15_Gas_Rx" SG_ 134 DispGlblClkScnd_No_Rq 1;
BA_ "U_S550_MY15_Gas_Rx" SG_ 134 DispGlblClkScnd_No_Rq 1;
BA_ "U_C489_MY14_Gas_Rx" SG_ 134 DispGlblClkScnd_No_Rq 1;
BA_ "U_U502_MY15_Gas_Rx" SG_ 134 DispGlblClkScnd_No_Rq 1;
BA_ "U_UP375_MY15_Gas_Rx" SG_ 134 DispGlblClkScnd_No_Rq 1;
BA_ "U_UP375_MY15_Diesel_Rx" SG_ 134 DispGlblClkScnd_No_Rq 1;
BA_ "U_CD43_MY16_Gas_Rx" SG_ 134 DispGlblClkScnd_No_Rq 1;
BA_ "U_CD4_MY14_Diesel_Rx" SG_ 134 DispGlblClkScnd_No_Rq 1;
BA_ "U_CD4_MY14_Gas_Rx" SG_ 134 DispGlblClkScnd_No_Rq 1;
BA_ "U_CD4_MY14_Hev_Rx" SG_ 134 DispGlblClkScnd_No_Rq 1;
BA_ "U_CD4_MY14_Phev_Rx" SG_ 134 DispGlblClkScnd_No_Rq 1;
BA_ "WakeupSignal" SG_ 134 DispGlblClkMnte_No_Rq 1;
BA_ "CrossOver_InfoCAN" SG_ 134 DispGlblClkMnte_No_Rq 1;
BA_ "U_CD4_MY13_Diesel_Rx" SG_ 134 DispGlblClkMnte_No_Rq 1;
BA_ "U_CD4_MY13_Gas_Rx" SG_ 134 DispGlblClkMnte_No_Rq 1;
BA_ "U_CD4_MY13_Hev_Rx" SG_ 134 DispGlblClkMnte_No_Rq 1;
BA_ "U_CD4_MY13_Phev_Rx" SG_ 134 DispGlblClkMnte_No_Rq 1;
BA_ "U_CD42_MY14_Diesel_Rx" SG_ 134 DispGlblClkMnte_No_Rq 1;
BA_ "U_CD42_MY14_Gas_Rx" SG_ 134 DispGlblClkMnte_No_Rq 1;
BA_ "U_P552_MY15_Gas_Rx" SG_ 134 DispGlblClkMnte_No_Rq 1;
BA_ "U_S550_MY15_Gas_Rx" SG_ 134 DispGlblClkMnte_No_Rq 1;
BA_ "U_C489_MY14_Gas_Rx" SG_ 134 DispGlblClkMnte_No_Rq 1;
BA_ "U_U502_MY15_Gas_Rx" SG_ 134 DispGlblClkMnte_No_Rq 1;
BA_ "U_UP375_MY15_Gas_Rx" SG_ 134 DispGlblClkMnte_No_Rq 1;
BA_ "U_UP375_MY15_Diesel_Rx" SG_ 134 DispGlblClkMnte_No_Rq 1;
BA_ "U_CD43_MY16_Gas_Rx" SG_ 134 DispGlblClkMnte_No_Rq 1;
BA_ "U_CD4_MY14_Diesel_Rx" SG_ 134 DispGlblClkMnte_No_Rq 1;
BA_ "U_CD4_MY14_Gas_Rx" SG_ 134 DispGlblClkMnte_No_Rq 1;
BA_ "U_CD4_MY14_Hev_Rx" SG_ 134 DispGlblClkMnte_No_Rq 1;
BA_ "U_CD4_MY14_Phev_Rx" SG_ 134 DispGlblClkMnte_No_Rq 1;
BA_ "WakeupSignal" SG_ 134 DispGlblClkHr_No_Rq 1;
BA_ "CrossOver_InfoCAN" SG_ 134 DispGlblClkHr_No_Rq 1;
BA_ "U_CD4_MY13_Diesel_Rx" SG_ 134 DispGlblClkHr_No_Rq 1;
BA_ "U_CD4_MY13_Gas_Rx" SG_ 134 DispGlblClkHr_No_Rq 1;
BA_ "U_CD4_MY13_Hev_Rx" SG_ 134 DispGlblClkHr_No_Rq 1;
BA_ "U_CD4_MY13_Phev_Rx" SG_ 134 DispGlblClkHr_No_Rq 1;
BA_ "U_CD42_MY14_Diesel_Rx" SG_ 134 DispGlblClkHr_No_Rq 1;
BA_ "U_CD42_MY14_Gas_Rx" SG_ 134 DispGlblClkHr_No_Rq 1;
BA_ "U_P552_MY15_Gas_Rx" SG_ 134 DispGlblClkHr_No_Rq 1;
BA_ "U_S550_MY15_Gas_Rx" SG_ 134 DispGlblClkHr_No_Rq 1;
BA_ "U_C489_MY14_Gas_Rx" SG_ 134 DispGlblClkHr_No_Rq 1;
BA_ "U_U502_MY15_Gas_Rx" SG_ 134 DispGlblClkHr_No_Rq 1;
BA_ "U_UP375_MY15_Gas_Rx" SG_ 134 DispGlblClkHr_No_Rq 1;
BA_ "U_UP375_MY15_Diesel_Rx" SG_ 134 DispGlblClkHr_No_Rq 1;
BA_ "U_CD43_MY16_Gas_Rx" SG_ 134 DispGlblClkHr_No_Rq 1;
BA_ "U_CD4_MY14_Diesel_Rx" SG_ 134 DispGlblClkHr_No_Rq 1;
BA_ "U_CD4_MY14_Gas_Rx" SG_ 134 DispGlblClkHr_No_Rq 1;
BA_ "U_CD4_MY14_Hev_Rx" SG_ 134 DispGlblClkHr_No_Rq 1;
BA_ "U_CD4_MY14_Phev_Rx" SG_ 134 DispGlblClkHr_No_Rq 1;
BA_ "WakeupSignal" SG_ 134 DispGlblClkDay_No_Rq 1;
BA_ "CrossOver_InfoCAN" SG_ 134 DispGlblClkDay_No_Rq 1;
BA_ "U_CD4_MY13_Diesel_Rx" SG_ 134 DispGlblClkDay_No_Rq 1;
BA_ "U_CD4_MY13_Gas_Rx" SG_ 134 DispGlblClkDay_No_Rq 1;
BA_ "U_CD4_MY13_Hev_Rx" SG_ 134 DispGlblClkDay_No_Rq 1;
BA_ "U_CD4_MY13_Phev_Rx" SG_ 134 DispGlblClkDay_No_Rq 1;
BA_ "U_CD42_MY14_Diesel_Rx" SG_ 134 DispGlblClkDay_No_Rq 1;
BA_ "U_CD42_MY14_Gas_Rx" SG_ 134 DispGlblClkDay_No_Rq 1;
BA_ "U_P552_MY15_Gas_Rx" SG_ 134 DispGlblClkDay_No_Rq 1;
BA_ "U_S550_MY15_Gas_Rx" SG_ 134 DispGlblClkDay_No_Rq 1;
BA_ "U_C489_MY14_Gas_Rx" SG_ 134 DispGlblClkDay_No_Rq 1;
BA_ "U_U502_MY15_Gas_Rx" SG_ 134 DispGlblClkDay_No_Rq 1;
BA_ "U_UP375_MY15_Gas_Rx" SG_ 134 DispGlblClkDay_No_Rq 1;
BA_ "U_UP375_MY15_Diesel_Rx" SG_ 134 DispGlblClkDay_No_Rq 1;
BA_ "U_CD43_MY16_Gas_Rx" SG_ 134 DispGlblClkDay_No_Rq 1;
BA_ "U_CD4_MY14_Diesel_Rx" SG_ 134 DispGlblClkDay_No_Rq 1;
BA_ "U_CD4_MY14_Gas_Rx" SG_ 134 DispGlblClkDay_No_Rq 1;
BA_ "U_CD4_MY14_Hev_Rx" SG_ 134 DispGlblClkDay_No_Rq 1;
BA_ "U_CD4_MY14_Phev_Rx" SG_ 134 DispGlblClkDay_No_Rq 1;
BA_ "WakeupSignal" SG_ 134 DispGlblClkAdj_B_Rq 1;
BA_ "CrossOver_InfoCAN" SG_ 134 DispGlblClkAdj_B_Rq 1;
BA_ "U_CD4_MY13_Diesel_Rx" SG_ 134 DispGlblClkAdj_B_Rq 1;
BA_ "U_CD4_MY13_Gas_Rx" SG_ 134 DispGlblClkAdj_B_Rq 1;
BA_ "U_CD4_MY13_Hev_Rx" SG_ 134 DispGlblClkAdj_B_Rq 1;
BA_ "U_CD4_MY13_Phev_Rx" SG_ 134 DispGlblClkAdj_B_Rq 1;
BA_ "U_CD42_MY14_Diesel_Rx" SG_ 134 DispGlblClkAdj_B_Rq 1;
BA_ "U_CD42_MY14_Gas_Rx" SG_ 134 DispGlblClkAdj_B_Rq 1;
BA_ "U_P552_MY15_Gas_Rx" SG_ 134 DispGlblClkAdj_B_Rq 1;
BA_ "U_S550_MY15_Gas_Rx" SG_ 134 DispGlblClkAdj_B_Rq 1;
BA_ "U_C489_MY14_Gas_Rx" SG_ 134 DispGlblClkAdj_B_Rq 1;
BA_ "U_U502_MY15_Gas_Rx" SG_ 134 DispGlblClkAdj_B_Rq 1;
BA_ "U_UP375_MY15_Gas_Rx" SG_ 134 DispGlblClkAdj_B_Rq 1;
BA_ "U_UP375_MY15_Diesel_Rx" SG_ 134 DispGlblClkAdj_B_Rq 1;
BA_ "U_CD43_MY16_Gas_Rx" SG_ 134 DispGlblClkAdj_B_Rq 1;
BA_ "U_CD4_MY14_Diesel_Rx" SG_ 134 DispGlblClkAdj_B_Rq 1;
BA_ "U_CD4_MY14_Gas_Rx" SG_ 134 DispGlblClkAdj_B_Rq 1;
BA_ "U_CD4_MY14_Hev_Rx" SG_ 134 DispGlblClkAdj_B_Rq 1;
BA_ "U_CD4_MY14_Phev_Rx" SG_ 134 DispGlblClkAdj_B_Rq 1;
BA_ "CrossOver_InfoCAN" SG_ 132 GlblClkYr_No_Actl 1;
BA_ "U_CD4_MY13_Diesel_Tx" SG_ 132 GlblClkYr_No_Actl 1;
BA_ "U_CD4_MY13_Gas_Tx" SG_ 132 GlblClkYr_No_Actl 1;
BA_ "U_CD4_MY13_Hev_Tx" SG_ 132 GlblClkYr_No_Actl 1;
BA_ "U_CD4_MY13_Phev_Tx" SG_ 132 GlblClkYr_No_Actl 1;
BA_ "U_CD42_MY14_Diesel_Tx" SG_ 132 GlblClkYr_No_Actl 1;
BA_ "U_CD42_MY14_Gas_Tx" SG_ 132 GlblClkYr_No_Actl 1;
BA_ "U_P552_MY15_Gas_Tx" SG_ 132 GlblClkYr_No_Actl 1;
BA_ "U_S550_MY15_Gas_Tx" SG_ 132 GlblClkYr_No_Actl 1;
BA_ "U_C489_MY14_Gas_Tx" SG_ 132 GlblClkYr_No_Actl 1;
BA_ "U_U502_MY15_Gas_Tx" SG_ 132 GlblClkYr_No_Actl 1;
BA_ "U_UP375_MY15_Gas_Tx" SG_ 132 GlblClkYr_No_Actl 1;
BA_ "U_UP375_MY15_Diesel_Tx" SG_ 132 GlblClkYr_No_Actl 1;
BA_ "U_CD43_MY16_Gas_Tx" SG_ 132 GlblClkYr_No_Actl 1;
BA_ "U_CD4_MY14_Diesel_Tx" SG_ 132 GlblClkYr_No_Actl 1;
BA_ "U_CD4_MY14_Gas_Tx" SG_ 132 GlblClkYr_No_Actl 1;
BA_ "U_CD4_MY14_Hev_Tx" SG_ 132 GlblClkYr_No_Actl 1;
BA_ "U_CD4_MY14_Phev_Tx" SG_ 132 GlblClkYr_No_Actl 1;
BA_ "CrossOver_InfoCAN" SG_ 132 GlblClkScnd_No_Actl 1;
BA_ "GenSigSendType" SG_ 132 GlblClkScnd_No_Actl 3;
BA_ "U_CD4_MY13_Diesel_Tx" SG_ 132 GlblClkScnd_No_Actl 1;
BA_ "U_CD4_MY13_Gas_Tx" SG_ 132 GlblClkScnd_No_Actl 1;
BA_ "U_CD4_MY13_Hev_Tx" SG_ 132 GlblClkScnd_No_Actl 1;
BA_ "U_CD4_MY13_Phev_Tx" SG_ 132 GlblClkScnd_No_Actl 1;
BA_ "U_CD42_MY14_Diesel_Tx" SG_ 132 GlblClkScnd_No_Actl 1;
BA_ "U_CD42_MY14_Gas_Tx" SG_ 132 GlblClkScnd_No_Actl 1;
BA_ "U_P552_MY15_Gas_Tx" SG_ 132 GlblClkScnd_No_Actl 1;
BA_ "U_S550_MY15_Gas_Tx" SG_ 132 GlblClkScnd_No_Actl 1;
BA_ "U_C489_MY14_Gas_Tx" SG_ 132 GlblClkScnd_No_Actl 1;
BA_ "U_U502_MY15_Gas_Tx" SG_ 132 GlblClkScnd_No_Actl 1;
BA_ "U_UP375_MY15_Gas_Tx" SG_ 132 GlblClkScnd_No_Actl 1;
BA_ "U_UP375_MY15_Diesel_Tx" SG_ 132 GlblClkScnd_No_Actl 1;
BA_ "U_CD43_MY16_Gas_Tx" SG_ 132 GlblClkScnd_No_Actl 1;
BA_ "U_CD4_MY14_Diesel_Tx" SG_ 132 GlblClkScnd_No_Actl 1;
BA_ "U_CD4_MY14_Gas_Tx" SG_ 132 GlblClkScnd_No_Actl 1;
BA_ "U_CD4_MY14_Hev_Tx" SG_ 132 GlblClkScnd_No_Actl 1;
BA_ "U_CD4_MY14_Phev_Tx" SG_ 132 GlblClkScnd_No_Actl 1;
BA_ "CrossOver_InfoCAN" SG_ 132 GlblClkMnte_No_Actl 1;
BA_ "U_CD4_MY13_Diesel_Tx" SG_ 132 GlblClkMnte_No_Actl 1;
BA_ "U_CD4_MY13_Gas_Tx" SG_ 132 GlblClkMnte_No_Actl 1;
BA_ "U_CD4_MY13_Hev_Tx" SG_ 132 GlblClkMnte_No_Actl 1;
BA_ "U_CD4_MY13_Phev_Tx" SG_ 132 GlblClkMnte_No_Actl 1;
BA_ "U_CD42_MY14_Diesel_Tx" SG_ 132 GlblClkMnte_No_Actl 1;
BA_ "U_CD42_MY14_Gas_Tx" SG_ 132 GlblClkMnte_No_Actl 1;
BA_ "U_P552_MY15_Gas_Tx" SG_ 132 GlblClkMnte_No_Actl 1;
BA_ "U_S550_MY15_Gas_Tx" SG_ 132 GlblClkMnte_No_Actl 1;
BA_ "U_C489_MY14_Gas_Tx" SG_ 132 GlblClkMnte_No_Actl 1;
BA_ "U_U502_MY15_Gas_Tx" SG_ 132 GlblClkMnte_No_Actl 1;
BA_ "U_UP375_MY15_Gas_Tx" SG_ 132 GlblClkMnte_No_Actl 1;
BA_ "U_UP375_MY15_Diesel_Tx" SG_ 132 GlblClkMnte_No_Actl 1;
BA_ "U_CD43_MY16_Gas_Tx" SG_ 132 GlblClkMnte_No_Actl 1;
BA_ "U_CD4_MY14_Diesel_Tx" SG_ 132 GlblClkMnte_No_Actl 1;
BA_ "U_CD4_MY14_Gas_Tx" SG_ 132 GlblClkMnte_No_Actl 1;
BA_ "U_CD4_MY14_Hev_Tx" SG_ 132 GlblClkMnte_No_Actl 1;
BA_ "U_CD4_MY14_Phev_Tx" SG_ 132 GlblClkMnte_No_Actl 1;
BA_ "CrossOver_InfoCAN" SG_ 132 GlblClkHr_No_Actl 1;
BA_ "U_CD4_MY13_Diesel_Tx" SG_ 132 GlblClkHr_No_Actl 1;
BA_ "U_CD4_MY13_Gas_Tx" SG_ 132 GlblClkHr_No_Actl 1;
BA_ "U_CD4_MY13_Hev_Tx" SG_ 132 GlblClkHr_No_Actl 1;
BA_ "U_CD4_MY13_Phev_Tx" SG_ 132 GlblClkHr_No_Actl 1;
BA_ "U_CD42_MY14_Diesel_Tx" SG_ 132 GlblClkHr_No_Actl 1;
BA_ "U_CD42_MY14_Gas_Tx" SG_ 132 GlblClkHr_No_Actl 1;
BA_ "U_P552_MY15_Gas_Tx" SG_ 132 GlblClkHr_No_Actl 1;
BA_ "U_S550_MY15_Gas_Tx" SG_ 132 GlblClkHr_No_Actl 1;
BA_ "U_C489_MY14_Gas_Tx" SG_ 132 GlblClkHr_No_Actl 1;
BA_ "U_U502_MY15_Gas_Tx" SG_ 132 GlblClkHr_No_Actl 1;
BA_ "U_UP375_MY15_Gas_Tx" SG_ 132 GlblClkHr_No_Actl 1;
BA_ "U_UP375_MY15_Diesel_Tx" SG_ 132 GlblClkHr_No_Actl 1;
BA_ "U_CD43_MY16_Gas_Tx" SG_ 132 GlblClkHr_No_Actl 1;
BA_ "U_CD4_MY14_Diesel_Tx" SG_ 132 GlblClkHr_No_Actl 1;
BA_ "U_CD4_MY14_Gas_Tx" SG_ 132 GlblClkHr_No_Actl 1;
BA_ "U_CD4_MY14_Hev_Tx" SG_ 132 GlblClkHr_No_Actl 1;
BA_ "U_CD4_MY14_Phev_Tx" SG_ 132 GlblClkHr_No_Actl 1;
BA_ "CrossOver_InfoCAN" SG_ 132 GlblClkDay_No_Actl 1;
BA_ "U_CD4_MY13_Diesel_Tx" SG_ 132 GlblClkDay_No_Actl 1;
BA_ "U_CD4_MY13_Gas_Tx" SG_ 132 GlblClkDay_No_Actl 1;
BA_ "U_CD4_MY13_Hev_Tx" SG_ 132 GlblClkDay_No_Actl 1;
BA_ "U_CD4_MY13_Phev_Tx" SG_ 132 GlblClkDay_No_Actl 1;
BA_ "U_CD42_MY14_Diesel_Tx" SG_ 132 GlblClkDay_No_Actl 1;
BA_ "U_CD42_MY14_Gas_Tx" SG_ 132 GlblClkDay_No_Actl 1;
BA_ "U_P552_MY15_Gas_Tx" SG_ 132 GlblClkDay_No_Actl 1;
BA_ "U_S550_MY15_Gas_Tx" SG_ 132 GlblClkDay_No_Actl 1;
BA_ "U_C489_MY14_Gas_Tx" SG_ 132 GlblClkDay_No_Actl 1;
BA_ "U_U502_MY15_Gas_Tx" SG_ 132 GlblClkDay_No_Actl 1;
BA_ "U_UP375_MY15_Gas_Tx" SG_ 132 GlblClkDay_No_Actl 1;
BA_ "U_UP375_MY15_Diesel_Tx" SG_ 132 GlblClkDay_No_Actl 1;
BA_ "U_CD43_MY16_Gas_Tx" SG_ 132 GlblClkDay_No_Actl 1;
BA_ "U_CD4_MY14_Diesel_Tx" SG_ 132 GlblClkDay_No_Actl 1;
BA_ "U_CD4_MY14_Gas_Tx" SG_ 132 GlblClkDay_No_Actl 1;
BA_ "U_CD4_MY14_Hev_Tx" SG_ 132 GlblClkDay_No_Actl 1;
BA_ "U_CD4_MY14_Phev_Tx" SG_ 132 GlblClkDay_No_Actl 1;
BA_ "WakeupSignal" SG_ 836 Foh_D_Stat 1;
BA_ "ContentDependant" SG_ 836 Foh_D_Stat 1;
BA_ "U_CD4_MY13_Diesel_Rx" SG_ 836 Foh_D_Stat 1;
BA_ "U_CD4_MY13_Gas_Rx" SG_ 836 Foh_D_Stat 1;
BA_ "U_CD4_MY13_Hev_Rx" SG_ 836 Foh_D_Stat 1;
BA_ "U_CD4_MY13_Phev_Rx" SG_ 836 Foh_D_Stat 1;
BA_ "U_CD42_MY14_Diesel_Rx" SG_ 836 Foh_D_Stat 1;
BA_ "U_CD42_MY14_Gas_Rx" SG_ 836 Foh_D_Stat 1;
BA_ "U_P552_MY15_Gas_Rx" SG_ 836 Foh_D_Stat 1;
BA_ "U_S550_MY15_Gas_Rx" SG_ 836 Foh_D_Stat 1;
BA_ "U_C489_MY14_Gas_Rx" SG_ 836 Foh_D_Stat 1;
BA_ "U_U502_MY15_Gas_Rx" SG_ 836 Foh_D_Stat 1;
BA_ "U_UP375_MY15_Gas_Rx" SG_ 836 Foh_D_Stat 1;
BA_ "U_UP375_MY15_Diesel_Rx" SG_ 836 Foh_D_Stat 1;
BA_ "U_CD43_MY16_Gas_Rx" SG_ 836 Foh_D_Stat 1;
BA_ "U_CD4_MY14_Diesel_Rx" SG_ 836 Foh_D_Stat 1;
BA_ "U_CD4_MY14_Gas_Rx" SG_ 836 Foh_D_Stat 1;
BA_ "U_CD4_MY14_Hev_Rx" SG_ 836 Foh_D_Stat 1;
BA_ "U_CD4_MY14_Phev_Rx" SG_ 836 Foh_D_Stat 1;
BA_ "CrossOver_InfoCAN" SG_ 939 PrkAidChime_D_Stat 1;
BA_ "GenSigSendType" SG_ 939 PrkAidChime_D_Stat 3;
BA_ "U_CD4_MY13_Diesel_Tx" SG_ 939 PrkAidChime_D_Stat 1;
BA_ "U_CD4_MY13_Gas_Tx" SG_ 939 PrkAidChime_D_Stat 1;
BA_ "U_CD4_MY13_Hev_Tx" SG_ 939 PrkAidChime_D_Stat 1;
BA_ "U_CD4_MY13_Phev_Tx" SG_ 939 PrkAidChime_D_Stat 1;
BA_ "U_CD42_MY14_Diesel_Tx" SG_ 939 PrkAidChime_D_Stat 1;
BA_ "U_CD42_MY14_Gas_Tx" SG_ 939 PrkAidChime_D_Stat 1;
BA_ "U_P552_MY15_Gas_Tx" SG_ 939 PrkAidChime_D_Stat 1;
BA_ "U_S550_MY15_Gas_Tx" SG_ 939 PrkAidChime_D_Stat 1;
BA_ "U_C489_MY14_Gas_Tx" SG_ 939 PrkAidChime_D_Stat 1;
BA_ "U_U502_MY15_Gas_Tx" SG_ 939 PrkAidChime_D_Stat 1;
BA_ "U_UP375_MY15_Gas_Tx" SG_ 939 PrkAidChime_D_Stat 1;
BA_ "U_UP375_MY15_Diesel_Tx" SG_ 939 PrkAidChime_D_Stat 1;
BA_ "U_CD43_MY16_Gas_Tx" SG_ 939 PrkAidChime_D_Stat 1;
BA_ "U_CD4_MY14_Diesel_Tx" SG_ 939 PrkAidChime_D_Stat 1;
BA_ "U_CD4_MY14_Gas_Tx" SG_ 939 PrkAidChime_D_Stat 1;
BA_ "U_CD4_MY14_Hev_Tx" SG_ 939 PrkAidChime_D_Stat 1;
BA_ "U_CD4_MY14_Phev_Tx" SG_ 939 PrkAidChime_D_Stat 1;
BA_ "CrossOver_InfoCAN" SG_ 939 PrkAidSnsRlCntr_D_Stat 1;
BA_ "GenSigSendType" SG_ 939 PrkAidSnsRlCntr_D_Stat 3;
BA_ "U_CD4_MY13_Diesel_Rx" SG_ 939 PrkAidSnsRlCntr_D_Stat 1;
BA_ "U_CD4_MY13_Gas_Rx" SG_ 939 PrkAidSnsRlCntr_D_Stat 1;
BA_ "U_CD4_MY13_Hev_Rx" SG_ 939 PrkAidSnsRlCntr_D_Stat 1;
BA_ "U_CD4_MY13_Phev_Rx" SG_ 939 PrkAidSnsRlCntr_D_Stat 1;
BA_ "U_CD42_MY14_Diesel_Rx" SG_ 939 PrkAidSnsRlCntr_D_Stat 1;
BA_ "U_CD42_MY14_Gas_Rx" SG_ 939 PrkAidSnsRlCntr_D_Stat 1;
BA_ "U_P552_MY15_Gas_Rx" SG_ 939 PrkAidSnsRlCntr_D_Stat 1;
BA_ "U_S550_MY15_Gas_Rx" SG_ 939 PrkAidSnsRlCntr_D_Stat 1;
BA_ "U_C489_MY14_Gas_Rx" SG_ 939 PrkAidSnsRlCntr_D_Stat 1;
BA_ "U_U502_MY15_Gas_Rx" SG_ 939 PrkAidSnsRlCntr_D_Stat 1;
BA_ "U_UP375_MY15_Gas_Rx" SG_ 939 PrkAidSnsRlCntr_D_Stat 1;
BA_ "U_UP375_MY15_Diesel_Rx" SG_ 939 PrkAidSnsRlCntr_D_Stat 1;
BA_ "U_CD43_MY16_Gas_Rx" SG_ 939 PrkAidSnsRlCntr_D_Stat 1;
BA_ "U_CD4_MY14_Diesel_Rx" SG_ 939 PrkAidSnsRlCntr_D_Stat 1;
BA_ "U_CD4_MY14_Gas_Rx" SG_ 939 PrkAidSnsRlCntr_D_Stat 1;
BA_ "U_CD4_MY14_Hev_Rx" SG_ 939 PrkAidSnsRlCntr_D_Stat 1;
BA_ "U_CD4_MY14_Phev_Rx" SG_ 939 PrkAidSnsRlCntr_D_Stat 1;
BA_ "U_CD4_MY13_Diesel_Tx" SG_ 939 PrkAidSnsRlCntr_D_Stat 1;
BA_ "U_CD4_MY13_Gas_Tx" SG_ 939 PrkAidSnsRlCntr_D_Stat 1;
BA_ "U_CD4_MY13_Hev_Tx" SG_ 939 PrkAidSnsRlCntr_D_Stat 1;
BA_ "U_CD4_MY13_Phev_Tx" SG_ 939 PrkAidSnsRlCntr_D_Stat 1;
BA_ "U_CD42_MY14_Diesel_Tx" SG_ 939 PrkAidSnsRlCntr_D_Stat 1;
BA_ "U_CD42_MY14_Gas_Tx" SG_ 939 PrkAidSnsRlCntr_D_Stat 1;
BA_ "U_P552_MY15_Gas_Tx" SG_ 939 PrkAidSnsRlCntr_D_Stat 1;
BA_ "U_S550_MY15_Gas_Tx" SG_ 939 PrkAidSnsRlCntr_D_Stat 1;
BA_ "U_C489_MY14_Gas_Tx" SG_ 939 PrkAidSnsRlCntr_D_Stat 1;
BA_ "U_U502_MY15_Gas_Tx" SG_ 939 PrkAidSnsRlCntr_D_Stat 1;
BA_ "U_UP375_MY15_Gas_Tx" SG_ 939 PrkAidSnsRlCntr_D_Stat 1;
BA_ "U_UP375_MY15_Diesel_Tx" SG_ 939 PrkAidSnsRlCntr_D_Stat 1;
BA_ "U_CD43_MY16_Gas_Tx" SG_ 939 PrkAidSnsRlCntr_D_Stat 1;
BA_ "U_CD4_MY14_Diesel_Tx" SG_ 939 PrkAidSnsRlCntr_D_Stat 1;
BA_ "U_CD4_MY14_Gas_Tx" SG_ 939 PrkAidSnsRlCntr_D_Stat 1;
BA_ "U_CD4_MY14_Hev_Tx" SG_ 939 PrkAidSnsRlCntr_D_Stat 1;
BA_ "U_CD4_MY14_Phev_Tx" SG_ 939 PrkAidSnsRlCntr_D_Stat 1;
BA_ "CrossOver_InfoCAN" SG_ 939 PrkAidSnsRrSide_D_Stat 1;
BA_ "GenSigSendType" SG_ 939 PrkAidSnsRrSide_D_Stat 3;
BA_ "U_CD4_MY13_Diesel_Rx" SG_ 939 PrkAidSnsRrSide_D_Stat 1;
BA_ "U_CD4_MY13_Gas_Rx" SG_ 939 PrkAidSnsRrSide_D_Stat 1;
BA_ "U_CD4_MY13_Hev_Rx" SG_ 939 PrkAidSnsRrSide_D_Stat 1;
BA_ "U_CD4_MY13_Phev_Rx" SG_ 939 PrkAidSnsRrSide_D_Stat 1;
BA_ "U_CD42_MY14_Diesel_Rx" SG_ 939 PrkAidSnsRrSide_D_Stat 1;
BA_ "U_CD42_MY14_Gas_Rx" SG_ 939 PrkAidSnsRrSide_D_Stat 1;
BA_ "U_P552_MY15_Gas_Rx" SG_ 939 PrkAidSnsRrSide_D_Stat 1;
BA_ "U_S550_MY15_Gas_Rx" SG_ 939 PrkAidSnsRrSide_D_Stat 1;
BA_ "U_C489_MY14_Gas_Rx" SG_ 939 PrkAidSnsRrSide_D_Stat 1;
BA_ "U_U502_MY15_Gas_Rx" SG_ 939 PrkAidSnsRrSide_D_Stat 1;
BA_ "U_UP375_MY15_Gas_Rx" SG_ 939 PrkAidSnsRrSide_D_Stat 1;
BA_ "U_UP375_MY15_Diesel_Rx" SG_ 939 PrkAidSnsRrSide_D_Stat 1;
BA_ "U_CD43_MY16_Gas_Rx" SG_ 939 PrkAidSnsRrSide_D_Stat 1;
BA_ "U_CD4_MY14_Diesel_Rx" SG_ 939 PrkAidSnsRrSide_D_Stat 1;
BA_ "U_CD4_MY14_Gas_Rx" SG_ 939 PrkAidSnsRrSide_D_Stat 1;
BA_ "U_CD4_MY14_Hev_Rx" SG_ 939 PrkAidSnsRrSide_D_Stat 1;
BA_ "U_CD4_MY14_Phev_Rx" SG_ 939 PrkAidSnsRrSide_D_Stat 1;
BA_ "U_CD4_MY13_Diesel_Tx" SG_ 939 PrkAidSnsRrSide_D_Stat 1;
BA_ "U_CD4_MY13_Gas_Tx" SG_ 939 PrkAidSnsRrSide_D_Stat 1;
BA_ "U_CD4_MY13_Hev_Tx" SG_ 939 PrkAidSnsRrSide_D_Stat 1;
BA_ "U_CD4_MY13_Phev_Tx" SG_ 939 PrkAidSnsRrSide_D_Stat 1;
BA_ "U_CD42_MY14_Diesel_Tx" SG_ 939 PrkAidSnsRrSide_D_Stat 1;
BA_ "U_CD42_MY14_Gas_Tx" SG_ 939 PrkAidSnsRrSide_D_Stat 1;
BA_ "U_P552_MY15_Gas_Tx" SG_ 939 PrkAidSnsRrSide_D_Stat 1;
BA_ "U_S550_MY15_Gas_Tx" SG_ 939 PrkAidSnsRrSide_D_Stat 1;
BA_ "U_C489_MY14_Gas_Tx" SG_ 939 PrkAidSnsRrSide_D_Stat 1;
BA_ "U_U502_MY15_Gas_Tx" SG_ 939 PrkAidSnsRrSide_D_Stat 1;
BA_ "U_UP375_MY15_Gas_Tx" SG_ 939 PrkAidSnsRrSide_D_Stat 1;
BA_ "U_UP375_MY15_Diesel_Tx" SG_ 939 PrkAidSnsRrSide_D_Stat 1;
BA_ "U_CD43_MY16_Gas_Tx" SG_ 939 PrkAidSnsRrSide_D_Stat 1;
BA_ "U_CD4_MY14_Diesel_Tx" SG_ 939 PrkAidSnsRrSide_D_Stat 1;
BA_ "U_CD4_MY14_Gas_Tx" SG_ 939 PrkAidSnsRrSide_D_Stat 1;
BA_ "U_CD4_MY14_Hev_Tx" SG_ 939 PrkAidSnsRrSide_D_Stat 1;
BA_ "U_CD4_MY14_Phev_Tx" SG_ 939 PrkAidSnsRrSide_D_Stat 1;
BA_ "CrossOver_InfoCAN" SG_ 939 PrkAidSnsRrCrnr_D_Stat 1;
BA_ "GenSigSendType" SG_ 939 PrkAidSnsRrCrnr_D_Stat 3;
BA_ "U_CD4_MY13_Diesel_Rx" SG_ 939 PrkAidSnsRrCrnr_D_Stat 1;
BA_ "U_CD4_MY13_Gas_Rx" SG_ 939 PrkAidSnsRrCrnr_D_Stat 1;
BA_ "U_CD4_MY13_Hev_Rx" SG_ 939 PrkAidSnsRrCrnr_D_Stat 1;
BA_ "U_CD4_MY13_Phev_Rx" SG_ 939 PrkAidSnsRrCrnr_D_Stat 1;
BA_ "U_CD42_MY14_Diesel_Rx" SG_ 939 PrkAidSnsRrCrnr_D_Stat 1;
BA_ "U_CD42_MY14_Gas_Rx" SG_ 939 PrkAidSnsRrCrnr_D_Stat 1;
BA_ "U_P552_MY15_Gas_Rx" SG_ 939 PrkAidSnsRrCrnr_D_Stat 1;
BA_ "U_S550_MY15_Gas_Rx" SG_ 939 PrkAidSnsRrCrnr_D_Stat 1;
BA_ "U_C489_MY14_Gas_Rx" SG_ 939 PrkAidSnsRrCrnr_D_Stat 1;
BA_ "U_U502_MY15_Gas_Rx" SG_ 939 PrkAidSnsRrCrnr_D_Stat 1;
BA_ "U_UP375_MY15_Gas_Rx" SG_ 939 PrkAidSnsRrCrnr_D_Stat 1;
BA_ "U_UP375_MY15_Diesel_Rx" SG_ 939 PrkAidSnsRrCrnr_D_Stat 1;
BA_ "U_CD43_MY16_Gas_Rx" SG_ 939 PrkAidSnsRrCrnr_D_Stat 1;
BA_ "U_CD4_MY14_Diesel_Rx" SG_ 939 PrkAidSnsRrCrnr_D_Stat 1;
BA_ "U_CD4_MY14_Gas_Rx" SG_ 939 PrkAidSnsRrCrnr_D_Stat 1;
BA_ "U_CD4_MY14_Hev_Rx" SG_ 939 PrkAidSnsRrCrnr_D_Stat 1;
BA_ "U_CD4_MY14_Phev_Rx" SG_ 939 PrkAidSnsRrCrnr_D_Stat 1;
BA_ "U_CD4_MY13_Diesel_Tx" SG_ 939 PrkAidSnsRrCrnr_D_Stat 1;
BA_ "U_CD4_MY13_Gas_Tx" SG_ 939 PrkAidSnsRrCrnr_D_Stat 1;
BA_ "U_CD4_MY13_Hev_Tx" SG_ 939 PrkAidSnsRrCrnr_D_Stat 1;
BA_ "U_CD4_MY13_Phev_Tx" SG_ 939 PrkAidSnsRrCrnr_D_Stat 1;
BA_ "U_CD42_MY14_Diesel_Tx" SG_ 939 PrkAidSnsRrCrnr_D_Stat 1;
BA_ "U_CD42_MY14_Gas_Tx" SG_ 939 PrkAidSnsRrCrnr_D_Stat 1;
BA_ "U_P552_MY15_Gas_Tx" SG_ 939 PrkAidSnsRrCrnr_D_Stat 1;
BA_ "U_S550_MY15_Gas_Tx" SG_ 939 PrkAidSnsRrCrnr_D_Stat 1;
BA_ "U_C489_MY14_Gas_Tx" SG_ 939 PrkAidSnsRrCrnr_D_Stat 1;
BA_ "U_U502_MY15_Gas_Tx" SG_ 939 PrkAidSnsRrCrnr_D_Stat 1;
BA_ "U_UP375_MY15_Gas_Tx" SG_ 939 PrkAidSnsRrCrnr_D_Stat 1;
BA_ "U_UP375_MY15_Diesel_Tx" SG_ 939 PrkAidSnsRrCrnr_D_Stat 1;
BA_ "U_CD43_MY16_Gas_Tx" SG_ 939 PrkAidSnsRrCrnr_D_Stat 1;
BA_ "U_CD4_MY14_Diesel_Tx" SG_ 939 PrkAidSnsRrCrnr_D_Stat 1;
BA_ "U_CD4_MY14_Gas_Tx" SG_ 939 PrkAidSnsRrCrnr_D_Stat 1;
BA_ "U_CD4_MY14_Hev_Tx" SG_ 939 PrkAidSnsRrCrnr_D_Stat 1;
BA_ "U_CD4_MY14_Phev_Tx" SG_ 939 PrkAidSnsRrCrnr_D_Stat 1;
BA_ "CrossOver_InfoCAN" SG_ 939 PrkAidSnsRrCntr_D_Stat 1;
BA_ "GenSigSendType" SG_ 939 PrkAidSnsRrCntr_D_Stat 3;
BA_ "U_CD4_MY13_Diesel_Rx" SG_ 939 PrkAidSnsRrCntr_D_Stat 1;
BA_ "U_CD4_MY13_Gas_Rx" SG_ 939 PrkAidSnsRrCntr_D_Stat 1;
BA_ "U_CD4_MY13_Hev_Rx" SG_ 939 PrkAidSnsRrCntr_D_Stat 1;
BA_ "U_CD4_MY13_Phev_Rx" SG_ 939 PrkAidSnsRrCntr_D_Stat 1;
BA_ "U_CD42_MY14_Diesel_Rx" SG_ 939 PrkAidSnsRrCntr_D_Stat 1;
BA_ "U_CD42_MY14_Gas_Rx" SG_ 939 PrkAidSnsRrCntr_D_Stat 1;
BA_ "U_P552_MY15_Gas_Rx" SG_ 939 PrkAidSnsRrCntr_D_Stat 1;
BA_ "U_S550_MY15_Gas_Rx" SG_ 939 PrkAidSnsRrCntr_D_Stat 1;
BA_ "U_C489_MY14_Gas_Rx" SG_ 939 PrkAidSnsRrCntr_D_Stat 1;
BA_ "U_U502_MY15_Gas_Rx" SG_ 939 PrkAidSnsRrCntr_D_Stat 1;
BA_ "U_UP375_MY15_Gas_Rx" SG_ 939 PrkAidSnsRrCntr_D_Stat 1;
BA_ "U_UP375_MY15_Diesel_Rx" SG_ 939 PrkAidSnsRrCntr_D_Stat 1;
BA_ "U_CD43_MY16_Gas_Rx" SG_ 939 PrkAidSnsRrCntr_D_Stat 1;
BA_ "U_CD4_MY14_Diesel_Rx" SG_ 939 PrkAidSnsRrCntr_D_Stat 1;
BA_ "U_CD4_MY14_Gas_Rx" SG_ 939 PrkAidSnsRrCntr_D_Stat 1;
BA_ "U_CD4_MY14_Hev_Rx" SG_ 939 PrkAidSnsRrCntr_D_Stat 1;
BA_ "U_CD4_MY14_Phev_Rx" SG_ 939 PrkAidSnsRrCntr_D_Stat 1;
BA_ "U_CD4_MY13_Diesel_Tx" SG_ 939 PrkAidSnsRrCntr_D_Stat 1;
BA_ "U_CD4_MY13_Gas_Tx" SG_ 939 PrkAidSnsRrCntr_D_Stat 1;
BA_ "U_CD4_MY13_Hev_Tx" SG_ 939 PrkAidSnsRrCntr_D_Stat 1;
BA_ "U_CD4_MY13_Phev_Tx" SG_ 939 PrkAidSnsRrCntr_D_Stat 1;
BA_ "U_CD42_MY14_Diesel_Tx" SG_ 939 PrkAidSnsRrCntr_D_Stat 1;
BA_ "U_CD42_MY14_Gas_Tx" SG_ 939 PrkAidSnsRrCntr_D_Stat 1;
BA_ "U_P552_MY15_Gas_Tx" SG_ 939 PrkAidSnsRrCntr_D_Stat 1;
BA_ "U_S550_MY15_Gas_Tx" SG_ 939 PrkAidSnsRrCntr_D_Stat 1;
BA_ "U_C489_MY14_Gas_Tx" SG_ 939 PrkAidSnsRrCntr_D_Stat 1;
BA_ "U_U502_MY15_Gas_Tx" SG_ 939 PrkAidSnsRrCntr_D_Stat 1;
BA_ "U_UP375_MY15_Gas_Tx" SG_ 939 PrkAidSnsRrCntr_D_Stat 1;
BA_ "U_UP375_MY15_Diesel_Tx" SG_ 939 PrkAidSnsRrCntr_D_Stat 1;
BA_ "U_CD43_MY16_Gas_Tx" SG_ 939 PrkAidSnsRrCntr_D_Stat 1;
BA_ "U_CD4_MY14_Diesel_Tx" SG_ 939 PrkAidSnsRrCntr_D_Stat 1;
BA_ "U_CD4_MY14_Gas_Tx" SG_ 939 PrkAidSnsRrCntr_D_Stat 1;
BA_ "U_CD4_MY14_Hev_Tx" SG_ 939 PrkAidSnsRrCntr_D_Stat 1;
BA_ "U_CD4_MY14_Phev_Tx" SG_ 939 PrkAidSnsRrCntr_D_Stat 1;
BA_ "CrossOver_InfoCAN" SG_ 939 PrkAidSnsRlSide_D_Stat 1;
BA_ "GenSigSendType" SG_ 939 PrkAidSnsRlSide_D_Stat 3;
BA_ "U_CD4_MY13_Diesel_Rx" SG_ 939 PrkAidSnsRlSide_D_Stat 1;
BA_ "U_CD4_MY13_Gas_Rx" SG_ 939 PrkAidSnsRlSide_D_Stat 1;
BA_ "U_CD4_MY13_Hev_Rx" SG_ 939 PrkAidSnsRlSide_D_Stat 1;
BA_ "U_CD4_MY13_Phev_Rx" SG_ 939 PrkAidSnsRlSide_D_Stat 1;
BA_ "U_CD42_MY14_Diesel_Rx" SG_ 939 PrkAidSnsRlSide_D_Stat 1;
BA_ "U_CD42_MY14_Gas_Rx" SG_ 939 PrkAidSnsRlSide_D_Stat 1;
BA_ "U_P552_MY15_Gas_Rx" SG_ 939 PrkAidSnsRlSide_D_Stat 1;
BA_ "U_S550_MY15_Gas_Rx" SG_ 939 PrkAidSnsRlSide_D_Stat 1;
BA_ "U_C489_MY14_Gas_Rx" SG_ 939 PrkAidSnsRlSide_D_Stat 1;
BA_ "U_U502_MY15_Gas_Rx" SG_ 939 PrkAidSnsRlSide_D_Stat 1;
BA_ "U_UP375_MY15_Gas_Rx" SG_ 939 PrkAidSnsRlSide_D_Stat 1;
BA_ "U_UP375_MY15_Diesel_Rx" SG_ 939 PrkAidSnsRlSide_D_Stat 1;
BA_ "U_CD43_MY16_Gas_Rx" SG_ 939 PrkAidSnsRlSide_D_Stat 1;
BA_ "U_CD4_MY14_Diesel_Rx" SG_ 939 PrkAidSnsRlSide_D_Stat 1;
BA_ "U_CD4_MY14_Gas_Rx" SG_ 939 PrkAidSnsRlSide_D_Stat 1;
BA_ "U_CD4_MY14_Hev_Rx" SG_ 939 PrkAidSnsRlSide_D_Stat 1;
BA_ "U_CD4_MY14_Phev_Rx" SG_ 939 PrkAidSnsRlSide_D_Stat 1;
BA_ "U_CD4_MY13_Diesel_Tx" SG_ 939 PrkAidSnsRlSide_D_Stat 1;
BA_ "U_CD4_MY13_Gas_Tx" SG_ 939 PrkAidSnsRlSide_D_Stat 1;
BA_ "U_CD4_MY13_Hev_Tx" SG_ 939 PrkAidSnsRlSide_D_Stat 1;
BA_ "U_CD4_MY13_Phev_Tx" SG_ 939 PrkAidSnsRlSide_D_Stat 1;
BA_ "U_CD42_MY14_Diesel_Tx" SG_ 939 PrkAidSnsRlSide_D_Stat 1;
BA_ "U_CD42_MY14_Gas_Tx" SG_ 939 PrkAidSnsRlSide_D_Stat 1;
BA_ "U_P552_MY15_Gas_Tx" SG_ 939 PrkAidSnsRlSide_D_Stat 1;
BA_ "U_S550_MY15_Gas_Tx" SG_ 939 PrkAidSnsRlSide_D_Stat 1;
BA_ "U_C489_MY14_Gas_Tx" SG_ 939 PrkAidSnsRlSide_D_Stat 1;
BA_ "U_U502_MY15_Gas_Tx" SG_ 939 PrkAidSnsRlSide_D_Stat 1;
BA_ "U_UP375_MY15_Gas_Tx" SG_ 939 PrkAidSnsRlSide_D_Stat 1;
BA_ "U_UP375_MY15_Diesel_Tx" SG_ 939 PrkAidSnsRlSide_D_Stat 1;
BA_ "U_CD43_MY16_Gas_Tx" SG_ 939 PrkAidSnsRlSide_D_Stat 1;
BA_ "U_CD4_MY14_Diesel_Tx" SG_ 939 PrkAidSnsRlSide_D_Stat 1;
BA_ "U_CD4_MY14_Gas_Tx" SG_ 939 PrkAidSnsRlSide_D_Stat 1;
BA_ "U_CD4_MY14_Hev_Tx" SG_ 939 PrkAidSnsRlSide_D_Stat 1;
BA_ "U_CD4_MY14_Phev_Tx" SG_ 939 PrkAidSnsRlSide_D_Stat 1;
BA_ "CrossOver_InfoCAN" SG_ 939 PrkAidSnsRlCrnr_D_Stat 1;
BA_ "GenSigSendType" SG_ 939 PrkAidSnsRlCrnr_D_Stat 3;
BA_ "U_CD4_MY13_Diesel_Rx" SG_ 939 PrkAidSnsRlCrnr_D_Stat 1;
BA_ "U_CD4_MY13_Gas_Rx" SG_ 939 PrkAidSnsRlCrnr_D_Stat 1;
BA_ "U_CD4_MY13_Hev_Rx" SG_ 939 PrkAidSnsRlCrnr_D_Stat 1;
BA_ "U_CD4_MY13_Phev_Rx" SG_ 939 PrkAidSnsRlCrnr_D_Stat 1;
BA_ "U_CD42_MY14_Diesel_Rx" SG_ 939 PrkAidSnsRlCrnr_D_Stat 1;
BA_ "U_CD42_MY14_Gas_Rx" SG_ 939 PrkAidSnsRlCrnr_D_Stat 1;
BA_ "U_P552_MY15_Gas_Rx" SG_ 939 PrkAidSnsRlCrnr_D_Stat 1;
BA_ "U_S550_MY15_Gas_Rx" SG_ 939 PrkAidSnsRlCrnr_D_Stat 1;
BA_ "U_C489_MY14_Gas_Rx" SG_ 939 PrkAidSnsRlCrnr_D_Stat 1;
BA_ "U_U502_MY15_Gas_Rx" SG_ 939 PrkAidSnsRlCrnr_D_Stat 1;
BA_ "U_UP375_MY15_Gas_Rx" SG_ 939 PrkAidSnsRlCrnr_D_Stat 1;
BA_ "U_UP375_MY15_Diesel_Rx" SG_ 939 PrkAidSnsRlCrnr_D_Stat 1;
BA_ "U_CD43_MY16_Gas_Rx" SG_ 939 PrkAidSnsRlCrnr_D_Stat 1;
BA_ "U_CD4_MY14_Diesel_Rx" SG_ 939 PrkAidSnsRlCrnr_D_Stat 1;
BA_ "U_CD4_MY14_Gas_Rx" SG_ 939 PrkAidSnsRlCrnr_D_Stat 1;
BA_ "U_CD4_MY14_Hev_Rx" SG_ 939 PrkAidSnsRlCrnr_D_Stat 1;
BA_ "U_CD4_MY14_Phev_Rx" SG_ 939 PrkAidSnsRlCrnr_D_Stat 1;
BA_ "U_CD4_MY13_Diesel_Tx" SG_ 939 PrkAidSnsRlCrnr_D_Stat 1;
BA_ "U_CD4_MY13_Gas_Tx" SG_ 939 PrkAidSnsRlCrnr_D_Stat 1;
BA_ "U_CD4_MY13_Hev_Tx" SG_ 939 PrkAidSnsRlCrnr_D_Stat 1;
BA_ "U_CD4_MY13_Phev_Tx" SG_ 939 PrkAidSnsRlCrnr_D_Stat 1;
BA_ "U_CD42_MY14_Diesel_Tx" SG_ 939 PrkAidSnsRlCrnr_D_Stat 1;
BA_ "U_CD42_MY14_Gas_Tx" SG_ 939 PrkAidSnsRlCrnr_D_Stat 1;
BA_ "U_P552_MY15_Gas_Tx" SG_ 939 PrkAidSnsRlCrnr_D_Stat 1;
BA_ "U_S550_MY15_Gas_Tx" SG_ 939 PrkAidSnsRlCrnr_D_Stat 1;
BA_ "U_C489_MY14_Gas_Tx" SG_ 939 PrkAidSnsRlCrnr_D_Stat 1;
BA_ "U_U502_MY15_Gas_Tx" SG_ 939 PrkAidSnsRlCrnr_D_Stat 1;
BA_ "U_UP375_MY15_Gas_Tx" SG_ 939 PrkAidSnsRlCrnr_D_Stat 1;
BA_ "U_UP375_MY15_Diesel_Tx" SG_ 939 PrkAidSnsRlCrnr_D_Stat 1;
BA_ "U_CD43_MY16_Gas_Tx" SG_ 939 PrkAidSnsRlCrnr_D_Stat 1;
BA_ "U_CD4_MY14_Diesel_Tx" SG_ 939 PrkAidSnsRlCrnr_D_Stat 1;
BA_ "U_CD4_MY14_Gas_Tx" SG_ 939 PrkAidSnsRlCrnr_D_Stat 1;
BA_ "U_CD4_MY14_Hev_Tx" SG_ 939 PrkAidSnsRlCrnr_D_Stat 1;
BA_ "U_CD4_MY14_Phev_Tx" SG_ 939 PrkAidSnsRlCrnr_D_Stat 1;
BA_ "CrossOver_InfoCAN" SG_ 939 PrkAidRear_D_Stat 1;
BA_ "GenSigSendType" SG_ 939 PrkAidRear_D_Stat 3;
BA_ "U_CD4_MY13_Diesel_Tx" SG_ 939 PrkAidRear_D_Stat 1;
BA_ "U_CD4_MY13_Gas_Tx" SG_ 939 PrkAidRear_D_Stat 1;
BA_ "U_CD4_MY13_Hev_Tx" SG_ 939 PrkAidRear_D_Stat 1;
BA_ "U_CD4_MY13_Phev_Tx" SG_ 939 PrkAidRear_D_Stat 1;
BA_ "U_CD42_MY14_Diesel_Tx" SG_ 939 PrkAidRear_D_Stat 1;
BA_ "U_CD42_MY14_Gas_Tx" SG_ 939 PrkAidRear_D_Stat 1;
BA_ "U_P552_MY15_Gas_Tx" SG_ 939 PrkAidRear_D_Stat 1;
BA_ "U_S550_MY15_Gas_Tx" SG_ 939 PrkAidRear_D_Stat 1;
BA_ "U_C489_MY14_Gas_Tx" SG_ 939 PrkAidRear_D_Stat 1;
BA_ "U_U502_MY15_Gas_Tx" SG_ 939 PrkAidRear_D_Stat 1;
BA_ "U_UP375_MY15_Gas_Tx" SG_ 939 PrkAidRear_D_Stat 1;
BA_ "U_UP375_MY15_Diesel_Tx" SG_ 939 PrkAidRear_D_Stat 1;
BA_ "U_CD43_MY16_Gas_Tx" SG_ 939 PrkAidRear_D_Stat 1;
BA_ "U_CD4_MY14_Diesel_Tx" SG_ 939 PrkAidRear_D_Stat 1;
BA_ "U_CD4_MY14_Gas_Tx" SG_ 939 PrkAidRear_D_Stat 1;
BA_ "U_CD4_MY14_Hev_Tx" SG_ 939 PrkAidRear_D_Stat 1;
BA_ "U_CD4_MY14_Phev_Tx" SG_ 939 PrkAidRear_D_Stat 1;
BA_ "CrossOver_InfoCAN" SG_ 939 PrkAidFront_D_Stat 1;
BA_ "GenSigSendType" SG_ 939 PrkAidFront_D_Stat 3;
BA_ "U_CD4_MY13_Diesel_Tx" SG_ 939 PrkAidFront_D_Stat 1;
BA_ "U_CD4_MY13_Gas_Tx" SG_ 939 PrkAidFront_D_Stat 1;
BA_ "U_CD4_MY13_Hev_Tx" SG_ 939 PrkAidFront_D_Stat 1;
BA_ "U_CD4_MY13_Phev_Tx" SG_ 939 PrkAidFront_D_Stat 1;
BA_ "U_CD42_MY14_Diesel_Tx" SG_ 939 PrkAidFront_D_Stat 1;
BA_ "U_CD42_MY14_Gas_Tx" SG_ 939 PrkAidFront_D_Stat 1;
BA_ "U_P552_MY15_Gas_Tx" SG_ 939 PrkAidFront_D_Stat 1;
BA_ "U_S550_MY15_Gas_Tx" SG_ 939 PrkAidFront_D_Stat 1;
BA_ "U_C489_MY14_Gas_Tx" SG_ 939 PrkAidFront_D_Stat 1;
BA_ "U_U502_MY15_Gas_Tx" SG_ 939 PrkAidFront_D_Stat 1;
BA_ "U_UP375_MY15_Gas_Tx" SG_ 939 PrkAidFront_D_Stat 1;
BA_ "U_UP375_MY15_Diesel_Tx" SG_ 939 PrkAidFront_D_Stat 1;
BA_ "U_CD43_MY16_Gas_Tx" SG_ 939 PrkAidFront_D_Stat 1;
BA_ "U_CD4_MY14_Diesel_Tx" SG_ 939 PrkAidFront_D_Stat 1;
BA_ "U_CD4_MY14_Gas_Tx" SG_ 939 PrkAidFront_D_Stat 1;
BA_ "U_CD4_MY14_Hev_Tx" SG_ 939 PrkAidFront_D_Stat 1;
BA_ "U_CD4_MY14_Phev_Tx" SG_ 939 PrkAidFront_D_Stat 1;
BA_ "CrossOver_InfoCAN" SG_ 939 PrkAid_D_Falt 1;
BA_ "GenSigSendType" SG_ 939 PrkAid_D_Falt 3;
BA_ "U_CD4_MY13_Diesel_Rx" SG_ 939 PrkAid_D_Falt 1;
BA_ "U_CD4_MY13_Gas_Rx" SG_ 939 PrkAid_D_Falt 1;
BA_ "U_CD4_MY13_Hev_Rx" SG_ 939 PrkAid_D_Falt 1;
BA_ "U_CD4_MY13_Phev_Rx" SG_ 939 PrkAid_D_Falt 1;
BA_ "U_CD42_MY14_Diesel_Rx" SG_ 939 PrkAid_D_Falt 1;
BA_ "U_CD42_MY14_Gas_Rx" SG_ 939 PrkAid_D_Falt 1;
BA_ "U_P552_MY15_Gas_Rx" SG_ 939 PrkAid_D_Falt 1;
BA_ "U_S550_MY15_Gas_Rx" SG_ 939 PrkAid_D_Falt 1;
BA_ "U_C489_MY14_Gas_Rx" SG_ 939 PrkAid_D_Falt 1;
BA_ "U_U502_MY15_Gas_Rx" SG_ 939 PrkAid_D_Falt 1;
BA_ "U_UP375_MY15_Gas_Rx" SG_ 939 PrkAid_D_Falt 1;
BA_ "U_UP375_MY15_Diesel_Rx" SG_ 939 PrkAid_D_Falt 1;
BA_ "U_CD43_MY16_Gas_Rx" SG_ 939 PrkAid_D_Falt 1;
BA_ "U_CD4_MY14_Diesel_Rx" SG_ 939 PrkAid_D_Falt 1;
BA_ "U_CD4_MY14_Gas_Rx" SG_ 939 PrkAid_D_Falt 1;
BA_ "U_CD4_MY14_Hev_Rx" SG_ 939 PrkAid_D_Falt 1;
BA_ "U_CD4_MY14_Phev_Rx" SG_ 939 PrkAid_D_Falt 1;
BA_ "U_CD4_MY13_Diesel_Tx" SG_ 939 PrkAid_D_Falt 1;
BA_ "U_CD4_MY13_Gas_Tx" SG_ 939 PrkAid_D_Falt 1;
BA_ "U_CD4_MY13_Hev_Tx" SG_ 939 PrkAid_D_Falt 1;
BA_ "U_CD4_MY13_Phev_Tx" SG_ 939 PrkAid_D_Falt 1;
BA_ "U_CD42_MY14_Diesel_Tx" SG_ 939 PrkAid_D_Falt 1;
BA_ "U_CD42_MY14_Gas_Tx" SG_ 939 PrkAid_D_Falt 1;
BA_ "U_P552_MY15_Gas_Tx" SG_ 939 PrkAid_D_Falt 1;
BA_ "U_S550_MY15_Gas_Tx" SG_ 939 PrkAid_D_Falt 1;
BA_ "U_C489_MY14_Gas_Tx" SG_ 939 PrkAid_D_Falt 1;
BA_ "U_U502_MY15_Gas_Tx" SG_ 939 PrkAid_D_Falt 1;
BA_ "U_UP375_MY15_Gas_Tx" SG_ 939 PrkAid_D_Falt 1;
BA_ "U_UP375_MY15_Diesel_Tx" SG_ 939 PrkAid_D_Falt 1;
BA_ "U_CD43_MY16_Gas_Tx" SG_ 939 PrkAid_D_Falt 1;
BA_ "U_CD4_MY14_Diesel_Tx" SG_ 939 PrkAid_D_Falt 1;
BA_ "U_CD4_MY14_Gas_Tx" SG_ 939 PrkAid_D_Falt 1;
BA_ "U_CD4_MY14_Hev_Tx" SG_ 939 PrkAid_D_Falt 1;
BA_ "U_CD4_MY14_Phev_Tx" SG_ 939 PrkAid_D_Falt 1;
BA_ "CrossOver_InfoCAN" SG_ 952 Tire_Press_IRR_Data 1;
BA_ "GenSigStartValue" SG_ 952 Tire_Press_IRR_Data 65533;
BA_ "U_CD4_MY13_Diesel_Tx" SG_ 952 Tire_Press_IRR_Data 1;
BA_ "U_CD4_MY13_Gas_Tx" SG_ 952 Tire_Press_IRR_Data 1;
BA_ "U_CD4_MY13_Hev_Tx" SG_ 952 Tire_Press_IRR_Data 1;
BA_ "U_CD4_MY13_Phev_Tx" SG_ 952 Tire_Press_IRR_Data 1;
BA_ "U_CD42_MY14_Diesel_Tx" SG_ 952 Tire_Press_IRR_Data 1;
BA_ "U_CD42_MY14_Gas_Tx" SG_ 952 Tire_Press_IRR_Data 1;
BA_ "U_P552_MY15_Gas_Tx" SG_ 952 Tire_Press_IRR_Data 1;
BA_ "U_S550_MY15_Gas_Tx" SG_ 952 Tire_Press_IRR_Data 1;
BA_ "U_C489_MY14_Gas_Tx" SG_ 952 Tire_Press_IRR_Data 1;
BA_ "U_U502_MY15_Gas_Tx" SG_ 952 Tire_Press_IRR_Data 1;
BA_ "U_UP375_MY15_Gas_Tx" SG_ 952 Tire_Press_IRR_Data 1;
BA_ "U_UP375_MY15_Diesel_Tx" SG_ 952 Tire_Press_IRR_Data 1;
BA_ "U_CD43_MY16_Gas_Tx" SG_ 952 Tire_Press_IRR_Data 1;
BA_ "U_CD4_MY14_Diesel_Tx" SG_ 952 Tire_Press_IRR_Data 1;
BA_ "U_CD4_MY14_Gas_Tx" SG_ 952 Tire_Press_IRR_Data 1;
BA_ "U_CD4_MY14_Hev_Tx" SG_ 952 Tire_Press_IRR_Data 1;
BA_ "U_CD4_MY14_Phev_Tx" SG_ 952 Tire_Press_IRR_Data 1;
BA_ "CrossOver_InfoCAN" SG_ 952 Tire_Press_ILR_Data 1;
BA_ "GenSigStartValue" SG_ 952 Tire_Press_ILR_Data 65533;
BA_ "U_CD4_MY13_Diesel_Tx" SG_ 952 Tire_Press_ILR_Data 1;
BA_ "U_CD4_MY13_Gas_Tx" SG_ 952 Tire_Press_ILR_Data 1;
BA_ "U_CD4_MY13_Hev_Tx" SG_ 952 Tire_Press_ILR_Data 1;
BA_ "U_CD4_MY13_Phev_Tx" SG_ 952 Tire_Press_ILR_Data 1;
BA_ "U_CD42_MY14_Diesel_Tx" SG_ 952 Tire_Press_ILR_Data 1;
BA_ "U_CD42_MY14_Gas_Tx" SG_ 952 Tire_Press_ILR_Data 1;
BA_ "U_P552_MY15_Gas_Tx" SG_ 952 Tire_Press_ILR_Data 1;
BA_ "U_S550_MY15_Gas_Tx" SG_ 952 Tire_Press_ILR_Data 1;
BA_ "U_C489_MY14_Gas_Tx" SG_ 952 Tire_Press_ILR_Data 1;
BA_ "U_U502_MY15_Gas_Tx" SG_ 952 Tire_Press_ILR_Data 1;
BA_ "U_UP375_MY15_Gas_Tx" SG_ 952 Tire_Press_ILR_Data 1;
BA_ "U_UP375_MY15_Diesel_Tx" SG_ 952 Tire_Press_ILR_Data 1;
BA_ "U_CD43_MY16_Gas_Tx" SG_ 952 Tire_Press_ILR_Data 1;
BA_ "U_CD4_MY14_Diesel_Tx" SG_ 952 Tire_Press_ILR_Data 1;
BA_ "U_CD4_MY14_Gas_Tx" SG_ 952 Tire_Press_ILR_Data 1;
BA_ "U_CD4_MY14_Hev_Tx" SG_ 952 Tire_Press_ILR_Data 1;
BA_ "U_CD4_MY14_Phev_Tx" SG_ 952 Tire_Press_ILR_Data 1;
BA_ "U_V36X_MY18_5_Hev_Tx" SG_ 1095 VehLck_D_Dsply 1;
BA_ "U_V36X_MY18_5_Gas_Tx" SG_ 1095 VehLck_D_Dsply 1;
BA_ "U_V363E_N_MY19_5_20_Diesel_Tx" SG_ 1095 VehLck_D_Dsply 1;
BA_ "U_V363E_N_MY19_5_20_Gas_Tx" SG_ 1095 VehLck_D_Dsply 1;
BA_ "U_V36X_MY19_5_Diesel_Tx" SG_ 1095 VehLck_D_Dsply 1;
BA_ "U_P552_MY18_5_Diesel_Tx" SG_ 1095 VehLck_D_Dsply 1;
BA_ "U_P552_MY18_5_Gas_Tx" SG_ 1095 VehLck_D_Dsply 1;
BA_ "U_V36X_MY18_5_Diesel_Tx" SG_ 1095 VehLck_D_Dsply 1;
BA_ "U_V408_MY18_Diesel_Tx" SG_ 1095 VehLck_D_Dsply 1;
BA_ "U_V408_MY18_Gas_Tx" SG_ 1095 VehLck_D_Dsply 1;
BA_ "U_S550_MY18_Gas_Tx" SG_ 1095 VehLck_D_Dsply 1;
BA_ "U_CD4_MY18_Phev_Tx" SG_ 1095 VehLck_D_Dsply 1;
BA_ "U_CD4_MY18_Hev_Tx" SG_ 1095 VehLck_D_Dsply 1;
BA_ "U_CD4_MY18_Gas_Tx" SG_ 1095 VehLck_D_Dsply 1;
BA_ "U_CD4_MY18_Diesel_Tx" SG_ 1095 VehLck_D_Dsply 1;
BA_ "U_U55x_MY18_Gas_Tx" SG_ 1095 VehLck_D_Dsply 1;
BA_ "U_CD43_MY17_Gas_Tx" SG_ 1095 VehLck_D_Dsply 1;
BA_ "U_P558_MY17_Diesel_Tx" SG_ 1095 VehLck_D_Dsply 1;
BA_ "U_P558_MY17_Gas_Tx" SG_ 1095 VehLck_D_Dsply 1;
BA_ "GenSigSendType" SG_ 1095 VehLck_D_Dsply 3;
BA_ "U_V36X_MY18_5_Hev_Tx" SG_ 1095 HeadLghtOn_D_Rq 1;
BA_ "U_V36X_MY18_5_Gas_Tx" SG_ 1095 HeadLghtOn_D_Rq 1;
BA_ "U_V363E_N_MY19_5_20_Diesel_Tx" SG_ 1095 HeadLghtOn_D_Rq 1;
BA_ "U_V363E_N_MY19_5_20_Gas_Tx" SG_ 1095 HeadLghtOn_D_Rq 1;
BA_ "U_V36X_MY19_5_Diesel_Tx" SG_ 1095 HeadLghtOn_D_Rq 1;
BA_ "U_P552_MY18_5_Diesel_Tx" SG_ 1095 HeadLghtOn_D_Rq 1;
BA_ "U_P552_MY18_5_Gas_Tx" SG_ 1095 HeadLghtOn_D_Rq 1;
BA_ "U_V36X_MY18_5_Diesel_Tx" SG_ 1095 HeadLghtOn_D_Rq 1;
BA_ "U_V408_MY18_Diesel_Tx" SG_ 1095 HeadLghtOn_D_Rq 1;
BA_ "U_V408_MY18_Gas_Tx" SG_ 1095 HeadLghtOn_D_Rq 1;
BA_ "U_S550_MY18_Gas_Tx" SG_ 1095 HeadLghtOn_D_Rq 1;
BA_ "U_CD4_MY18_Phev_Tx" SG_ 1095 HeadLghtOn_D_Rq 1;
BA_ "U_CD4_MY18_Hev_Tx" SG_ 1095 HeadLghtOn_D_Rq 1;
BA_ "U_CD4_MY18_Gas_Tx" SG_ 1095 HeadLghtOn_D_Rq 1;
BA_ "U_CD4_MY18_Diesel_Tx" SG_ 1095 HeadLghtOn_D_Rq 1;
BA_ "U_U502_MY17_Gas_Tx" SG_ 1095 HeadLghtOn_D_Rq 1;
BA_ "U_U55x_MY18_Gas_Tx" SG_ 1095 HeadLghtOn_D_Rq 1;
BA_ "U_P552_MY18_Gas_Tx" SG_ 1095 HeadLghtOn_D_Rq 1;
BA_ "U_P552_MY17_Gas_Tx" SG_ 1095 HeadLghtOn_D_Rq 1;
BA_ "U_CD43_MY17_Gas_Tx" SG_ 1095 HeadLghtOn_D_Rq 1;
BA_ "U_P558_MY17_Diesel_Tx" SG_ 1095 HeadLghtOn_D_Rq 1;
BA_ "U_P558_MY17_Gas_Tx" SG_ 1095 HeadLghtOn_D_Rq 1;
BA_ "GenSigStartValue" SG_ 1095 HeadLghtOn_D_Rq 1;
BA_ "WakeupSignal" SG_ 1095 HeadLghtOn_D_Rq 1;
BA_ "GenSigSendType" SG_ 1095 HeadLghtOn_D_Rq 3;
BA_ "GenSigSendType" SG_ 1095 RstrtSetting_T_Actl 3;
BA_ "U_CD4_MY13_Phev_Rx" SG_ 1095 RstrtSetting_T_Actl 1;
BA_ "U_CD4_MY13_Diesel_Tx" SG_ 1095 RstrtSetting_T_Actl 1;
BA_ "U_CD4_MY13_Gas_Tx" SG_ 1095 RstrtSetting_T_Actl 1;
BA_ "U_CD4_MY13_Hev_Tx" SG_ 1095 RstrtSetting_T_Actl 1;
BA_ "U_CD4_MY13_Phev_Tx" SG_ 1095 RstrtSetting_T_Actl 1;
BA_ "U_CD42_MY14_Diesel_Tx" SG_ 1095 RstrtSetting_T_Actl 1;
BA_ "U_CD42_MY14_Gas_Tx" SG_ 1095 RstrtSetting_T_Actl 1;
BA_ "U_P552_MY15_Gas_Tx" SG_ 1095 RstrtSetting_T_Actl 1;
BA_ "U_S550_MY15_Gas_Tx" SG_ 1095 RstrtSetting_T_Actl 1;
BA_ "U_C489_MY14_Gas_Tx" SG_ 1095 RstrtSetting_T_Actl 1;
BA_ "U_U502_MY15_Gas_Tx" SG_ 1095 RstrtSetting_T_Actl 1;
BA_ "U_UP375_MY15_Gas_Tx" SG_ 1095 RstrtSetting_T_Actl 1;
BA_ "U_UP375_MY15_Diesel_Tx" SG_ 1095 RstrtSetting_T_Actl 1;
BA_ "U_CD43_MY16_Gas_Tx" SG_ 1095 RstrtSetting_T_Actl 1;
BA_ "U_CD4_MY14_Diesel_Tx" SG_ 1095 RstrtSetting_T_Actl 1;
BA_ "U_CD4_MY14_Gas_Tx" SG_ 1095 RstrtSetting_T_Actl 1;
BA_ "U_CD4_MY14_Hev_Tx" SG_ 1095 RstrtSetting_T_Actl 1;
BA_ "U_CD4_MY14_Phev_Tx" SG_ 1095 RstrtSetting_T_Actl 1;
BA_ "GenSigSendType" SG_ 1095 PepsKeyActv_D_Stat 3;
BA_ "U_CD4_MY13_Diesel_Tx" SG_ 1095 PepsKeyActv_D_Stat 1;
BA_ "U_CD4_MY13_Gas_Tx" SG_ 1095 PepsKeyActv_D_Stat 1;
BA_ "U_CD4_MY13_Hev_Tx" SG_ 1095 PepsKeyActv_D_Stat 1;
BA_ "U_CD4_MY13_Phev_Tx" SG_ 1095 PepsKeyActv_D_Stat 1;
BA_ "U_CD42_MY14_Diesel_Tx" SG_ 1095 PepsKeyActv_D_Stat 1;
BA_ "U_CD42_MY14_Gas_Tx" SG_ 1095 PepsKeyActv_D_Stat 1;
BA_ "U_P552_MY15_Gas_Tx" SG_ 1095 PepsKeyActv_D_Stat 1;
BA_ "U_S550_MY15_Gas_Tx" SG_ 1095 PepsKeyActv_D_Stat 1;
BA_ "U_C489_MY14_Gas_Tx" SG_ 1095 PepsKeyActv_D_Stat 1;
BA_ "U_U502_MY15_Gas_Tx" SG_ 1095 PepsKeyActv_D_Stat 1;
BA_ "U_UP375_MY15_Gas_Tx" SG_ 1095 PepsKeyActv_D_Stat 1;
BA_ "U_UP375_MY15_Diesel_Tx" SG_ 1095 PepsKeyActv_D_Stat 1;
BA_ "U_CD43_MY16_Gas_Tx" SG_ 1095 PepsKeyActv_D_Stat 1;
BA_ "U_CD4_MY14_Diesel_Tx" SG_ 1095 PepsKeyActv_D_Stat 1;
BA_ "U_CD4_MY14_Gas_Tx" SG_ 1095 PepsKeyActv_D_Stat 1;
BA_ "U_CD4_MY14_Hev_Tx" SG_ 1095 PepsKeyActv_D_Stat 1;
BA_ "U_CD4_MY14_Phev_Tx" SG_ 1095 PepsKeyActv_D_Stat 1;
BA_ "GenSigSendType" SG_ 1095 Rstrt_T_Actl 3;
BA_ "U_CD4_MY13_Phev_Rx" SG_ 1095 Rstrt_T_Actl 1;
BA_ "U_CD4_MY13_Diesel_Tx" SG_ 1095 Rstrt_T_Actl 1;
BA_ "U_CD4_MY13_Gas_Tx" SG_ 1095 Rstrt_T_Actl 1;
BA_ "U_CD4_MY13_Hev_Tx" SG_ 1095 Rstrt_T_Actl 1;
BA_ "U_CD4_MY13_Phev_Tx" SG_ 1095 Rstrt_T_Actl 1;
BA_ "U_CD42_MY14_Diesel_Tx" SG_ 1095 Rstrt_T_Actl 1;
BA_ "U_CD42_MY14_Gas_Tx" SG_ 1095 Rstrt_T_Actl 1;
BA_ "U_P552_MY15_Gas_Tx" SG_ 1095 Rstrt_T_Actl 1;
BA_ "U_S550_MY15_Gas_Tx" SG_ 1095 Rstrt_T_Actl 1;
BA_ "U_C489_MY14_Gas_Tx" SG_ 1095 Rstrt_T_Actl 1;
BA_ "U_U502_MY15_Gas_Tx" SG_ 1095 Rstrt_T_Actl 1;
BA_ "U_UP375_MY15_Gas_Tx" SG_ 1095 Rstrt_T_Actl 1;
BA_ "U_UP375_MY15_Diesel_Tx" SG_ 1095 Rstrt_T_Actl 1;
BA_ "U_CD43_MY16_Gas_Tx" SG_ 1095 Rstrt_T_Actl 1;
BA_ "U_CD4_MY14_Diesel_Tx" SG_ 1095 Rstrt_T_Actl 1;
BA_ "U_CD4_MY14_Gas_Tx" SG_ 1095 Rstrt_T_Actl 1;
BA_ "U_CD4_MY14_Hev_Tx" SG_ 1095 Rstrt_T_Actl 1;
BA_ "U_CD4_MY14_Phev_Tx" SG_ 1095 Rstrt_T_Actl 1;
BA_ "GenSigSendType" SG_ 1095 PepsKeyFound_No_Actl 3;
BA_ "U_CD4_MY13_Phev_Rx" SG_ 1095 PepsKeyFound_No_Actl 1;
BA_ "U_CD4_MY13_Diesel_Tx" SG_ 1095 PepsKeyFound_No_Actl 1;
BA_ "U_CD4_MY13_Gas_Tx" SG_ 1095 PepsKeyFound_No_Actl 1;
BA_ "U_CD4_MY13_Hev_Tx" SG_ 1095 PepsKeyFound_No_Actl 1;
BA_ "U_CD4_MY13_Phev_Tx" SG_ 1095 PepsKeyFound_No_Actl 1;
BA_ "U_CD42_MY14_Diesel_Tx" SG_ 1095 PepsKeyFound_No_Actl 1;
BA_ "U_CD42_MY14_Gas_Tx" SG_ 1095 PepsKeyFound_No_Actl 1;
BA_ "U_P552_MY15_Gas_Tx" SG_ 1095 PepsKeyFound_No_Actl 1;
BA_ "U_S550_MY15_Gas_Tx" SG_ 1095 PepsKeyFound_No_Actl 1;
BA_ "U_C489_MY14_Gas_Tx" SG_ 1095 PepsKeyFound_No_Actl 1;
BA_ "U_U502_MY15_Gas_Tx" SG_ 1095 PepsKeyFound_No_Actl 1;
BA_ "U_UP375_MY15_Gas_Tx" SG_ 1095 PepsKeyFound_No_Actl 1;
BA_ "U_UP375_MY15_Diesel_Tx" SG_ 1095 PepsKeyFound_No_Actl 1;
BA_ "U_CD43_MY16_Gas_Tx" SG_ 1095 PepsKeyFound_No_Actl 1;
BA_ "U_CD4_MY14_Diesel_Tx" SG_ 1095 PepsKeyFound_No_Actl 1;
BA_ "U_CD4_MY14_Gas_Tx" SG_ 1095 PepsKeyFound_No_Actl 1;
BA_ "U_CD4_MY14_Hev_Tx" SG_ 1095 PepsKeyFound_No_Actl 1;
BA_ "U_CD4_MY14_Phev_Tx" SG_ 1095 PepsKeyFound_No_Actl 1;
BA_ "GenSigSendType" SG_ 1095 KeyProg_No_Actl 3;
BA_ "U_CD4_MY13_Phev_Rx" SG_ 1095 KeyProg_No_Actl 1;
BA_ "U_CD4_MY13_Diesel_Tx" SG_ 1095 KeyProg_No_Actl 1;
BA_ "U_CD4_MY13_Gas_Tx" SG_ 1095 KeyProg_No_Actl 1;
BA_ "U_CD4_MY13_Hev_Tx" SG_ 1095 KeyProg_No_Actl 1;
BA_ "U_CD4_MY13_Phev_Tx" SG_ 1095 KeyProg_No_Actl 1;
BA_ "U_CD42_MY14_Diesel_Tx" SG_ 1095 KeyProg_No_Actl 1;
BA_ "U_CD42_MY14_Gas_Tx" SG_ 1095 KeyProg_No_Actl 1;
BA_ "U_P552_MY15_Gas_Tx" SG_ 1095 KeyProg_No_Actl 1;
BA_ "U_S550_MY15_Gas_Tx" SG_ 1095 KeyProg_No_Actl 1;
BA_ "U_C489_MY14_Gas_Tx" SG_ 1095 KeyProg_No_Actl 1;
BA_ "U_U502_MY15_Gas_Tx" SG_ 1095 KeyProg_No_Actl 1;
BA_ "U_UP375_MY15_Gas_Tx" SG_ 1095 KeyProg_No_Actl 1;
BA_ "U_UP375_MY15_Diesel_Tx" SG_ 1095 KeyProg_No_Actl 1;
BA_ "U_CD43_MY16_Gas_Tx" SG_ 1095 KeyProg_No_Actl 1;
BA_ "U_CD4_MY14_Diesel_Tx" SG_ 1095 KeyProg_No_Actl 1;
BA_ "U_CD4_MY14_Gas_Tx" SG_ 1095 KeyProg_No_Actl 1;
BA_ "U_CD4_MY14_Hev_Tx" SG_ 1095 KeyProg_No_Actl 1;
BA_ "U_CD4_MY14_Phev_Tx" SG_ 1095 KeyProg_No_Actl 1;
BA_ "WakeupSignal" SG_ 1094 RollCodeCell_No_Actl 1;
BA_ "U_CD4_MY13_Diesel_Rx" SG_ 1094 RollCodeCell_No_Actl 1;
BA_ "U_CD4_MY13_Gas_Rx" SG_ 1094 RollCodeCell_No_Actl 1;
BA_ "U_CD4_MY13_Hev_Rx" SG_ 1094 RollCodeCell_No_Actl 1;
BA_ "U_CD4_MY13_Phev_Rx" SG_ 1094 RollCodeCell_No_Actl 1;
BA_ "U_CD42_MY14_Diesel_Rx" SG_ 1094 RollCodeCell_No_Actl 1;
BA_ "U_CD42_MY14_Gas_Rx" SG_ 1094 RollCodeCell_No_Actl 1;
BA_ "U_P552_MY15_Gas_Rx" SG_ 1094 RollCodeCell_No_Actl 1;
BA_ "U_S550_MY15_Gas_Rx" SG_ 1094 RollCodeCell_No_Actl 1;
BA_ "U_C489_MY14_Gas_Rx" SG_ 1094 RollCodeCell_No_Actl 1;
BA_ "U_U502_MY15_Gas_Rx" SG_ 1094 RollCodeCell_No_Actl 1;
BA_ "U_UP375_MY15_Gas_Rx" SG_ 1094 RollCodeCell_No_Actl 1;
BA_ "U_UP375_MY15_Diesel_Rx" SG_ 1094 RollCodeCell_No_Actl 1;
BA_ "U_CD43_MY16_Gas_Rx" SG_ 1094 RollCodeCell_No_Actl 1;
BA_ "U_CD4_MY14_Diesel_Rx" SG_ 1094 RollCodeCell_No_Actl 1;
BA_ "U_CD4_MY14_Gas_Rx" SG_ 1094 RollCodeCell_No_Actl 1;
BA_ "U_CD4_MY14_Hev_Rx" SG_ 1094 RollCodeCell_No_Actl 1;
BA_ "U_CD4_MY14_Phev_Rx" SG_ 1094 RollCodeCell_No_Actl 1;
BA_ "U_CD4_MY13_Phev_Tx" SG_ 1094 RollCodeCell_No_Actl 1;
BA_ "WakeupSignal" SG_ 1094 CellRstrtRq_No_Actl 1;
BA_ "U_CD4_MY13_Diesel_Rx" SG_ 1094 CellRstrtRq_No_Actl 1;
BA_ "U_CD4_MY13_Gas_Rx" SG_ 1094 CellRstrtRq_No_Actl 1;
BA_ "U_CD4_MY13_Hev_Rx" SG_ 1094 CellRstrtRq_No_Actl 1;
BA_ "U_CD4_MY13_Phev_Rx" SG_ 1094 CellRstrtRq_No_Actl 1;
BA_ "U_CD42_MY14_Diesel_Rx" SG_ 1094 CellRstrtRq_No_Actl 1;
BA_ "U_CD42_MY14_Gas_Rx" SG_ 1094 CellRstrtRq_No_Actl 1;
BA_ "U_P552_MY15_Gas_Rx" SG_ 1094 CellRstrtRq_No_Actl 1;
BA_ "U_S550_MY15_Gas_Rx" SG_ 1094 CellRstrtRq_No_Actl 1;
BA_ "U_C489_MY14_Gas_Rx" SG_ 1094 CellRstrtRq_No_Actl 1;
BA_ "U_U502_MY15_Gas_Rx" SG_ 1094 CellRstrtRq_No_Actl 1;
BA_ "U_UP375_MY15_Gas_Rx" SG_ 1094 CellRstrtRq_No_Actl 1;
BA_ "U_UP375_MY15_Diesel_Rx" SG_ 1094 CellRstrtRq_No_Actl 1;
BA_ "U_CD43_MY16_Gas_Rx" SG_ 1094 CellRstrtRq_No_Actl 1;
BA_ "U_CD4_MY14_Diesel_Rx" SG_ 1094 CellRstrtRq_No_Actl 1;
BA_ "U_CD4_MY14_Gas_Rx" SG_ 1094 CellRstrtRq_No_Actl 1;
BA_ "U_CD4_MY14_Hev_Rx" SG_ 1094 CellRstrtRq_No_Actl 1;
BA_ "U_CD4_MY14_Phev_Rx" SG_ 1094 CellRstrtRq_No_Actl 1;
BA_ "U_CD4_MY13_Phev_Tx" SG_ 1094 CellRstrtRq_No_Actl 1;
BA_ "WakeupSignal" SG_ 1094 CellRstrt_D_Rq 1;
BA_ "U_CD4_MY13_Diesel_Rx" SG_ 1094 CellRstrt_D_Rq 1;
BA_ "U_CD4_MY13_Gas_Rx" SG_ 1094 CellRstrt_D_Rq 1;
BA_ "U_CD4_MY13_Hev_Rx" SG_ 1094 CellRstrt_D_Rq 1;
BA_ "U_CD4_MY13_Phev_Rx" SG_ 1094 CellRstrt_D_Rq 1;
BA_ "U_CD42_MY14_Diesel_Rx" SG_ 1094 CellRstrt_D_Rq 1;
BA_ "U_CD42_MY14_Gas_Rx" SG_ 1094 CellRstrt_D_Rq 1;
BA_ "U_P552_MY15_Gas_Rx" SG_ 1094 CellRstrt_D_Rq 1;
BA_ "U_S550_MY15_Gas_Rx" SG_ 1094 CellRstrt_D_Rq 1;
BA_ "U_C489_MY14_Gas_Rx" SG_ 1094 CellRstrt_D_Rq 1;
BA_ "U_U502_MY15_Gas_Rx" SG_ 1094 CellRstrt_D_Rq 1;
BA_ "U_UP375_MY15_Gas_Rx" SG_ 1094 CellRstrt_D_Rq 1;
BA_ "U_UP375_MY15_Diesel_Rx" SG_ 1094 CellRstrt_D_Rq 1;
BA_ "U_CD43_MY16_Gas_Rx" SG_ 1094 CellRstrt_D_Rq 1;
BA_ "U_CD4_MY14_Diesel_Rx" SG_ 1094 CellRstrt_D_Rq 1;
BA_ "U_CD4_MY14_Gas_Rx" SG_ 1094 CellRstrt_D_Rq 1;
BA_ "U_CD4_MY14_Hev_Rx" SG_ 1094 CellRstrt_D_Rq 1;
BA_ "U_CD4_MY14_Phev_Rx" SG_ 1094 CellRstrt_D_Rq 1;
BA_ "U_CD4_MY13_Phev_Tx" SG_ 1094 CellRstrt_D_Rq 1;
BA_ "WakeupSignal" SG_ 1094 CellPanicRq_No_Actl 1;
BA_ "U_CD4_MY13_Diesel_Rx" SG_ 1094 CellPanicRq_No_Actl 1;
BA_ "U_CD4_MY13_Gas_Rx" SG_ 1094 CellPanicRq_No_Actl 1;
BA_ "U_CD4_MY13_Hev_Rx" SG_ 1094 CellPanicRq_No_Actl 1;
BA_ "U_CD4_MY13_Phev_Rx" SG_ 1094 CellPanicRq_No_Actl 1;
BA_ "U_CD42_MY14_Diesel_Rx" SG_ 1094 CellPanicRq_No_Actl 1;
BA_ "U_CD42_MY14_Gas_Rx" SG_ 1094 CellPanicRq_No_Actl 1;
BA_ "U_P552_MY15_Gas_Rx" SG_ 1094 CellPanicRq_No_Actl 1;
BA_ "U_S550_MY15_Gas_Rx" SG_ 1094 CellPanicRq_No_Actl 1;
BA_ "U_C489_MY14_Gas_Rx" SG_ 1094 CellPanicRq_No_Actl 1;
BA_ "U_U502_MY15_Gas_Rx" SG_ 1094 CellPanicRq_No_Actl 1;
BA_ "U_UP375_MY15_Gas_Rx" SG_ 1094 CellPanicRq_No_Actl 1;
BA_ "U_UP375_MY15_Diesel_Rx" SG_ 1094 CellPanicRq_No_Actl 1;
BA_ "U_CD43_MY16_Gas_Rx" SG_ 1094 CellPanicRq_No_Actl 1;
BA_ "U_CD4_MY14_Diesel_Rx" SG_ 1094 CellPanicRq_No_Actl 1;
BA_ "U_CD4_MY14_Gas_Rx" SG_ 1094 CellPanicRq_No_Actl 1;
BA_ "U_CD4_MY14_Hev_Rx" SG_ 1094 CellPanicRq_No_Actl 1;
BA_ "U_CD4_MY14_Phev_Rx" SG_ 1094 CellPanicRq_No_Actl 1;
BA_ "U_CD4_MY13_Phev_Tx" SG_ 1094 CellPanicRq_No_Actl 1;
BA_ "WakeupSignal" SG_ 1094 CellPanic_D_Rq 1;
BA_ "U_CD4_MY13_Diesel_Rx" SG_ 1094 CellPanic_D_Rq 1;
BA_ "U_CD4_MY13_Gas_Rx" SG_ 1094 CellPanic_D_Rq 1;
BA_ "U_CD4_MY13_Hev_Rx" SG_ 1094 CellPanic_D_Rq 1;
BA_ "U_CD4_MY13_Phev_Rx" SG_ 1094 CellPanic_D_Rq 1;
BA_ "U_CD42_MY14_Diesel_Rx" SG_ 1094 CellPanic_D_Rq 1;
BA_ "U_CD42_MY14_Gas_Rx" SG_ 1094 CellPanic_D_Rq 1;
BA_ "U_P552_MY15_Gas_Rx" SG_ 1094 CellPanic_D_Rq 1;
BA_ "U_S550_MY15_Gas_Rx" SG_ 1094 CellPanic_D_Rq 1;
BA_ "U_C489_MY14_Gas_Rx" SG_ 1094 CellPanic_D_Rq 1;
BA_ "U_U502_MY15_Gas_Rx" SG_ 1094 CellPanic_D_Rq 1;
BA_ "U_UP375_MY15_Gas_Rx" SG_ 1094 CellPanic_D_Rq 1;
BA_ "U_UP375_MY15_Diesel_Rx" SG_ 1094 CellPanic_D_Rq 1;
BA_ "U_CD43_MY16_Gas_Rx" SG_ 1094 CellPanic_D_Rq 1;
BA_ "U_CD4_MY14_Diesel_Rx" SG_ 1094 CellPanic_D_Rq 1;
BA_ "U_CD4_MY14_Gas_Rx" SG_ 1094 CellPanic_D_Rq 1;
BA_ "U_CD4_MY14_Hev_Rx" SG_ 1094 CellPanic_D_Rq 1;
BA_ "U_CD4_MY14_Phev_Rx" SG_ 1094 CellPanic_D_Rq 1;
BA_ "U_CD4_MY13_Phev_Tx" SG_ 1094 CellPanic_D_Rq 1;
BA_ "WakeupSignal" SG_ 1094 CellLockRq_No_Actl 1;
BA_ "U_CD4_MY13_Diesel_Rx" SG_ 1094 CellLockRq_No_Actl 1;
BA_ "U_CD4_MY13_Gas_Rx" SG_ 1094 CellLockRq_No_Actl 1;
BA_ "U_CD4_MY13_Hev_Rx" SG_ 1094 CellLockRq_No_Actl 1;
BA_ "U_CD4_MY13_Phev_Rx" SG_ 1094 CellLockRq_No_Actl 1;
BA_ "U_CD42_MY14_Diesel_Rx" SG_ 1094 CellLockRq_No_Actl 1;
BA_ "U_CD42_MY14_Gas_Rx" SG_ 1094 CellLockRq_No_Actl 1;
BA_ "U_P552_MY15_Gas_Rx" SG_ 1094 CellLockRq_No_Actl 1;
BA_ "U_S550_MY15_Gas_Rx" SG_ 1094 CellLockRq_No_Actl 1;
BA_ "U_C489_MY14_Gas_Rx" SG_ 1094 CellLockRq_No_Actl 1;
BA_ "U_U502_MY15_Gas_Rx" SG_ 1094 CellLockRq_No_Actl 1;
BA_ "U_UP375_MY15_Gas_Rx" SG_ 1094 CellLockRq_No_Actl 1;
BA_ "U_UP375_MY15_Diesel_Rx" SG_ 1094 CellLockRq_No_Actl 1;
BA_ "U_CD43_MY16_Gas_Rx" SG_ 1094 CellLockRq_No_Actl 1;
BA_ "U_CD4_MY14_Diesel_Rx" SG_ 1094 CellLockRq_No_Actl 1;
BA_ "U_CD4_MY14_Gas_Rx" SG_ 1094 CellLockRq_No_Actl 1;
BA_ "U_CD4_MY14_Hev_Rx" SG_ 1094 CellLockRq_No_Actl 1;
BA_ "U_CD4_MY14_Phev_Rx" SG_ 1094 CellLockRq_No_Actl 1;
BA_ "U_CD4_MY13_Phev_Tx" SG_ 1094 CellLockRq_No_Actl 1;
BA_ "WakeupSignal" SG_ 1094 CellLock_D_Rq 1;
BA_ "U_CD4_MY13_Diesel_Rx" SG_ 1094 CellLock_D_Rq 1;
BA_ "U_CD4_MY13_Gas_Rx" SG_ 1094 CellLock_D_Rq 1;
BA_ "U_CD4_MY13_Hev_Rx" SG_ 1094 CellLock_D_Rq 1;
BA_ "U_CD4_MY13_Phev_Rx" SG_ 1094 CellLock_D_Rq 1;
BA_ "U_CD42_MY14_Diesel_Rx" SG_ 1094 CellLock_D_Rq 1;
BA_ "U_CD42_MY14_Gas_Rx" SG_ 1094 CellLock_D_Rq 1;
BA_ "U_P552_MY15_Gas_Rx" SG_ 1094 CellLock_D_Rq 1;
BA_ "U_S550_MY15_Gas_Rx" SG_ 1094 CellLock_D_Rq 1;
BA_ "U_C489_MY14_Gas_Rx" SG_ 1094 CellLock_D_Rq 1;
BA_ "U_U502_MY15_Gas_Rx" SG_ 1094 CellLock_D_Rq 1;
BA_ "U_UP375_MY15_Gas_Rx" SG_ 1094 CellLock_D_Rq 1;
BA_ "U_UP375_MY15_Diesel_Rx" SG_ 1094 CellLock_D_Rq 1;
BA_ "U_CD43_MY16_Gas_Rx" SG_ 1094 CellLock_D_Rq 1;
BA_ "U_CD4_MY14_Diesel_Rx" SG_ 1094 CellLock_D_Rq 1;
BA_ "U_CD4_MY14_Gas_Rx" SG_ 1094 CellLock_D_Rq 1;
BA_ "U_CD4_MY14_Hev_Rx" SG_ 1094 CellLock_D_Rq 1;
BA_ "U_CD4_MY14_Phev_Rx" SG_ 1094 CellLock_D_Rq 1;
BA_ "U_CD4_MY13_Phev_Tx" SG_ 1094 CellLock_D_Rq 1;
BA_ "WakeupSignal" SG_ 1094 CellChirpRq_No_Actl 1;
BA_ "U_CD4_MY13_Diesel_Rx" SG_ 1094 CellChirpRq_No_Actl 1;
BA_ "U_CD4_MY13_Gas_Rx" SG_ 1094 CellChirpRq_No_Actl 1;
BA_ "U_CD4_MY13_Hev_Rx" SG_ 1094 CellChirpRq_No_Actl 1;
BA_ "U_CD4_MY13_Phev_Rx" SG_ 1094 CellChirpRq_No_Actl 1;
BA_ "U_CD42_MY14_Diesel_Rx" SG_ 1094 CellChirpRq_No_Actl 1;
BA_ "U_CD42_MY14_Gas_Rx" SG_ 1094 CellChirpRq_No_Actl 1;
BA_ "U_P552_MY15_Gas_Rx" SG_ 1094 CellChirpRq_No_Actl 1;
BA_ "U_S550_MY15_Gas_Rx" SG_ 1094 CellChirpRq_No_Actl 1;
BA_ "U_C489_MY14_Gas_Rx" SG_ 1094 CellChirpRq_No_Actl 1;
BA_ "U_U502_MY15_Gas_Rx" SG_ 1094 CellChirpRq_No_Actl 1;
BA_ "U_UP375_MY15_Gas_Rx" SG_ 1094 CellChirpRq_No_Actl 1;
BA_ "U_UP375_MY15_Diesel_Rx" SG_ 1094 CellChirpRq_No_Actl 1;
BA_ "U_CD43_MY16_Gas_Rx" SG_ 1094 CellChirpRq_No_Actl 1;
BA_ "U_CD4_MY14_Diesel_Rx" SG_ 1094 CellChirpRq_No_Actl 1;
BA_ "U_CD4_MY14_Gas_Rx" SG_ 1094 CellChirpRq_No_Actl 1;
BA_ "U_CD4_MY14_Hev_Rx" SG_ 1094 CellChirpRq_No_Actl 1;
BA_ "U_CD4_MY14_Phev_Rx" SG_ 1094 CellChirpRq_No_Actl 1;
BA_ "U_CD4_MY13_Phev_Tx" SG_ 1094 CellChirpRq_No_Actl 1;
BA_ "WakeupSignal" SG_ 1094 CellChirp_D_Rq 1;
BA_ "U_CD4_MY13_Diesel_Rx" SG_ 1094 CellChirp_D_Rq 1;
BA_ "U_CD4_MY13_Gas_Rx" SG_ 1094 CellChirp_D_Rq 1;
BA_ "U_CD4_MY13_Hev_Rx" SG_ 1094 CellChirp_D_Rq 1;
BA_ "U_CD4_MY13_Phev_Rx" SG_ 1094 CellChirp_D_Rq 1;
BA_ "U_CD42_MY14_Diesel_Rx" SG_ 1094 CellChirp_D_Rq 1;
BA_ "U_CD42_MY14_Gas_Rx" SG_ 1094 CellChirp_D_Rq 1;
BA_ "U_P552_MY15_Gas_Rx" SG_ 1094 CellChirp_D_Rq 1;
BA_ "U_S550_MY15_Gas_Rx" SG_ 1094 CellChirp_D_Rq 1;
BA_ "U_C489_MY14_Gas_Rx" SG_ 1094 CellChirp_D_Rq 1;
BA_ "U_U502_MY15_Gas_Rx" SG_ 1094 CellChirp_D_Rq 1;
BA_ "U_UP375_MY15_Gas_Rx" SG_ 1094 CellChirp_D_Rq 1;
BA_ "U_UP375_MY15_Diesel_Rx" SG_ 1094 CellChirp_D_Rq 1;
BA_ "U_CD43_MY16_Gas_Rx" SG_ 1094 CellChirp_D_Rq 1;
BA_ "U_CD4_MY14_Diesel_Rx" SG_ 1094 CellChirp_D_Rq 1;
BA_ "U_CD4_MY14_Gas_Rx" SG_ 1094 CellChirp_D_Rq 1;
BA_ "U_CD4_MY14_Hev_Rx" SG_ 1094 CellChirp_D_Rq 1;
BA_ "U_CD4_MY14_Phev_Rx" SG_ 1094 CellChirp_D_Rq 1;
BA_ "U_CD4_MY13_Phev_Tx" SG_ 1094 CellChirp_D_Rq 1;
BA_ "WakeupSignal" SG_ 320 PwSldDrIntSwL_B_Stat 1;
BA_ "ContentDependant" SG_ 320 PwSldDrIntSwL_B_Stat 1;
BA_ "U_CD4_MY13_Diesel_Rx" SG_ 320 PwSldDrIntSwL_B_Stat 1;
BA_ "U_CD4_MY13_Gas_Rx" SG_ 320 PwSldDrIntSwL_B_Stat 1;
BA_ "U_CD4_MY13_Hev_Rx" SG_ 320 PwSldDrIntSwL_B_Stat 1;
BA_ "U_CD4_MY13_Phev_Rx" SG_ 320 PwSldDrIntSwL_B_Stat 1;
BA_ "U_CD42_MY14_Diesel_Rx" SG_ 320 PwSldDrIntSwL_B_Stat 1;
BA_ "U_CD42_MY14_Gas_Rx" SG_ 320 PwSldDrIntSwL_B_Stat 1;
BA_ "U_P552_MY15_Gas_Rx" SG_ 320 PwSldDrIntSwL_B_Stat 1;
BA_ "U_S550_MY15_Gas_Rx" SG_ 320 PwSldDrIntSwL_B_Stat 1;
BA_ "U_C489_MY14_Gas_Rx" SG_ 320 PwSldDrIntSwL_B_Stat 1;
BA_ "U_U502_MY15_Gas_Rx" SG_ 320 PwSldDrIntSwL_B_Stat 1;
BA_ "U_UP375_MY15_Gas_Rx" SG_ 320 PwSldDrIntSwL_B_Stat 1;
BA_ "U_UP375_MY15_Diesel_Rx" SG_ 320 PwSldDrIntSwL_B_Stat 1;
BA_ "U_CD43_MY16_Gas_Rx" SG_ 320 PwSldDrIntSwL_B_Stat 1;
BA_ "U_CD4_MY14_Diesel_Rx" SG_ 320 PwSldDrIntSwL_B_Stat 1;
BA_ "U_CD4_MY14_Gas_Rx" SG_ 320 PwSldDrIntSwL_B_Stat 1;
BA_ "U_CD4_MY14_Hev_Rx" SG_ 320 PwSldDrIntSwL_B_Stat 1;
BA_ "U_CD4_MY14_Phev_Rx" SG_ 320 PwSldDrIntSwL_B_Stat 1;
BA_ "WakeupSignal" SG_ 320 LPwrSlideDr_Unlock_Rq 1;
BA_ "ContentDependant" SG_ 320 LPwrSlideDr_Unlock_Rq 1;
BA_ "U_CD4_MY13_Diesel_Rx" SG_ 320 LPwrSlideDr_Unlock_Rq 1;
BA_ "U_CD4_MY13_Gas_Rx" SG_ 320 LPwrSlideDr_Unlock_Rq 1;
BA_ "U_CD4_MY13_Hev_Rx" SG_ 320 LPwrSlideDr_Unlock_Rq 1;
BA_ "U_CD4_MY13_Phev_Rx" SG_ 320 LPwrSlideDr_Unlock_Rq 1;
BA_ "U_CD42_MY14_Diesel_Rx" SG_ 320 LPwrSlideDr_Unlock_Rq 1;
BA_ "U_CD42_MY14_Gas_Rx" SG_ 320 LPwrSlideDr_Unlock_Rq 1;
BA_ "U_P552_MY15_Gas_Rx" SG_ 320 LPwrSlideDr_Unlock_Rq 1;
BA_ "U_S550_MY15_Gas_Rx" SG_ 320 LPwrSlideDr_Unlock_Rq 1;
BA_ "U_C489_MY14_Gas_Rx" SG_ 320 LPwrSlideDr_Unlock_Rq 1;
BA_ "U_U502_MY15_Gas_Rx" SG_ 320 LPwrSlideDr_Unlock_Rq 1;
BA_ "U_UP375_MY15_Gas_Rx" SG_ 320 LPwrSlideDr_Unlock_Rq 1;
BA_ "U_UP375_MY15_Diesel_Rx" SG_ 320 LPwrSlideDr_Unlock_Rq 1;
BA_ "U_CD43_MY16_Gas_Rx" SG_ 320 LPwrSlideDr_Unlock_Rq 1;
BA_ "U_CD4_MY14_Diesel_Rx" SG_ 320 LPwrSlideDr_Unlock_Rq 1;
BA_ "U_CD4_MY14_Gas_Rx" SG_ 320 LPwrSlideDr_Unlock_Rq 1;
BA_ "U_CD4_MY14_Hev_Rx" SG_ 320 LPwrSlideDr_Unlock_Rq 1;
BA_ "U_CD4_MY14_Phev_Rx" SG_ 320 LPwrSlideDr_Unlock_Rq 1;
BA_ "WakeupSignal" SG_ 313 PwSldDrIntSwR_B_Stat 1;
BA_ "ContentDependant" SG_ 313 PwSldDrIntSwR_B_Stat 1;
BA_ "U_CD4_MY13_Diesel_Rx" SG_ 313 PwSldDrIntSwR_B_Stat 1;
BA_ "U_CD4_MY13_Gas_Rx" SG_ 313 PwSldDrIntSwR_B_Stat 1;
BA_ "U_CD4_MY13_Hev_Rx" SG_ 313 PwSldDrIntSwR_B_Stat 1;
BA_ "U_CD4_MY13_Phev_Rx" SG_ 313 PwSldDrIntSwR_B_Stat 1;
BA_ "U_CD42_MY14_Diesel_Rx" SG_ 313 PwSldDrIntSwR_B_Stat 1;
BA_ "U_CD42_MY14_Gas_Rx" SG_ 313 PwSldDrIntSwR_B_Stat 1;
BA_ "U_P552_MY15_Gas_Rx" SG_ 313 PwSldDrIntSwR_B_Stat 1;
BA_ "U_S550_MY15_Gas_Rx" SG_ 313 PwSldDrIntSwR_B_Stat 1;
BA_ "U_C489_MY14_Gas_Rx" SG_ 313 PwSldDrIntSwR_B_Stat 1;
BA_ "U_U502_MY15_Gas_Rx" SG_ 313 PwSldDrIntSwR_B_Stat 1;
BA_ "U_UP375_MY15_Gas_Rx" SG_ 313 PwSldDrIntSwR_B_Stat 1;
BA_ "U_UP375_MY15_Diesel_Rx" SG_ 313 PwSldDrIntSwR_B_Stat 1;
BA_ "U_CD43_MY16_Gas_Rx" SG_ 313 PwSldDrIntSwR_B_Stat 1;
BA_ "U_CD4_MY14_Diesel_Rx" SG_ 313 PwSldDrIntSwR_B_Stat 1;
BA_ "U_CD4_MY14_Gas_Rx" SG_ 313 PwSldDrIntSwR_B_Stat 1;
BA_ "U_CD4_MY14_Hev_Rx" SG_ 313 PwSldDrIntSwR_B_Stat 1;
BA_ "U_CD4_MY14_Phev_Rx" SG_ 313 PwSldDrIntSwR_B_Stat 1;
BA_ "WakeupSignal" SG_ 313 RPwrSlideDr_Unlock_Rq 1;
BA_ "ContentDependant" SG_ 313 RPwrSlideDr_Unlock_Rq 1;
BA_ "U_CD4_MY13_Diesel_Rx" SG_ 313 RPwrSlideDr_Unlock_Rq 1;
BA_ "U_CD4_MY13_Gas_Rx" SG_ 313 RPwrSlideDr_Unlock_Rq 1;
BA_ "U_CD4_MY13_Hev_Rx" SG_ 313 RPwrSlideDr_Unlock_Rq 1;
BA_ "U_CD4_MY13_Phev_Rx" SG_ 313 RPwrSlideDr_Unlock_Rq 1;
BA_ "U_CD42_MY14_Diesel_Rx" SG_ 313 RPwrSlideDr_Unlock_Rq 1;
BA_ "U_CD42_MY14_Gas_Rx" SG_ 313 RPwrSlideDr_Unlock_Rq 1;
BA_ "U_P552_MY15_Gas_Rx" SG_ 313 RPwrSlideDr_Unlock_Rq 1;
BA_ "U_S550_MY15_Gas_Rx" SG_ 313 RPwrSlideDr_Unlock_Rq 1;
BA_ "U_C489_MY14_Gas_Rx" SG_ 313 RPwrSlideDr_Unlock_Rq 1;
BA_ "U_U502_MY15_Gas_Rx" SG_ 313 RPwrSlideDr_Unlock_Rq 1;
BA_ "U_UP375_MY15_Gas_Rx" SG_ 313 RPwrSlideDr_Unlock_Rq 1;
BA_ "U_UP375_MY15_Diesel_Rx" SG_ 313 RPwrSlideDr_Unlock_Rq 1;
BA_ "U_CD43_MY16_Gas_Rx" SG_ 313 RPwrSlideDr_Unlock_Rq 1;
BA_ "U_CD4_MY14_Diesel_Rx" SG_ 313 RPwrSlideDr_Unlock_Rq 1;
BA_ "U_CD4_MY14_Gas_Rx" SG_ 313 RPwrSlideDr_Unlock_Rq 1;
BA_ "U_CD4_MY14_Hev_Rx" SG_ 313 RPwrSlideDr_Unlock_Rq 1;
BA_ "U_CD4_MY14_Phev_Rx" SG_ 313 RPwrSlideDr_Unlock_Rq 1;
BA_ "CrossOver_InfoCAN" SG_ 993 PersStore_D_Actl 1;
BA_ "WakeupSignal" SG_ 993 MemSwtch_D_RqRecall 1;
BA_ "CrossOver_InfoCAN" SG_ 993 MemSwtch_D_RqRecall 1;
BA_ "U_CD4_MY13_Diesel_Rx" SG_ 993 MemSwtch_D_RqRecall 1;
BA_ "U_CD4_MY13_Gas_Rx" SG_ 993 MemSwtch_D_RqRecall 1;
BA_ "U_CD4_MY13_Hev_Rx" SG_ 993 MemSwtch_D_RqRecall 1;
BA_ "U_CD4_MY13_Phev_Rx" SG_ 993 MemSwtch_D_RqRecall 1;
BA_ "U_CD42_MY14_Diesel_Rx" SG_ 993 MemSwtch_D_RqRecall 1;
BA_ "U_CD42_MY14_Gas_Rx" SG_ 993 MemSwtch_D_RqRecall 1;
BA_ "U_P552_MY15_Gas_Rx" SG_ 993 MemSwtch_D_RqRecall 1;
BA_ "U_S550_MY15_Gas_Rx" SG_ 993 MemSwtch_D_RqRecall 1;
BA_ "U_C489_MY14_Gas_Rx" SG_ 993 MemSwtch_D_RqRecall 1;
BA_ "U_U502_MY15_Gas_Rx" SG_ 993 MemSwtch_D_RqRecall 1;
BA_ "U_UP375_MY15_Gas_Rx" SG_ 993 MemSwtch_D_RqRecall 1;
BA_ "U_UP375_MY15_Diesel_Rx" SG_ 993 MemSwtch_D_RqRecall 1;
BA_ "U_CD43_MY16_Gas_Rx" SG_ 993 MemSwtch_D_RqRecall 1;
BA_ "U_CD4_MY14_Diesel_Rx" SG_ 993 MemSwtch_D_RqRecall 1;
BA_ "U_CD4_MY14_Gas_Rx" SG_ 993 MemSwtch_D_RqRecall 1;
BA_ "U_CD4_MY14_Hev_Rx" SG_ 993 MemSwtch_D_RqRecall 1;
BA_ "U_CD4_MY14_Phev_Rx" SG_ 993 MemSwtch_D_RqRecall 1;
BA_ "WakeupSignal" SG_ 993 MemSwtch_D_RqAssoc 1;
BA_ "CrossOver_InfoCAN" SG_ 993 MemSwtch_D_RqAssoc 1;
BA_ "U_CD4_MY13_Diesel_Rx" SG_ 993 MemSwtch_D_RqAssoc 1;
BA_ "U_CD4_MY13_Gas_Rx" SG_ 993 MemSwtch_D_RqAssoc 1;
BA_ "U_CD4_MY13_Hev_Rx" SG_ 993 MemSwtch_D_RqAssoc 1;
BA_ "U_CD4_MY13_Phev_Rx" SG_ 993 MemSwtch_D_RqAssoc 1;
BA_ "U_CD42_MY14_Diesel_Rx" SG_ 993 MemSwtch_D_RqAssoc 1;
BA_ "U_CD42_MY14_Gas_Rx" SG_ 993 MemSwtch_D_RqAssoc 1;
BA_ "U_P552_MY15_Gas_Rx" SG_ 993 MemSwtch_D_RqAssoc 1;
BA_ "U_S550_MY15_Gas_Rx" SG_ 993 MemSwtch_D_RqAssoc 1;
BA_ "U_C489_MY14_Gas_Rx" SG_ 993 MemSwtch_D_RqAssoc 1;
BA_ "U_U502_MY15_Gas_Rx" SG_ 993 MemSwtch_D_RqAssoc 1;
BA_ "U_UP375_MY15_Gas_Rx" SG_ 993 MemSwtch_D_RqAssoc 1;
BA_ "U_UP375_MY15_Diesel_Rx" SG_ 993 MemSwtch_D_RqAssoc 1;
BA_ "U_CD43_MY16_Gas_Rx" SG_ 993 MemSwtch_D_RqAssoc 1;
BA_ "U_CD4_MY14_Diesel_Rx" SG_ 993 MemSwtch_D_RqAssoc 1;
BA_ "U_CD4_MY14_Gas_Rx" SG_ 993 MemSwtch_D_RqAssoc 1;
BA_ "U_CD4_MY14_Hev_Rx" SG_ 993 MemSwtch_D_RqAssoc 1;
BA_ "U_CD4_MY14_Phev_Rx" SG_ 993 MemSwtch_D_RqAssoc 1;
BA_ "CrossOver_InfoCAN" SG_ 993 PersIndexDsm_D_Actl 1;
BA_ "GenSigStartValue" SG_ 993 PersIndexDsm_D_Actl 4;
BA_ "CrossOver_InfoCAN" SG_ 993 FeatNoDsmActl 1;
BA_ "CrossOver_InfoCAN" SG_ 993 FeatConfigDsmActl 1;
BA_ "GenSigStartValue" SG_ 131 WiprFrontSwtch_D_Stat 9;
BA_ "WakeupSignal" SG_ 131 HeadLghtHiCtrl_D_RqAhb 1;
BA_ "U_P558_MY17_Gas_Rx" SG_ 131 HeadLghtHiCtrl_D_RqAhb 1;
BA_ "U_P558_MY17_Diesel_Rx" SG_ 131 HeadLghtHiCtrl_D_RqAhb 1;
BA_ "U_CD43_MY17_Gas_Rx" SG_ 131 HeadLghtHiCtrl_D_RqAhb 1;
BA_ "U_U55x_MY18_Gas_Rx" SG_ 131 HeadLghtHiCtrl_D_RqAhb 1;
BA_ "U_U502_MY17_Gas_Rx" SG_ 131 HeadLghtHiCtrl_D_RqAhb 1;
BA_ "U_CD4_MY18_Diesel_Rx" SG_ 131 HeadLghtHiCtrl_D_RqAhb 1;
BA_ "U_CD4_MY18_Gas_Rx" SG_ 131 HeadLghtHiCtrl_D_RqAhb 1;
BA_ "U_CD4_MY18_Hev_Rx" SG_ 131 HeadLghtHiCtrl_D_RqAhb 1;
BA_ "U_CD4_MY18_Phev_Rx" SG_ 131 HeadLghtHiCtrl_D_RqAhb 1;
BA_ "U_S550_MY18_Gas_Rx" SG_ 131 HeadLghtHiCtrl_D_RqAhb 1;
BA_ "U_V408_MY18_Gas_Rx" SG_ 131 HeadLghtHiCtrl_D_RqAhb 1;
BA_ "U_V408_MY18_Diesel_Rx" SG_ 131 HeadLghtHiCtrl_D_RqAhb 1;
BA_ "U_V36X_MY18_5_Diesel_Rx" SG_ 131 HeadLghtHiCtrl_D_RqAhb 1;
BA_ "U_P552_MY18_5_Gas_Rx" SG_ 131 HeadLghtHiCtrl_D_RqAhb 1;
BA_ "U_P552_MY18_5_Diesel_Rx" SG_ 131 HeadLghtHiCtrl_D_RqAhb 1;
BA_ "U_V36X_MY19_5_Diesel_Rx" SG_ 131 HeadLghtHiCtrl_D_RqAhb 1;
BA_ "U_V363E_N_MY19_5_20_Gas_Rx" SG_ 131 HeadLghtHiCtrl_D_RqAhb 1;
BA_ "U_V363E_N_MY19_5_20_Diesel_Rx" SG_ 131 HeadLghtHiCtrl_D_RqAhb 1;
BA_ "U_V36X_MY18_5_Gas_Rx" SG_ 131 HeadLghtHiCtrl_D_RqAhb 1;
BA_ "U_V36X_MY18_5_Hev_Rx" SG_ 131 HeadLghtHiCtrl_D_RqAhb 1;
BA_ "WakeupSignal" SG_ 131 HeadLghtHiOn_B_StatAhb 1;
BA_ "U_CD4_MY13_Gas_Rx" SG_ 131 AslButtnOnOffCnclPress 1;
BA_ "U_CD42_MY14_Gas_Rx" SG_ 131 AslButtnOnOffCnclPress 1;
BA_ "U_P552_MY15_Gas_Rx" SG_ 131 AslButtnOnOffCnclPress 1;
BA_ "U_S550_MY15_Gas_Rx" SG_ 131 AslButtnOnOffCnclPress 1;
BA_ "U_C489_MY14_Gas_Rx" SG_ 131 AslButtnOnOffCnclPress 1;
BA_ "U_U502_MY15_Gas_Rx" SG_ 131 AslButtnOnOffCnclPress 1;
BA_ "U_CD43_MY16_Gas_Rx" SG_ 131 AslButtnOnOffCnclPress 1;
BA_ "U_CD4_MY14_Gas_Rx" SG_ 131 AslButtnOnOffCnclPress 1;
BA_ "U_CD4_MY13_Gas_Rx" SG_ 131 CcButtnOnPress 1;
BA_ "U_CD42_MY14_Gas_Rx" SG_ 131 CcButtnOnPress 1;
BA_ "U_P552_MY15_Gas_Rx" SG_ 131 CcButtnOnPress 1;
BA_ "U_S550_MY15_Gas_Rx" SG_ 131 CcButtnOnPress 1;
BA_ "U_C489_MY14_Gas_Rx" SG_ 131 CcButtnOnPress 1;
BA_ "U_U502_MY15_Gas_Rx" SG_ 131 CcButtnOnPress 1;
BA_ "U_UP375_MY15_Gas_Rx" SG_ 131 CcButtnOnPress 1;
BA_ "U_CD43_MY16_Gas_Rx" SG_ 131 CcButtnOnPress 1;
BA_ "U_CD4_MY14_Gas_Rx" SG_ 131 CcButtnOnPress 1;
BA_ "U_CD4_MY13_Gas_Rx" SG_ 131 CcButtnOnOffPress 1;
BA_ "U_CD42_MY14_Gas_Rx" SG_ 131 CcButtnOnOffPress 1;
BA_ "U_P552_MY15_Gas_Rx" SG_ 131 CcButtnOnOffPress 1;
BA_ "U_S550_MY15_Gas_Rx" SG_ 131 CcButtnOnOffPress 1;
BA_ "U_C489_MY14_Gas_Rx" SG_ 131 CcButtnOnOffPress 1;
BA_ "U_U502_MY15_Gas_Rx" SG_ 131 CcButtnOnOffPress 1;
BA_ "U_UP375_MY15_Gas_Rx" SG_ 131 CcButtnOnOffPress 1;
BA_ "U_CD43_MY16_Gas_Rx" SG_ 131 CcButtnOnOffPress 1;
BA_ "U_CD4_MY14_Gas_Rx" SG_ 131 CcButtnOnOffPress 1;
BA_ "U_CD4_MY13_Gas_Rx" SG_ 131 CcButtnOnOffCnclPress 1;
BA_ "U_CD42_MY14_Gas_Rx" SG_ 131 CcButtnOnOffCnclPress 1;
BA_ "U_P552_MY15_Gas_Rx" SG_ 131 CcButtnOnOffCnclPress 1;
BA_ "U_S550_MY15_Gas_Rx" SG_ 131 CcButtnOnOffCnclPress 1;
BA_ "U_C489_MY14_Gas_Rx" SG_ 131 CcButtnOnOffCnclPress 1;
BA_ "U_U502_MY15_Gas_Rx" SG_ 131 CcButtnOnOffCnclPress 1;
BA_ "U_UP375_MY15_Gas_Rx" SG_ 131 CcButtnOnOffCnclPress 1;
BA_ "U_CD43_MY16_Gas_Rx" SG_ 131 CcButtnOnOffCnclPress 1;
BA_ "U_CD4_MY14_Gas_Rx" SG_ 131 CcButtnOnOffCnclPress 1;
BA_ "U_CD4_MY13_Gas_Rx" SG_ 131 CcButtnOffPress 1;
BA_ "U_CD42_MY14_Gas_Rx" SG_ 131 CcButtnOffPress 1;
BA_ "U_P552_MY15_Gas_Rx" SG_ 131 CcButtnOffPress 1;
BA_ "U_S550_MY15_Gas_Rx" SG_ 131 CcButtnOffPress 1;
BA_ "U_C489_MY14_Gas_Rx" SG_ 131 CcButtnOffPress 1;
BA_ "U_U502_MY15_Gas_Rx" SG_ 131 CcButtnOffPress 1;
BA_ "U_UP375_MY15_Gas_Rx" SG_ 131 CcButtnOffPress 1;
BA_ "U_CD43_MY16_Gas_Rx" SG_ 131 CcButtnOffPress 1;
BA_ "U_CD4_MY14_Gas_Rx" SG_ 131 CcButtnOffPress 1;
BA_ "U_CD4_MY13_Gas_Rx" SG_ 131 CcAsllButtnResPress 1;
BA_ "U_CD42_MY14_Gas_Rx" SG_ 131 CcAsllButtnResPress 1;
BA_ "U_P552_MY15_Gas_Rx" SG_ 131 CcAsllButtnResPress 1;
BA_ "U_S550_MY15_Gas_Rx" SG_ 131 CcAsllButtnResPress 1;
BA_ "U_C489_MY14_Gas_Rx" SG_ 131 CcAsllButtnResPress 1;
BA_ "U_U502_MY15_Gas_Rx" SG_ 131 CcAsllButtnResPress 1;
BA_ "U_UP375_MY15_Gas_Rx" SG_ 131 CcAsllButtnResPress 1;
BA_ "U_CD43_MY16_Gas_Rx" SG_ 131 CcAsllButtnResPress 1;
BA_ "U_CD4_MY14_Gas_Rx" SG_ 131 CcAsllButtnResPress 1;
BA_ "U_CD4_MY13_Gas_Rx" SG_ 131 CcAslButtnSetIncPress 1;
BA_ "U_CD42_MY14_Gas_Rx" SG_ 131 CcAslButtnSetIncPress 1;
BA_ "U_P552_MY15_Gas_Rx" SG_ 131 CcAslButtnSetIncPress 1;
BA_ "U_S550_MY15_Gas_Rx" SG_ 131 CcAslButtnSetIncPress 1;
BA_ "U_C489_MY14_Gas_Rx" SG_ 131 CcAslButtnSetIncPress 1;
BA_ "U_U502_MY15_Gas_Rx" SG_ 131 CcAslButtnSetIncPress 1;
BA_ "U_CD43_MY16_Gas_Rx" SG_ 131 CcAslButtnSetIncPress 1;
BA_ "U_CD4_MY14_Gas_Rx" SG_ 131 CcAslButtnSetIncPress 1;
BA_ "U_CD4_MY13_Gas_Rx" SG_ 131 CcAslButtnSetDecPress 1;
BA_ "U_CD42_MY14_Gas_Rx" SG_ 131 CcAslButtnSetDecPress 1;
BA_ "U_P552_MY15_Gas_Rx" SG_ 131 CcAslButtnSetDecPress 1;
BA_ "U_S550_MY15_Gas_Rx" SG_ 131 CcAslButtnSetDecPress 1;
BA_ "U_C489_MY14_Gas_Rx" SG_ 131 CcAslButtnSetDecPress 1;
BA_ "U_U502_MY15_Gas_Rx" SG_ 131 CcAslButtnSetDecPress 1;
BA_ "U_CD43_MY16_Gas_Rx" SG_ 131 CcAslButtnSetDecPress 1;
BA_ "U_CD4_MY14_Gas_Rx" SG_ 131 CcAslButtnSetDecPress 1;
BA_ "U_CD4_MY13_Gas_Rx" SG_ 131 CcAslButtnResIncPress 1;
BA_ "U_CD42_MY14_Gas_Rx" SG_ 131 CcAslButtnResIncPress 1;
BA_ "U_P552_MY15_Gas_Rx" SG_ 131 CcAslButtnResIncPress 1;
BA_ "U_S550_MY15_Gas_Rx" SG_ 131 CcAslButtnResIncPress 1;
BA_ "U_C489_MY14_Gas_Rx" SG_ 131 CcAslButtnResIncPress 1;
BA_ "U_U502_MY15_Gas_Rx" SG_ 131 CcAslButtnResIncPress 1;
BA_ "U_CD43_MY16_Gas_Rx" SG_ 131 CcAslButtnResIncPress 1;
BA_ "U_CD4_MY14_Gas_Rx" SG_ 131 CcAslButtnResIncPress 1;
BA_ "U_CD4_MY13_Gas_Rx" SG_ 131 CcAslButtnOnPress 1;
BA_ "U_CD42_MY14_Gas_Rx" SG_ 131 CcAslButtnOnPress 1;
BA_ "U_P552_MY15_Gas_Rx" SG_ 131 CcAslButtnOnPress 1;
BA_ "U_S550_MY15_Gas_Rx" SG_ 131 CcAslButtnOnPress 1;
BA_ "U_C489_MY14_Gas_Rx" SG_ 131 CcAslButtnOnPress 1;
BA_ "U_U502_MY15_Gas_Rx" SG_ 131 CcAslButtnOnPress 1;
BA_ "U_CD43_MY16_Gas_Rx" SG_ 131 CcAslButtnOnPress 1;
BA_ "U_CD4_MY14_Gas_Rx" SG_ 131 CcAslButtnOnPress 1;
BA_ "U_CD4_MY13_Gas_Rx" SG_ 131 CcAslButtnIndxIncPress 1;
BA_ "U_CD42_MY14_Gas_Rx" SG_ 131 CcAslButtnIndxIncPress 1;
BA_ "U_P552_MY15_Gas_Rx" SG_ 131 CcAslButtnIndxIncPress 1;
BA_ "U_S550_MY15_Gas_Rx" SG_ 131 CcAslButtnIndxIncPress 1;
BA_ "U_C489_MY14_Gas_Rx" SG_ 131 CcAslButtnIndxIncPress 1;
BA_ "U_U502_MY15_Gas_Rx" SG_ 131 CcAslButtnIndxIncPress 1;
BA_ "U_CD43_MY16_Gas_Rx" SG_ 131 CcAslButtnIndxIncPress 1;
BA_ "U_CD4_MY14_Gas_Rx" SG_ 131 CcAslButtnIndxIncPress 1;
BA_ "U_CD4_MY13_Gas_Rx" SG_ 131 CcAslButtnIndxDecPress 1;
BA_ "U_CD42_MY14_Gas_Rx" SG_ 131 CcAslButtnIndxDecPress 1;
BA_ "U_P552_MY15_Gas_Rx" SG_ 131 CcAslButtnIndxDecPress 1;
BA_ "U_S550_MY15_Gas_Rx" SG_ 131 CcAslButtnIndxDecPress 1;
BA_ "U_C489_MY14_Gas_Rx" SG_ 131 CcAslButtnIndxDecPress 1;
BA_ "U_U502_MY15_Gas_Rx" SG_ 131 CcAslButtnIndxDecPress 1;
BA_ "U_CD43_MY16_Gas_Rx" SG_ 131 CcAslButtnIndxDecPress 1;
BA_ "U_CD4_MY14_Gas_Rx" SG_ 131 CcAslButtnIndxDecPress 1;
BA_ "U_CD4_MY13_Gas_Rx" SG_ 131 CcAslButtnDeny_B_Actl 1;
BA_ "U_CD42_MY14_Gas_Rx" SG_ 131 CcAslButtnDeny_B_Actl 1;
BA_ "U_P552_MY15_Gas_Rx" SG_ 131 CcAslButtnDeny_B_Actl 1;
BA_ "U_S550_MY15_Gas_Rx" SG_ 131 CcAslButtnDeny_B_Actl 1;
BA_ "U_C489_MY14_Gas_Rx" SG_ 131 CcAslButtnDeny_B_Actl 1;
BA_ "U_U502_MY15_Gas_Rx" SG_ 131 CcAslButtnDeny_B_Actl 1;
BA_ "U_CD43_MY16_Gas_Rx" SG_ 131 CcAslButtnDeny_B_Actl 1;
BA_ "U_CD4_MY14_Gas_Rx" SG_ 131 CcAslButtnDeny_B_Actl 1;
BA_ "U_CD4_MY13_Gas_Rx" SG_ 131 CcAslButtnCnclResPress 1;
BA_ "U_CD42_MY14_Gas_Rx" SG_ 131 CcAslButtnCnclResPress 1;
BA_ "U_P552_MY15_Gas_Rx" SG_ 131 CcAslButtnCnclResPress 1;
BA_ "U_S550_MY15_Gas_Rx" SG_ 131 CcAslButtnCnclResPress 1;
BA_ "U_C489_MY14_Gas_Rx" SG_ 131 CcAslButtnCnclResPress 1;
BA_ "U_U502_MY15_Gas_Rx" SG_ 131 CcAslButtnCnclResPress 1;
BA_ "U_CD43_MY16_Gas_Rx" SG_ 131 CcAslButtnCnclResPress 1;
BA_ "U_CD4_MY14_Gas_Rx" SG_ 131 CcAslButtnCnclResPress 1;
BA_ "U_CD4_MY13_Gas_Rx" SG_ 131 CcAslButtnCnclPress 1;
BA_ "U_CD42_MY14_Gas_Rx" SG_ 131 CcAslButtnCnclPress 1;
BA_ "U_P552_MY15_Gas_Rx" SG_ 131 CcAslButtnCnclPress 1;
BA_ "U_S550_MY15_Gas_Rx" SG_ 131 CcAslButtnCnclPress 1;
BA_ "U_C489_MY14_Gas_Rx" SG_ 131 CcAslButtnCnclPress 1;
BA_ "U_U502_MY15_Gas_Rx" SG_ 131 CcAslButtnCnclPress 1;
BA_ "U_CD43_MY16_Gas_Rx" SG_ 131 CcAslButtnCnclPress 1;
BA_ "U_CD4_MY14_Gas_Rx" SG_ 131 CcAslButtnCnclPress 1;
BA_ "WakeupSignal" SG_ 131 HeadLghtHiFlash_D_Stat 1;
BA_ "U_CD4_MY13_Diesel_Rx" SG_ 131 HeadLghtHiFlash_D_Stat 1;
BA_ "U_CD4_MY13_Gas_Rx" SG_ 131 HeadLghtHiFlash_D_Stat 1;
BA_ "U_CD4_MY13_Hev_Rx" SG_ 131 HeadLghtHiFlash_D_Stat 1;
BA_ "U_CD4_MY13_Phev_Rx" SG_ 131 HeadLghtHiFlash_D_Stat 1;
BA_ "U_CD42_MY14_Diesel_Rx" SG_ 131 HeadLghtHiFlash_D_Stat 1;
BA_ "U_CD42_MY14_Gas_Rx" SG_ 131 HeadLghtHiFlash_D_Stat 1;
BA_ "U_P552_MY15_Gas_Rx" SG_ 131 HeadLghtHiFlash_D_Stat 1;
BA_ "U_S550_MY15_Gas_Rx" SG_ 131 HeadLghtHiFlash_D_Stat 1;
BA_ "U_C489_MY14_Gas_Rx" SG_ 131 HeadLghtHiFlash_D_Stat 1;
BA_ "U_U502_MY15_Gas_Rx" SG_ 131 HeadLghtHiFlash_D_Stat 1;
BA_ "U_UP375_MY15_Gas_Rx" SG_ 131 HeadLghtHiFlash_D_Stat 1;
BA_ "U_UP375_MY15_Diesel_Rx" SG_ 131 HeadLghtHiFlash_D_Stat 1;
BA_ "U_CD43_MY16_Gas_Rx" SG_ 131 HeadLghtHiFlash_D_Stat 1;
BA_ "U_CD4_MY14_Diesel_Rx" SG_ 131 HeadLghtHiFlash_D_Stat 1;
BA_ "U_CD4_MY14_Gas_Rx" SG_ 131 HeadLghtHiFlash_D_Stat 1;
BA_ "U_CD4_MY14_Hev_Rx" SG_ 131 HeadLghtHiFlash_D_Stat 1;
BA_ "U_CD4_MY14_Phev_Rx" SG_ 131 HeadLghtHiFlash_D_Stat 1;
BA_ "GenSigStartValue" SG_ 131 WiprFront_D_Stat 15;
BA_ "U_CD4_MY13_Diesel_Rx" SG_ 131 WiprFront_D_Stat 1;
BA_ "U_CD4_MY13_Gas_Rx" SG_ 131 WiprFront_D_Stat 1;
BA_ "U_CD4_MY13_Hev_Rx" SG_ 131 WiprFront_D_Stat 1;
BA_ "U_CD4_MY13_Phev_Rx" SG_ 131 WiprFront_D_Stat 1;
BA_ "U_CD42_MY14_Diesel_Rx" SG_ 131 WiprFront_D_Stat 1;
BA_ "U_CD42_MY14_Gas_Rx" SG_ 131 WiprFront_D_Stat 1;
BA_ "U_P552_MY15_Gas_Rx" SG_ 131 WiprFront_D_Stat 1;
BA_ "U_S550_MY15_Gas_Rx" SG_ 131 WiprFront_D_Stat 1;
BA_ "U_C489_MY14_Gas_Rx" SG_ 131 WiprFront_D_Stat 1;
BA_ "U_U502_MY15_Gas_Rx" SG_ 131 WiprFront_D_Stat 1;
BA_ "U_CD43_MY16_Gas_Rx" SG_ 131 WiprFront_D_Stat 1;
BA_ "U_CD4_MY14_Gas_Rx" SG_ 131 WiprFront_D_Stat 1;
BA_ "U_UP375_MY15_Gas_Rx" SG_ 131 WiprFront_D_Stat 1;
BA_ "U_UP375_MY15_Diesel_Rx" SG_ 131 WiprFront_D_Stat 1;
BA_ "U_CD4_MY14_Diesel_Rx" SG_ 131 WiprFront_D_Stat 1;
BA_ "U_CD4_MY14_Hev_Rx" SG_ 131 WiprFront_D_Stat 1;
BA_ "U_CD4_MY14_Phev_Rx" SG_ 131 WiprFront_D_Stat 1;
BA_ "WakeupSignal" SG_ 131 TurnLghtSwtch_D_Stat 1;
BA_ "CrossOver_InfoCAN" SG_ 131 TurnLghtSwtch_D_Stat 1;
BA_ "U_CD4_MY13_Diesel_Rx" SG_ 131 TurnLghtSwtch_D_Stat 1;
BA_ "U_CD4_MY13_Gas_Rx" SG_ 131 TurnLghtSwtch_D_Stat 1;
BA_ "U_CD4_MY13_Hev_Rx" SG_ 131 TurnLghtSwtch_D_Stat 1;
BA_ "U_CD4_MY13_Phev_Rx" SG_ 131 TurnLghtSwtch_D_Stat 1;
BA_ "U_CD42_MY14_Diesel_Rx" SG_ 131 TurnLghtSwtch_D_Stat 1;
BA_ "U_CD42_MY14_Gas_Rx" SG_ 131 TurnLghtSwtch_D_Stat 1;
BA_ "U_P552_MY15_Gas_Rx" SG_ 131 TurnLghtSwtch_D_Stat 1;
BA_ "U_S550_MY15_Gas_Rx" SG_ 131 TurnLghtSwtch_D_Stat 1;
BA_ "U_C489_MY14_Gas_Rx" SG_ 131 TurnLghtSwtch_D_Stat 1;
BA_ "U_U502_MY15_Gas_Rx" SG_ 131 TurnLghtSwtch_D_Stat 1;
BA_ "U_UP375_MY15_Gas_Rx" SG_ 131 TurnLghtSwtch_D_Stat 1;
BA_ "U_UP375_MY15_Diesel_Rx" SG_ 131 TurnLghtSwtch_D_Stat 1;
BA_ "U_CD43_MY16_Gas_Rx" SG_ 131 TurnLghtSwtch_D_Stat 1;
BA_ "U_CD4_MY14_Diesel_Rx" SG_ 131 TurnLghtSwtch_D_Stat 1;
BA_ "U_CD4_MY14_Gas_Rx" SG_ 131 TurnLghtSwtch_D_Stat 1;
BA_ "U_CD4_MY14_Hev_Rx" SG_ 131 TurnLghtSwtch_D_Stat 1;
BA_ "U_CD4_MY14_Phev_Rx" SG_ 131 TurnLghtSwtch_D_Stat 1;
BA_ "GenSigStartValue" SG_ 131 LghtAmb_D_Sns 7;
BA_ "U_CD4_MY13_Diesel_Rx" SG_ 131 LghtAmb_D_Sns 1;
BA_ "U_CD4_MY13_Gas_Rx" SG_ 131 LghtAmb_D_Sns 1;
BA_ "U_CD4_MY13_Hev_Rx" SG_ 131 LghtAmb_D_Sns 1;
BA_ "U_CD4_MY13_Phev_Rx" SG_ 131 LghtAmb_D_Sns 1;
BA_ "U_CD42_MY14_Diesel_Rx" SG_ 131 LghtAmb_D_Sns 1;
BA_ "U_CD42_MY14_Gas_Rx" SG_ 131 LghtAmb_D_Sns 1;
BA_ "U_P552_MY15_Gas_Rx" SG_ 131 LghtAmb_D_Sns 1;
BA_ "U_S550_MY15_Gas_Rx" SG_ 131 LghtAmb_D_Sns 1;
BA_ "U_C489_MY14_Gas_Rx" SG_ 131 LghtAmb_D_Sns 1;
BA_ "U_U502_MY15_Gas_Rx" SG_ 131 LghtAmb_D_Sns 1;
BA_ "U_UP375_MY15_Gas_Rx" SG_ 131 LghtAmb_D_Sns 1;
BA_ "U_UP375_MY15_Diesel_Rx" SG_ 131 LghtAmb_D_Sns 1;
BA_ "U_CD43_MY16_Gas_Rx" SG_ 131 LghtAmb_D_Sns 1;
BA_ "U_CD4_MY14_Diesel_Rx" SG_ 131 LghtAmb_D_Sns 1;
BA_ "U_CD4_MY14_Gas_Rx" SG_ 131 LghtAmb_D_Sns 1;
BA_ "U_CD4_MY14_Hev_Rx" SG_ 131 LghtAmb_D_Sns 1;
BA_ "U_CD4_MY14_Phev_Rx" SG_ 131 LghtAmb_D_Sns 1;
BA_ "WakeupSignal" SG_ 819 Pasngr_Lock_Sw_Stat 1;
BA_ "U_CD4_MY13_Diesel_Rx" SG_ 819 Pasngr_Lock_Sw_Stat 1;
BA_ "U_CD4_MY13_Gas_Rx" SG_ 819 Pasngr_Lock_Sw_Stat 1;
BA_ "U_CD4_MY13_Hev_Rx" SG_ 819 Pasngr_Lock_Sw_Stat 1;
BA_ "U_CD4_MY13_Phev_Rx" SG_ 819 Pasngr_Lock_Sw_Stat 1;
BA_ "U_CD42_MY14_Diesel_Rx" SG_ 819 Pasngr_Lock_Sw_Stat 1;
BA_ "U_CD42_MY14_Gas_Rx" SG_ 819 Pasngr_Lock_Sw_Stat 1;
BA_ "U_P552_MY15_Gas_Rx" SG_ 819 Pasngr_Lock_Sw_Stat 1;
BA_ "U_S550_MY15_Gas_Rx" SG_ 819 Pasngr_Lock_Sw_Stat 1;
BA_ "U_C489_MY14_Gas_Rx" SG_ 819 Pasngr_Lock_Sw_Stat 1;
BA_ "U_U502_MY15_Gas_Rx" SG_ 819 Pasngr_Lock_Sw_Stat 1;
BA_ "U_UP375_MY15_Gas_Rx" SG_ 819 Pasngr_Lock_Sw_Stat 1;
BA_ "U_UP375_MY15_Diesel_Rx" SG_ 819 Pasngr_Lock_Sw_Stat 1;
BA_ "U_CD43_MY16_Gas_Rx" SG_ 819 Pasngr_Lock_Sw_Stat 1;
BA_ "U_CD4_MY14_Diesel_Rx" SG_ 819 Pasngr_Lock_Sw_Stat 1;
BA_ "U_CD4_MY14_Gas_Rx" SG_ 819 Pasngr_Lock_Sw_Stat 1;
BA_ "U_CD4_MY14_Hev_Rx" SG_ 819 Pasngr_Lock_Sw_Stat 1;
BA_ "U_CD4_MY14_Phev_Rx" SG_ 819 Pasngr_Lock_Sw_Stat 1;
BA_ "WakeupSignal" SG_ 819 Pasngr_Lock_Sw_Cnt 1;
BA_ "U_CD4_MY13_Diesel_Rx" SG_ 819 Pasngr_Lock_Sw_Cnt 1;
BA_ "U_CD4_MY13_Gas_Rx" SG_ 819 Pasngr_Lock_Sw_Cnt 1;
BA_ "U_CD4_MY13_Hev_Rx" SG_ 819 Pasngr_Lock_Sw_Cnt 1;
BA_ "U_CD4_MY13_Phev_Rx" SG_ 819 Pasngr_Lock_Sw_Cnt 1;
BA_ "U_CD42_MY14_Diesel_Rx" SG_ 819 Pasngr_Lock_Sw_Cnt 1;
BA_ "U_CD42_MY14_Gas_Rx" SG_ 819 Pasngr_Lock_Sw_Cnt 1;
BA_ "U_P552_MY15_Gas_Rx" SG_ 819 Pasngr_Lock_Sw_Cnt 1;
BA_ "U_S550_MY15_Gas_Rx" SG_ 819 Pasngr_Lock_Sw_Cnt 1;
BA_ "U_C489_MY14_Gas_Rx" SG_ 819 Pasngr_Lock_Sw_Cnt 1;
BA_ "U_U502_MY15_Gas_Rx" SG_ 819 Pasngr_Lock_Sw_Cnt 1;
BA_ "U_UP375_MY15_Gas_Rx" SG_ 819 Pasngr_Lock_Sw_Cnt 1;
BA_ "U_UP375_MY15_Diesel_Rx" SG_ 819 Pasngr_Lock_Sw_Cnt 1;
BA_ "U_CD43_MY16_Gas_Rx" SG_ 819 Pasngr_Lock_Sw_Cnt 1;
BA_ "U_CD4_MY14_Diesel_Rx" SG_ 819 Pasngr_Lock_Sw_Cnt 1;
BA_ "U_CD4_MY14_Gas_Rx" SG_ 819 Pasngr_Lock_Sw_Cnt 1;
BA_ "U_CD4_MY14_Hev_Rx" SG_ 819 Pasngr_Lock_Sw_Cnt 1;
BA_ "U_CD4_MY14_Phev_Rx" SG_ 819 Pasngr_Lock_Sw_Cnt 1;
BA_ "WakeupSignal" SG_ 819 ChildLckFdbckRp_B_Stat 1;
BA_ "U_CD4_MY13_Diesel_Rx" SG_ 819 ChildLckFdbckRp_B_Stat 1;
BA_ "U_CD4_MY13_Gas_Rx" SG_ 819 ChildLckFdbckRp_B_Stat 1;
BA_ "U_CD4_MY13_Hev_Rx" SG_ 819 ChildLckFdbckRp_B_Stat 1;
BA_ "U_CD4_MY13_Phev_Rx" SG_ 819 ChildLckFdbckRp_B_Stat 1;
BA_ "U_CD42_MY14_Diesel_Rx" SG_ 819 ChildLckFdbckRp_B_Stat 1;
BA_ "U_CD42_MY14_Gas_Rx" SG_ 819 ChildLckFdbckRp_B_Stat 1;
BA_ "U_P552_MY15_Gas_Rx" SG_ 819 ChildLckFdbckRp_B_Stat 1;
BA_ "U_S550_MY15_Gas_Rx" SG_ 819 ChildLckFdbckRp_B_Stat 1;
BA_ "U_C489_MY14_Gas_Rx" SG_ 819 ChildLckFdbckRp_B_Stat 1;
BA_ "U_U502_MY15_Gas_Rx" SG_ 819 ChildLckFdbckRp_B_Stat 1;
BA_ "U_UP375_MY15_Gas_Rx" SG_ 819 ChildLckFdbckRp_B_Stat 1;
BA_ "U_UP375_MY15_Diesel_Rx" SG_ 819 ChildLckFdbckRp_B_Stat 1;
BA_ "U_CD43_MY16_Gas_Rx" SG_ 819 ChildLckFdbckRp_B_Stat 1;
BA_ "U_CD4_MY14_Diesel_Rx" SG_ 819 ChildLckFdbckRp_B_Stat 1;
BA_ "U_CD4_MY14_Gas_Rx" SG_ 819 ChildLckFdbckRp_B_Stat 1;
BA_ "U_CD4_MY14_Hev_Rx" SG_ 819 ChildLckFdbckRp_B_Stat 1;
BA_ "U_CD4_MY14_Phev_Rx" SG_ 819 ChildLckFdbckRp_B_Stat 1;
VAL_ 90 BrkSwtchPos_B_ActlGsm 1 "Yes" 0 "No" ;
VAL_ 90 TrnValidGearRq_D_Stat 3 "Valid_Request" 2 "Valid_Degraded_Request" 1 "Invalid_Request" 0 "No_Request" ;
VAL_ 90 TrnGearButtn_U_Actl 255 "Fault" ;
VAL_ 90 TrnGearButtn_B_ActlR2 1 "Yes" 0 "No" ;
VAL_ 90 TrnGearButtn_B_ActlR1 1 "Yes" 0 "No" ;
VAL_ 90 TrnGearButtn_B_ActlR0 1 "Yes" 0 "No" ;
VAL_ 90 TrnGearButtn_B_ActlP2 1 "Yes" 0 "No" ;
VAL_ 90 TrnGearButtn_B_ActlP1 1 "Yes" 0 "No" ;
VAL_ 90 TrnGearButtn_B_ActlP0 1 "Yes" 0 "No" ;
VAL_ 90 TrnGearButtn_B_ActlN2 1 "Yes" 0 "No" ;
VAL_ 90 TrnGearButtn_B_ActlN1 1 "Yes" 0 "No" ;
VAL_ 90 TrnGearButtn_B_ActlN0 1 "Yes" 0 "No" ;
VAL_ 90 TrnGearButtn_B_ActlM2 1 "Yes" 0 "No" ;
VAL_ 90 TrnGearButtn_B_ActlM1 1 "Yes" 0 "No" ;
VAL_ 90 TrnGearButtn_B_ActlM0 1 "Yes" 0 "No" ;
VAL_ 90 TrnGearButtn_B_ActlD2 1 "Yes" 0 "No" ;
VAL_ 90 TrnGearButtn_B_ActlD1 1 "Yes" 0 "No" ;
VAL_ 90 TrnGearButtn_B_ActlD0 1 "Yes" 0 "No" ;
VAL_ 90 TrnBtsiOvrrd_B_Stat 1 "Override" 0 "Null" ;
VAL_ 90 DrQltyDrv_D_StatGsm 7 "Faulty" 6 "NoDataExists" 5 "NotUsed2" 4 "NotUsed1" 3 "ClosedDegraded" 2 "OpenDegraded" 1 "ClosedOkay" 0 "OpenOkay" ;
VAL_ 90 TrnGsmNtmState_D_Actl 3 "Faulty" 2 "Neutral_Tow_Mode" 1 "Car_Wash_Mode" 0 "None" ;
VAL_ 90 TrnGear_D_RqDrv 31 "Fault" 30 "NotUsed_25" 29 "NotUsed_24" 28 "NotUsed_23" 27 "NotUsed_22" 26 "Return_to_Park" 25 "NotUsed_20" 24 "NotUsed_19" 23 "NotUsed_18" 22 "NotUsed_17" 21 "Return_To_Park" 20 "NotUsed_15" 19 "NotUsed_14" 18 "NotUsed_13" 17 "NotUsed_12" 16 "Manual" 15 "Not_Used11" 14 "Not_Used10" 13 "NotUsed_9" 12 "NotUsed_8" 11 "NotUsed_7" 10 "NotUsed_6" 9 "NotUsed_5" 8 "Drive" 7 "NotUsed_4" 6 "NotUsed_3" 5 "NotUsed_2" 4 "Neutral" 3 "NotUsed_1" 2 "Reverse" 1 "Park" 0 "No_Gear" ;
VAL_ 902 PrmtrAlrmWarnRq_No_Actl_UB 1 "Fresh_data" 0 "Unchanged_data" ;
VAL_ 902 PrmtrAlrmTrgRq_No_Actl_UB 1 "Fresh_data" 0 "Unchanged_data" ;
VAL_ 902 PrmtrAlrmWarn_B_Rq_UB 1 "Fresh_data" 0 "Unchanged_data" ;
VAL_ 902 RollCode_No_ActlRsm_UB 1 "Fresh_data" 0 "Unchanged_data" ;
VAL_ 902 PrmtrAlrmTrg_B_Rq_UB 1 "Fresh_data" 0 "Unchanged_data" ;
VAL_ 902 PanicRq_No_ActlRsm_UB 1 "Fresh_data" 0 "Unchanged_data" ;
VAL_ 902 Panic_D_RqRsm_UB 1 "Fresh_data" 0 "Unchanged_data" ;
VAL_ 902 CellLockRq_No_ActlRsm_UB 1 "Fresh_data" 0 "Unchanged_data" ;
VAL_ 902 PrmtrAlrmWarn_B_Rq 1 "Active" 0 "Null" ;
VAL_ 902 PrmtrAlrmTrg_B_Rq 1 "Active" 0 "Null" ;
VAL_ 902 Panic_D_RqRsm 3 "NotUsed" 2 "On" 1 "Off" 0 "Null" ;
VAL_ 902 CellLock_D_RqRsm 7 "NotUsed3" 6 "NotUsed2" 5 "NotUsed1" 4 "TrunkRelPopGlassLgCargo" 3 "LockAllDoorsandTailgate" 2 "UnlockDriversDoor" 1 "UnlockAllDoorsandTailgate" 0 "NoRequest" ;
VAL_ 902 CellLock_D_RqRsm_UB 1 "Fresh_data" 0 "Unchanged_data" ;
VAL_ 740 PtWakeupActv2_B_Rq 1 "On" 0 "Off" ;
VAL_ 748 PtWakeupActv3_B_Rq 1 "On" 0 "Off" ;
VAL_ 389 PreCondActv_B_Actl 1 "On" 0 "Off" ;
VAL_ 135 McGlblClkAdj_B_Rq 1 "Request" 0 "NoRequest" ;
VAL_ 134 DispGlblClkAdj_B_Rq 1 "Request" 0 "NoRequest" ;
VAL_ 836 Foh_D_Stat 7 "Unused3" 6 "Unused2" 5 "Unused1" 4 "Stopping" 3 "Running" 2 "Starting" 1 "Prestart" 0 "Off" ;
VAL_ 939 PrkAidChime_D_Stat 3 "Fault" 2 "No_Data_Exists" 1 "On" 0 "Off" ;
VAL_ 939 PrkAidSnsRlCntr_D_Stat 15 "Zone_15" 14 "Zone_14" 13 "Zone_13" 12 "Zone_12" 11 "Zone_11" 10 "Zone_10" 9 "Zone_9" 8 "Zone_8" 7 "Zone_7" 6 "Zone_6" 5 "Zone_5" 4 "Zone_4" 3 "Zone_3" 2 "Zone_2" 1 "Zone_1" 0 "Off" ;
VAL_ 939 PrkAidSnsRrSide_D_Stat 15 "Zone_15" 14 "Zone_14" 13 "Zone_13" 12 "Zone_12" 11 "Zone_11" 10 "Zone_10" 9 "Zone_9" 8 "Zone_8" 7 "Zone_7" 6 "Zone_6" 5 "Zone_5" 4 "Zone_4" 3 "Zone_3" 2 "Zone_2" 1 "Zone_1" 0 "Off" ;
VAL_ 939 PrkAidSnsRrCrnr_D_Stat 15 "Zone_15" 14 "Zone_14" 13 "Zone_13" 12 "Zone_12" 11 "Zone_11" 10 "Zone_10" 9 "Zone_9" 8 "Zone_8" 7 "Zone_7" 6 "Zone_6" 5 "Zone_5" 4 "Zone_4" 3 "Zone_3" 2 "Zone_2" 1 "Zone_1" 0 "Off" ;
VAL_ 939 PrkAidSnsRrCntr_D_Stat 15 "Zone_15" 14 "Zone_14" 13 "Zone_13" 12 "Zone_12" 11 "Zone_11" 10 "Zone_10" 9 "Zone_9" 8 "Zone_8" 7 "Zone_7" 6 "Zone_6" 5 "Zone_5" 4 "Zone_4" 3 "Zone_3" 2 "Zone_2" 1 "Zone_1" 0 "Off" ;
VAL_ 939 PrkAidSnsRlSide_D_Stat 15 "Zone_15" 14 "Zone_14" 13 "Zone_13" 12 "Zone_12" 11 "Zone_11" 10 "Zone_10" 9 "Zone_9" 8 "Zone_8" 7 "Zone_7" 6 "Zone_6" 5 "Zone_5" 4 "Zone_4" 3 "Zone_3" 2 "Zone_2" 1 "Zone_1" 0 "Off" ;
VAL_ 939 PrkAidSnsRlCrnr_D_Stat 15 "Zone_15" 14 "Zone_14" 13 "Zone_13" 12 "Zone_12" 11 "Zone_11" 10 "Zone_10" 9 "Zone_9" 8 "Zone_8" 7 "Zone_7" 6 "Zone_6" 5 "Zone_5" 4 "Zone_4" 3 "Zone_3" 2 "Zone_2" 1 "Zone_1" 0 "Off" ;
VAL_ 939 PrkAidRear_D_Stat 3 "Faulted" 2 "Unused" 1 "Enabled" 0 "Disabled" ;
VAL_ 939 PrkAidFront_D_Stat 3 "Faulted" 2 "Unused" 1 "Enabled" 0 "Disabled" ;
VAL_ 939 PrkAid_D_Falt 7 "NotUsed2" 6 "NotUsed1" 5 "Failure_Front_PSM_Sensors" 4 "No_Data_Exists" 3 "Failure_Rear_Sensors" 2 "Speaker_Fault" 1 "ECU_Fault" 0 "No_Fault" ;
VAL_ 952 Tire_Press_IRR_Data 65535 "Not_Supported" 65534 "Invalid" 65533 "Unknown" ;
VAL_ 952 Tire_Press_ILR_Data 65535 "Not_Supported" 65534 "Invalid" 65533 "Unknown" ;
VAL_ 1095 VehLck_D_Dsply 3 "Faulty" 2 "Unlock" 1 "Lock" 0 "Off" ;
VAL_ 1095 HeadLghtOn_D_Rq 7 "NotUsed2" 6 "NotUsed1" 5 "DrlBoth" 4 "DrlRight" 3 "DrlLeft" 2 "High" 1 "Low" 0 "Off" ;
VAL_ 1095 PepsKeyActv_D_Stat 15 "NotUsed11" 14 "NotUsed10" 13 "NotUsed9" 12 "NotUsed8" 11 "NotUsed7" 10 "NotUsed6" 9 "NotUsed5" 8 "Key4Active" 7 "NotUsed4" 6 "NotUsed3" 5 "NotUsed2" 4 "Key3Active" 3 "NotUsed1" 2 "Key2Active" 1 "Key1Active" 0 "NoKeyActive" ;
VAL_ 1094 CellRstrt_D_Rq 3 "NotUsed" 2 "RemoteCancel" 1 "RemoteStart" 0 "NoRequest" ;
VAL_ 1094 CellPanic_D_Rq 3 "NotUsed" 2 "On" 1 "Off" 0 "Null" ;
VAL_ 1094 CellLock_D_Rq 7 "NotUsed3" 6 "NotUsed2" 5 "NotUsed1" 4 "TrunkRelPopGlassLgCargo" 3 "LockAllDoorsandTailgate" 2 "UnlockDriversDoor" 1 "UnlockAllDoorsandTailgate" 0 "NoRequest" ;
VAL_ 1094 CellChirp_D_Rq 7 "NotUsed3" 6 "NotUsed2" 5 "NotUsed1" 4 "Honk" 3 "ChirpHonk" 2 "Chirp2" 1 "Chirp1" 0 "NoRequest" ;
VAL_ 320 PwSldDrIntSwL_B_Stat 1 "Pressed" 0 "Null" ;
VAL_ 320 LPwrSlideDr_Unlock_Rq 1 "Unlock" 0 "Null" ;
VAL_ 313 PwSldDrIntSwR_B_Stat 1 "Pressed" 0 "Null" ;
VAL_ 313 RPwrSlideDr_Unlock_Rq 1 "Unlock" 0 "Null" ;
VAL_ 993 EmButtn_D_Stat 7 "ButtonAssociationFailed" 6 "ButtonAssociationExited" 5 "ButtonAssociationEntered" 4 "Button4Pressed" 3 "Button3Pressed" 2 "Button2Pressed" 1 "Button1Pressed" 0 "Null" ;
VAL_ 993 PersStore_D_Actl 3 "Unused" 2 "Null" 1 "InProgress" 0 "Complete" ;
VAL_ 993 MemSwtch_D_RqRecall 7 "Unused_3" 6 "Unused_2" 5 "Unused_1" 4 "PERS_4" 3 "PERS_3" 2 "PERS_2" 1 "PERS_1" 0 "Null" ;
VAL_ 993 MemSwtch_D_RqAssoc 7 "Unused_3" 6 "Unused_2" 5 "Unused_1" 4 "PERS_4" 3 "PERS_3" 2 "PERS_2" 1 "PERS_1" 0 "Null" ;
VAL_ 993 PersIndexDsm_D_Actl 7 "Unused_3" 6 "Unused_2" 5 "Unused_1" 4 "Vehicle" 3 "PERS_4" 2 "PERS_3" 1 "PERS_2" 0 "PERS_1" ;
VAL_ 131 WiprFrontSwtch_D_Stat 15 "NotUsed6" 14 "NotUsed5" 13 "NotUsed4" 12 "NotUsed3" 11 "NotUsed2" 10 "NotUsed1" 9 "PositionNotDetermined" 8 "High" 7 "Low" 6 "Position6" 5 "Position5" 4 "Position4" 3 "Position3" 2 "Position2" 1 "Position1" 0 "Off" ;
VAL_ 131 HeadLghtHiCtrl_D_RqAhb 7 "NotUsed2" 6 "NotUsed1" 5 "Auto_HiBeam" 4 "Auto_LoBeam" 3 "Flash" 2 "Man_HiBeam" 1 "Man_LoBeam" 0 "Null" ;
VAL_ 131 HeadLghtHiOn_B_StatAhb 1 "On" 0 "Off" ;
VAL_ 131 AhbStat_B_Dsply 1 "On" 0 "Off" ;
VAL_ 131 HeadLghtHiFlash_D_Actl 3 "NotUsed" 2 "High" 1 "Flash_to_Pass" 0 "Null" ;
VAL_ 131 AccButtnGapIncPress 1 "Button_Pressed" 0 "Button_Not_Pressed" ;
VAL_ 131 AccButtnGapDecPress 1 "Button_Pressed" 0 "Button_Not_Pressed" ;
VAL_ 131 AslButtnOnOffPress 1 "Button_Pressed" 0 "Button_Not_Pressed" ;
VAL_ 131 AslButtnOnOffCnclPress 1 "Button_Pressed" 0 "Button_Not_Pressed" ;
VAL_ 131 CcButtnOnPress 1 "Button_Pressed" 0 "Button_Not_Pressed" ;
VAL_ 131 CcButtnOnOffPress 1 "Button_Pressed" 0 "Button_Not_Pressed" ;
VAL_ 131 CcButtnOnOffCnclPress 1 "Button_Pressed" 0 "Button_Not_Pressed" ;
VAL_ 131 CcButtnOffPress 1 "Button_Pressed" 0 "Button_Not_Pressed" ;
VAL_ 131 CcAsllButtnResPress 1 "Button_Pressed" 0 "Button_Not_Pressed" ;
VAL_ 131 CcAslButtnSetPress 1 "Button_Pressed" 0 "Button_Not_Pressed" ;
VAL_ 131 CcAslButtnSetIncPress 1 "Button_Pressed" 0 "Button_Not_Pressed" ;
VAL_ 131 CcAslButtnSetDecPress 1 "Button_Pressed" 0 "Button_Not_Pressed" ;
VAL_ 131 CcAslButtnResIncPress 1 "Button_Pressed" 0 "Button_Not_Pressed" ;
VAL_ 131 CcAslButtnResDecPress 1 "Button_Pressed" 0 "Button_Not_Pressed" ;
VAL_ 131 CcAslButtnOnPress 1 "Button_Pressed" 0 "Button_Not_Pressed" ;
VAL_ 131 CcAslButtnOnOffCncl 1 "Button_Pressed" 0 "Button_Not_Pressed" ;
VAL_ 131 CcAslButtnOffCnclPress 1 "Button_Pressed" 0 "Button_Not_Pressed" ;
VAL_ 131 CcAslButtnIndxIncPress 1 "Button_Pressed" 0 "Button_Not_Pressed" ;
VAL_ 131 CcAslButtnIndxDecPress 1 "Button_Pressed" 0 "Button_Not_Pressed" ;
VAL_ 131 CcAslButtnDeny_B_Actl 1 "Yes" 0 "No" ;
VAL_ 131 CcAslButtnCnclResPress 1 "Button_Pressed" 0 "Button_Not_Pressed" ;
VAL_ 131 CcAslButtnCnclPress 1 "Button_Pressed" 0 "Button_Not_Pressed" ;
VAL_ 131 HeadLghtHiFlash_D_Stat 3 "NotUsed" 2 "High" 1 "Flash_to_Pass" 0 "Null" ;
VAL_ 131 WiprFront_D_Stat 15 "NO_DATA_EXISTS" 14 "STALLED" 13 "RESERVED" 12 "AUTO_ADJUST" 11 "COURTESYWIPE" 10 "AUTO_HIGH" 9 "AUTO_LOW" 8 "WASH" 7 "MIST_FLICK" 6 "MAN_HIGH" 5 "MAN_LOW" 4 "MAN_INT_ON" 3 "MAN_INT_OFF" 2 "OFF_MOVING" 1 "AUTO_OFF" 0 "OFF" ;
VAL_ 131 TurnLghtSwtch_D_Stat 3 "Unused_Treat_As_Off" 2 "Right" 1 "Left" 0 "Off" ;
VAL_ 131 LghtAmb_D_Sns 7 "No_Data_Exists" 6 "Unused2" 5 "Unused1" 4 "Tunnel_Off" 3 "Tunnel_On" 2 "Twilight" 1 "Light" 0 "Dark" ;
VAL_ 131 LaSwtchPos_D_Stat 3 "Fault" 2 "Unused" 1 "Pressed" 0 "Open" ;
VAL_ 819 Pasngr_Lock_Sw_Stat 3 "Invalid" 2 "Unlock" 1 "Lock" 0 "Null" ;
VAL_ 819 ChildLckFdbckRp_B_Stat 1 "Locked" 0 "Unlock" ;
